VERSION ""

NS_ :

BS_:

BU_: EHR_Spare FEHR_3 PTO_SpeedSelector Dummy_Node_Ch2 FEHR_2 TrailerBrake OffBoardDiagnosticTool1_Ch2 PowerTakeOff_Ch2 Transmission1_Ch2 FEHR_1 REHR_5 REHR_4 REHR_3 REHR_2 REHR_1 InstrumentCluster_Ch2 ManagementComputer_Ch2 GWAY_OnBoardDiagnosticUnit_Ch2 GWAY_OffBoardDiagTool1_VB1_Ch2 GWAY_Engine1_Ch2 GWAY_CabDisplay1_Ch2 AuxiliaryValveControl_Ch2

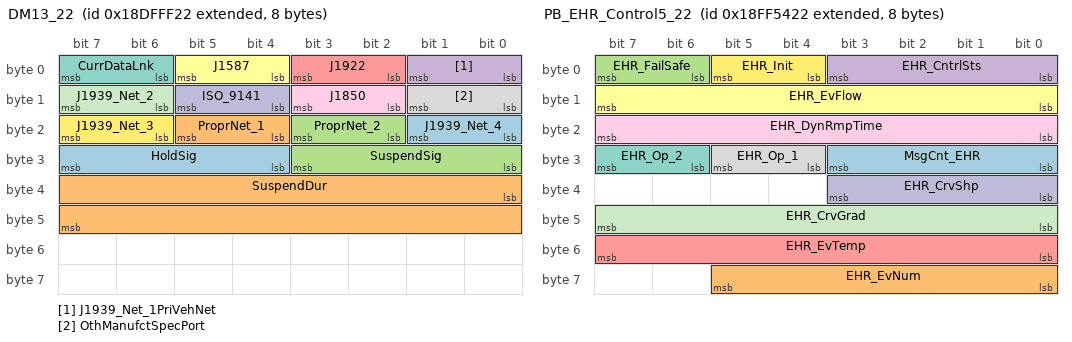
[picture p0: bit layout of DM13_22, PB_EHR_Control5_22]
BO_ 2564816674 DM13_22: 8 AuxiliaryValveControl_Ch2
 SG_ J1939_Net_4 : 16|2@1+ (1,0) [0|3] ""  FEHR_3,FEHR_2,FEHR_1,REHR_5,REHR_4,REHR_3,REHR_2,REHR_1
 SG_ SuspendDur : 32|16@1+ (1,0) [0|64255] "s"  FEHR_3,FEHR_2,FEHR_1,REHR_5,REHR_4,REHR_3,REHR_2,REHR_1
 SG_ SuspendSig : 24|4@1+ (1,0) [0|15] ""  FEHR_3,FEHR_2,FEHR_1,REHR_5,REHR_4,REHR_3,REHR_2,REHR_1
 SG_ J1939_Net_1PriVehNet : 0|2@1+ (1,0) [0|3] ""  FEHR_3,FEHR_2,FEHR_1,REHR_5,REHR_4,REHR_3,REHR_2,REHR_1
 SG_ J1922 : 2|2@1+ (1,0) [0|3] ""  FEHR_3,FEHR_2,FEHR_1,REHR_5,REHR_4,REHR_3,REHR_2,REHR_1
 SG_ J1587 : 4|2@1+ (1,0) [0|3] ""  FEHR_3,FEHR_2,FEHR_1,REHR_5,REHR_4,REHR_3,REHR_2,REHR_1
 SG_ CurrDataLnk : 6|2@1+ (1,0) [0|3] ""  FEHR_3,FEHR_2,FEHR_1,REHR_5,REHR_4,REHR_3,REHR_2,REHR_1
 SG_ OthManufctSpecPort : 8|2@1+ (1,0) [0|3] ""  FEHR_3,FEHR_2,FEHR_1,REHR_5,REHR_4,REHR_3,REHR_2,REHR_1
 SG_ J1850 : 10|2@1+ (1,0) [0|3] ""  FEHR_3,FEHR_2,FEHR_1,REHR_5,REHR_4,REHR_3,REHR_2,REHR_1
 SG_ ISO_9141 : 12|2@1+ (1,0) [0|3] ""  FEHR_3,FEHR_2,FEHR_1,REHR_5,REHR_4,REHR_3,REHR_2,REHR_1
 SG_ J1939_Net_2 : 14|2@1+ (1,0) [0|3] ""  FEHR_3,FEHR_2,FEHR_1,REHR_5,REHR_4,REHR_3,REHR_2,REHR_1
 SG_ J1939_Net_3 : 22|2@1+ (1,0) [0|3] ""  FEHR_3,FEHR_2,FEHR_1,REHR_5,REHR_4,REHR_3,REHR_2,REHR_1
 SG_ HoldSig : 28|4@1+ (1,0) [0|15] ""  FEHR_3,FEHR_2,FEHR_1,REHR_5,REHR_4,REHR_3,REHR_2,REHR_1
 SG_ ProprNet_1 : 20|2@1+ (1,0) [0|3] ""  FEHR_3,FEHR_2,FEHR_1,REHR_5,REHR_4,REHR_3,REHR_2,REHR_1
 SG_ ProprNet_2 : 18|2@1+ (1,0) [0|3] ""  FEHR_3,FEHR_2,FEHR_1,REHR_5,REHR_4,REHR_3,REHR_2,REHR_1

BO_ 2566865698 PB_EHR_ParameterControl_22: 8 AuxiliaryValveControl_Ch2
 SG_ EHR_Err_21_22 m19 : 21|1@1+ (1,0) [0|1] ""  FEHR_2,FEHR_1,REHR_5,REHR_4,REHR_3,REHR_2,REHR_1,FEHR_3
 SG_ EHR_Err_23 m19 : 22|1@1+ (1,0) [0|1] ""  FEHR_2,FEHR_1,REHR_5,REHR_4,REHR_3,REHR_2,REHR_1,FEHR_3
 SG_ EHR_EvNumNew m21 : 24|8@1+ (1,0) [0|255] ""  FEHR_2,FEHR_1,REHR_5,REHR_4,REHR_3,REHR_2,REHR_1,FEHR_3
 SG_ EHR_EvNumParamMux_12 m18 : 16|8@1+ (1,0) [0|255] ""  FEHR_2,FEHR_1,REHR_5,REHR_4,REHR_3,REHR_2,REHR_1,FEHR_3
 SG_ EHR_EvNumParamMux_15 m21 : 16|8@1+ (1,0) [0|255] ""  FEHR_2,FEHR_1,REHR_5,REHR_4,REHR_3,REHR_2,REHR_1,FEHR_3
 SG_ EHR_EvNumParamMux_31 m49 : 16|8@1+ (1,0) [0|255] ""  FEHR_2,FEHR_1,REHR_5,REHR_4,REHR_3,REHR_2,REHR_1,FEHR_3
 SG_ EHR_EvNumParamMux_32 m50 : 16|8@1+ (1,0) [0|255] ""  FEHR_2,FEHR_1,REHR_5,REHR_4,REHR_3,REHR_2,REHR_1,FEHR_3
 SG_ EHR_EvNumParamMux_50 m80 : 16|8@1+ (1,0) [0|255] ""  FEHR_2,FEHR_1,REHR_5,REHR_4,REHR_3,REHR_2,REHR_1,FEHR_3
 SG_ EHR_EvNumParamMux_67 m103 : 16|8@1+ (1,0) [0|255] ""  FEHR_2,FEHR_1,REHR_5,REHR_4,REHR_3,REHR_2,REHR_1,FEHR_3
 SG_ EHR_Op m19 : 24|1@1+ (1,0) [0|1] ""  FEHR_2,FEHR_1,REHR_5,REHR_4,REHR_3,REHR_2,REHR_1,FEHR_3
 SG_ EHR_PotentmtrRng_10V m19 : 27|1@1+ (1,0) [0|1] ""  FEHR_2,FEHR_1,REHR_5,REHR_4,REHR_3,REHR_2,REHR_1,FEHR_3
 SG_ EHR_PotentOp m19 : 25|1@1+ (1,0) [0|1] ""  FEHR_2,FEHR_1,REHR_5,REHR_4,REHR_3,REHR_2,REHR_1,FEHR_3
 SG_ EHR_PWM_Op m19 : 26|1@1+ (1,0) [0|1] ""  FEHR_2,FEHR_1,REHR_5,REHR_4,REHR_3,REHR_2,REHR_1,FEHR_3
 SG_ EHR_RmpRndng m103 : 24|8@1+ (1,0) [0|255] ""  FEHR_2,FEHR_1,REHR_5,REHR_4,REHR_3,REHR_2,REHR_1,FEHR_3
 SG_ EHR_ParamByte_1 : 0|8@1+ (1,0) [0|255] ""  FEHR_3,FEHR_2,FEHR_1,REHR_5,REHR_4,REHR_3,REHR_2,REHR_1
 SG_ EHR_ParamByte_2 M : 8|8@1+ (1,0) [0|255] ""  FEHR_3,FEHR_2,FEHR_1,REHR_5,REHR_4,REHR_3,REHR_2,REHR_1

BO_ 2566870050 PB_EHR_Control5_22: 8 AuxiliaryValveControl_Ch2
 SG_ MsgCnt_EHR : 24|4@1+ (1,0) [0|12] "count"  REHR_5
 SG_ EHR_EvNum : 56|6@1+ (1,0) [0|63] "" Vector__XXX
 SG_ EHR_FailSafe : 6|2@1+ (1,0) [0|3] ""  REHR_5
 SG_ EHR_CntrlSts : 0|4@1+ (1,0) [0|15] ""  REHR_5
 SG_ EHR_EvTemp : 48|8@1+ (1,-80) [-40|120] "Deg C"  REHR_5
 SG_ EHR_EvFlow : 8|8@1+ (0.3937,0) [0|100] "%"  REHR_5
 SG_ EHR_Op_2 : 30|2@1+ (1,0) [0|3] ""  REHR_5
 SG_ EHR_Op_1 : 28|2@1+ (1,0) [0|3] ""  REHR_5
 SG_ EHR_DynRmpTime : 16|8@1+ (32,0) [0|8128] "ms"  REHR_5
 SG_ EHR_CrvShp : 32|4@1+ (1,0) [0|15] ""  REHR_5
 SG_ EHR_CrvGrad : 40|8@1+ (0.3922,0) [0|100] "%"  REHR_5
 SG_ EHR_Init : 4|2@1+ (1,0) [0|3] ""  REHR_5

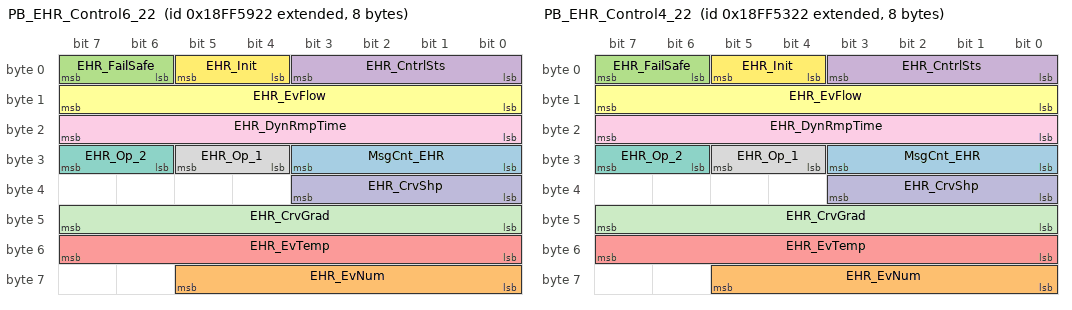
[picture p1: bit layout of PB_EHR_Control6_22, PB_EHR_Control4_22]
BO_ 2566871330 PB_EHR_Control6_22: 8 AuxiliaryValveControl_Ch2
 SG_ MsgCnt_EHR : 24|4@1+ (1,0) [0|12] "count"  FEHR_1
 SG_ EHR_EvNum : 56|6@1+ (1,0) [0|63] "" Vector__XXX
 SG_ EHR_FailSafe : 6|2@1+ (1,0) [0|3] ""  FEHR_1
 SG_ EHR_CntrlSts : 0|4@1+ (1,0) [0|15] ""  FEHR_1
 SG_ EHR_EvTemp : 48|8@1+ (1,-80) [-40|120] "Deg C"  FEHR_1
 SG_ EHR_EvFlow : 8|8@1+ (0.3937,0) [0|100] "%"  FEHR_1
 SG_ EHR_Op_2 : 30|2@1+ (1,0) [0|3] ""  FEHR_1
 SG_ EHR_Op_1 : 28|2@1+ (1,0) [0|3] ""  FEHR_1
 SG_ EHR_DynRmpTime : 16|8@1+ (32,0) [0|8128] "ms"  FEHR_1
 SG_ EHR_CrvShp : 32|4@1+ (1,0) [0|15] ""  FEHR_1
 SG_ EHR_CrvGrad : 40|8@1+ (0.3922,0) [0|100] "%"  FEHR_1
 SG_ EHR_Init : 4|2@1+ (1,0) [0|3] ""  FEHR_1

BO_ 2566869794 PB_EHR_Control4_22: 8 AuxiliaryValveControl_Ch2
 SG_ MsgCnt_EHR : 24|4@1+ (1,0) [0|12] "count"  REHR_4
 SG_ EHR_EvNum : 56|6@1+ (1,0) [0|63] "" Vector__XXX
 SG_ EHR_FailSafe : 6|2@1+ (1,0) [0|3] ""  REHR_4
 SG_ EHR_CntrlSts : 0|4@1+ (1,0) [0|15] ""  REHR_4
 SG_ EHR_EvTemp : 48|8@1+ (1,-80) [-40|120] "Deg C"  REHR_4
 SG_ EHR_EvFlow : 8|8@1+ (0.3937,0) [0|100] "%"  REHR_4
 SG_ EHR_Op_2 : 30|2@1+ (1,0) [0|3] ""  REHR_4
 SG_ EHR_Op_1 : 28|2@1+ (1,0) [0|3] ""  REHR_4
 SG_ EHR_DynRmpTime : 16|8@1+ (32,0) [0|8128] "ms"  REHR_4
 SG_ EHR_CrvShp : 32|4@1+ (1,0) [0|15] ""  REHR_4
 SG_ EHR_CrvGrad : 40|8@1+ (0.3922,0) [0|100] "%"  REHR_4
 SG_ EHR_Init : 4|2@1+ (1,0) [0|3] ""  REHR_4

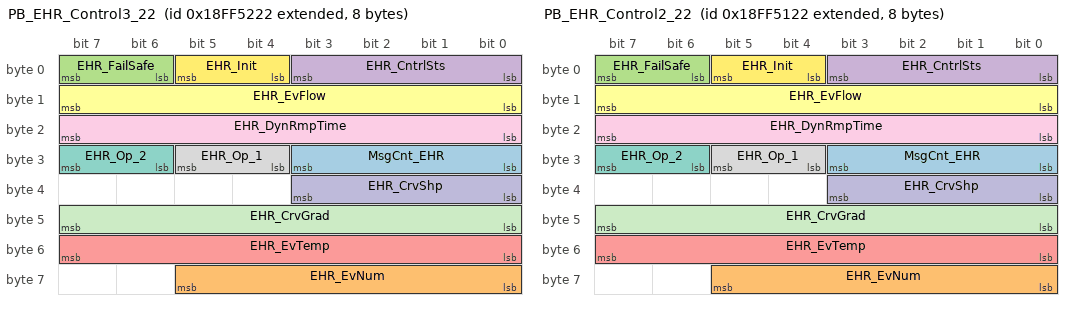
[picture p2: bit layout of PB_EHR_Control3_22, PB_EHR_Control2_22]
BO_ 2566869538 PB_EHR_Control3_22: 8 AuxiliaryValveControl_Ch2
 SG_ MsgCnt_EHR : 24|4@1+ (1,0) [0|12] "count"  REHR_3
 SG_ EHR_EvNum : 56|6@1+ (1,0) [0|63] "" Vector__XXX
 SG_ EHR_FailSafe : 6|2@1+ (1,0) [0|3] ""  REHR_3
 SG_ EHR_CntrlSts : 0|4@1+ (1,0) [0|15] ""  REHR_3
 SG_ EHR_EvTemp : 48|8@1+ (1,-80) [-40|120] "Deg C"  REHR_3
 SG_ EHR_EvFlow : 8|8@1+ (0.3937,0) [0|100] "%"  REHR_3
 SG_ EHR_Op_2 : 30|2@1+ (1,0) [0|3] ""  REHR_3
 SG_ EHR_Op_1 : 28|2@1+ (1,0) [0|3] ""  REHR_3
 SG_ EHR_DynRmpTime : 16|8@1+ (32,0) [0|8128] "ms"  REHR_3
 SG_ EHR_CrvShp : 32|4@1+ (1,0) [0|15] ""  REHR_3
 SG_ EHR_CrvGrad : 40|8@1+ (0.3922,0) [0|100] "%"  REHR_3
 SG_ EHR_Init : 4|2@1+ (1,0) [0|3] ""  REHR_3

BO_ 2566869282 PB_EHR_Control2_22: 8 AuxiliaryValveControl_Ch2
 SG_ MsgCnt_EHR : 24|4@1+ (1,0) [0|12] "count"  REHR_2
 SG_ EHR_EvNum : 56|6@1+ (1,0) [0|63] "" Vector__XXX
 SG_ EHR_FailSafe : 6|2@1+ (1,0) [0|3] ""  REHR_2
 SG_ EHR_CntrlSts : 0|4@1+ (1,0) [0|15] ""  REHR_2
 SG_ EHR_EvTemp : 48|8@1+ (1,-80) [-40|120] "Deg C"  REHR_2
 SG_ EHR_EvFlow : 8|8@1+ (0.3937,0) [0|100] "%"  REHR_2
 SG_ EHR_Op_2 : 30|2@1+ (1,0) [0|3] ""  REHR_2
 SG_ EHR_Op_1 : 28|2@1+ (1,0) [0|3] ""  REHR_2
 SG_ EHR_DynRmpTime : 16|8@1+ (32,0) [0|8128] "ms"  REHR_2
 SG_ EHR_CrvShp : 32|4@1+ (1,0) [0|15] ""  REHR_2
 SG_ EHR_CrvGrad : 40|8@1+ (0.3922,0) [0|100] "%"  REHR_2
 SG_ EHR_Init : 4|2@1+ (1,0) [0|3] ""  REHR_2

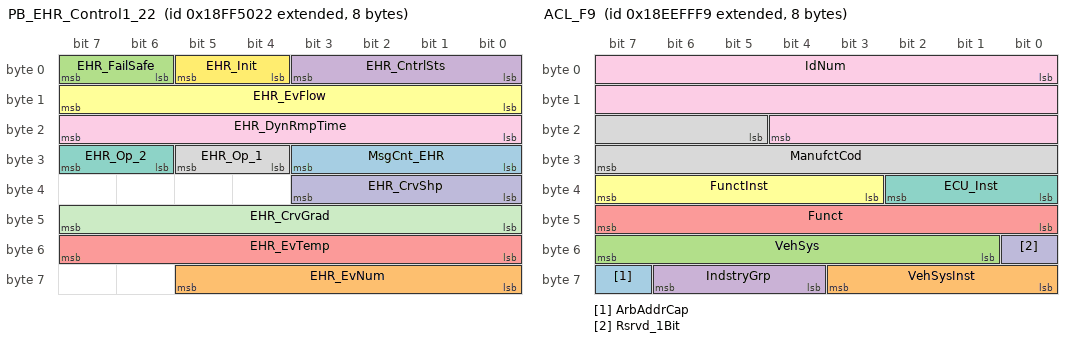
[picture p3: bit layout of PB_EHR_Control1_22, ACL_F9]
BO_ 2566869026 PB_EHR_Control1_22: 8 AuxiliaryValveControl_Ch2
 SG_ MsgCnt_EHR : 24|4@1+ (1,0) [0|12] "count"  REHR_1
 SG_ EHR_EvNum : 56|6@1+ (1,0) [0|63] "" Vector__XXX
 SG_ EHR_FailSafe : 6|2@1+ (1,0) [0|3] ""  REHR_1
 SG_ EHR_CntrlSts : 0|4@1+ (1,0) [0|15] ""  REHR_1
 SG_ EHR_EvTemp : 48|8@1+ (1,-80) [-40|120] "Deg C"  REHR_1
 SG_ EHR_EvFlow : 8|8@1+ (0.3937,0) [0|100] "%"  REHR_1
 SG_ EHR_Op_2 : 30|2@1+ (1,0) [0|3] ""  REHR_1
 SG_ EHR_Op_1 : 28|2@1+ (1,0) [0|3] ""  REHR_1
 SG_ EHR_DynRmpTime : 16|8@1+ (32,0) [0|8128] "ms"  REHR_1
 SG_ EHR_CrvShp : 32|4@1+ (1,0) [0|15] ""  REHR_1
 SG_ EHR_CrvGrad : 40|8@1+ (0.3922,0) [0|100] "%"  REHR_1
 SG_ EHR_Init : 4|2@1+ (1,0) [0|3] ""  REHR_1

BO_ 2565537570 RQST_22: 3 AuxiliaryValveControl_Ch2
 SG_ PGN_RQST_22 : 0|24@1+ (1,0) [0|16777200] ""  FEHR_3,FEHR_2,FEHR_1,REHR_5,REHR_4,REHR_3,REHR_2,REHR_1

BO_ 2566841634 HOURS_22: 8 AuxiliaryValveControl_Ch2
 SG_ EngTotHourOp : 0|32@1+ (0.05,0) [0|210554000] "h"  FEHR_3,FEHR_2,FEHR_1,REHR_5,REHR_4,REHR_3,REHR_2,REHR_1
 SG_ EngTotRevol : 32|32@1+ (1000,0) [0|4.21108E+22] "r"  FEHR_3,FEHR_2,FEHR_1,REHR_5,REHR_4,REHR_3,REHR_2,REHR_1

BO_ 2564432633 ISO15765_Phys_F9_22: 8 OffBoardDiagnosticTool1_Ch2
 SG_ BlkSize m3 : 8|8@1+ (1,0) [0|255] "" Vector__XXX
 SG_ FlowSts m3 : 0|4@1+ (1,0) [0|3] ""  AuxiliaryValveControl_Ch2
 SG_ N1FrameDataLen m1 : 3|12@0+ (1,0) [0|4095] "Byte"  AuxiliaryValveControl_Ch2
 SG_ ProtocCntrlInfo M : 4|4@1+ (1,0) [0|3] ""  AuxiliaryValveControl_Ch2
 SG_ SepTime m3 : 16|8@1+ (1,0) [0|255] "ms"  AuxiliaryValveControl_Ch2
 SG_ SingFrameDataLen m0 : 0|4@1+ (1,0) [0|7] "Byte"  AuxiliaryValveControl_Ch2
 SG_ SN m2 : 0|4@1+ (1,0) [0|15] ""  AuxiliaryValveControl_Ch2

BO_ 2564487458 ISO15765_Phys_22_F9: 8 AuxiliaryValveControl_Ch2
 SG_ ProtocCntrlInfo M : 4|4@1+ (1,0) [0|3] ""  OffBoardDiagnosticTool1_Ch2
 SG_ SingFrameDataLen m0 : 0|4@1+ (1,0) [0|7] "Byte"  OffBoardDiagnosticTool1_Ch2
 SG_ N1FrameDataLen m1 : 3|12@0+ (1,0) [0|4095] "Byte"  OffBoardDiagnosticTool1_Ch2
 SG_ FlowSts m3 : 0|4@1+ (1,0) [0|3] ""  OffBoardDiagnosticTool1_Ch2
 SG_ BlkSize m3 : 8|8@1+ (1,0) [0|255] ""  OffBoardDiagnosticTool1_Ch2
 SG_ SepTime m3 : 16|8@1+ (1,0) [0|255] "ms"  OffBoardDiagnosticTool1_Ch2
 SG_ SN m2 : 0|4@1+ (1,0) [0|15] ""  OffBoardDiagnosticTool1_Ch2

BO_ 2565799929 ACL_F9: 8 GWAY_OffBoardDiagTool1_VB1_Ch2
 SG_ ArbAddrCap : 63|1@1+ (1,0) [0|1] ""  Dummy_Node_Ch2
 SG_ VehSysInst : 56|4@1+ (1,0) [0|15] ""  Dummy_Node_Ch2
 SG_ VehSys : 49|7@1+ (1,0) [0|127] ""  Dummy_Node_Ch2
 SG_ IndstryGrp : 60|3@1+ (1,0) [0|7] ""  Dummy_Node_Ch2
 SG_ Funct : 40|8@1+ (1,0) [0|255] ""  Dummy_Node_Ch2
 SG_ FunctInst : 35|5@1+ (1,0) [0|31] ""  Dummy_Node_Ch2
 SG_ ECU_Inst : 32|3@1+ (1,0) [0|7] ""  Dummy_Node_Ch2
 SG_ ManufctCod : 21|11@1+ (1,0) [0|2047] ""  Dummy_Node_Ch2
 SG_ IdNum : 0|21@1+ (1,0) [0|2097151] ""  Dummy_Node_Ch2
 SG_ Rsrvd_1Bit : 48|1@1+ (1,0) [0|1] ""  Dummy_Node_Ch2

BO_ 2565537785 RQST_F9: 3 GWAY_OffBoardDiagTool1_VB1_Ch2
 SG_ PGN_RQST_F9 : 0|24@1+ (1,0) [0|16777200] ""  FEHR_3,Dummy_Node_Ch2,FEHR_2,FEHR_1,REHR_5,REHR_4,REHR_3,REHR_2,REHR_1

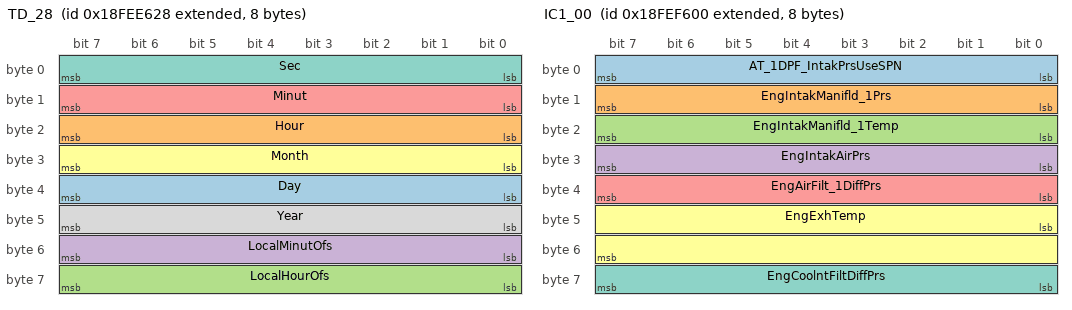
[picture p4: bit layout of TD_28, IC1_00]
BO_ 2566841896 TD_28: 8 GWAY_CabDisplay1_Ch2
 SG_ Day : 32|8@1+ (0.25,0) [0|62.5] "days"  TrailerBrake
 SG_ Hour : 16|8@1+ (1,0) [0|250] "h"  TrailerBrake
 SG_ LocalHourOfs : 56|8@1+ (1,-125) [-125|125] "h"  TrailerBrake
 SG_ LocalMinutOfs : 48|8@1+ (1,-125) [-125|125] "min"  TrailerBrake
 SG_ Minut : 8|8@1+ (1,0) [0|250] "min"  TrailerBrake
 SG_ Month : 24|8@1+ (1,0) [0|250] "months"  TrailerBrake
 SG_ Sec : 0|8@1+ (0.25,0) [0|62.5] "s"  TrailerBrake
 SG_ Year : 40|8@1+ (1,1985) [1985|2235] "years"  TrailerBrake

BO_ 2564459001 ISO15765_Phys_F9_89: 8 OffBoardDiagnosticTool1_Ch2
 SG_ BlkSize m3 : 8|8@1+ (1,0) [0|255] ""  FEHR_1
 SG_ FlowSts m3 : 0|4@1+ (1,0) [0|3] ""  FEHR_1
 SG_ N1FrameDataLen m1 : 3|12@0+ (1,0) [0|4095] "Byte"  FEHR_1
 SG_ ProtocCntrlInfo M : 4|4@1+ (1,0) [0|3] ""  FEHR_1
 SG_ SepTime m3 : 16|8@1+ (1,0) [0|255] "ms"  FEHR_1
 SG_ SingFrameDataLen m0 : 0|4@1+ (1,0) [0|7] "Byte"  FEHR_1
 SG_ SN m2 : 0|4@1+ (1,0) [0|15] ""  FEHR_1

BO_ 2566843273 CI_89: 38 FEHR_1
 SG_ UnitNumPwrUnit : 208|8@1+ (1,0) [0|255] "ASCII"  Dummy_Node_Ch2
 SG_ SN_2_Byte_15 : 200|8@1+ (1,0) [0|255] "per byte"  Dummy_Node_Ch2
 SG_ SN_2_Byte_14 : 192|8@1+ (1,0) [0|255] "per byte"  Dummy_Node_Ch2
 SG_ SN_2_Byte_13 : 184|8@1+ (1,0) [0|255] "per byte"  Dummy_Node_Ch2
 SG_ SN_2_Byte_12 : 176|8@1+ (1,0) [0|255] "per byte"  Dummy_Node_Ch2
 SG_ SN_2_Byte_11 : 168|8@1+ (1,0) [0|255] "per byte"  Dummy_Node_Ch2
 SG_ SN_2_Byte_10 : 160|8@1+ (1,0) [0|255] "per byte"  Dummy_Node_Ch2
 SG_ SN_2_Byte_09 : 152|8@1+ (1,0) [0|255] "per byte"  Dummy_Node_Ch2
 SG_ SN_2_Byte_08 : 144|8@1+ (1,0) [0|255] "per byte"  Dummy_Node_Ch2
 SG_ SN_2_Byte_07 : 136|8@1+ (1,0) [0|255] "per byte"  Dummy_Node_Ch2
 SG_ SN_2_Byte_06 : 128|8@1+ (1,0) [0|255] "per byte"  Dummy_Node_Ch2
 SG_ SN_2_Byte_05 : 120|8@1+ (1,0) [0|255] "per byte"  Dummy_Node_Ch2
 SG_ SN_2_Byte_04 : 112|8@1+ (1,0) [0|255] "per byte"  Dummy_Node_Ch2
 SG_ SN_2_Byte_03 : 104|8@1+ (1,0) [0|255] "per byte"  Dummy_Node_Ch2
 SG_ SN_2_Byte_02 : 96|8@1+ (1,0) [0|255] "per byte"  Dummy_Node_Ch2
 SG_ SN_2_Byte_01 : 88|8@1+ (1,0) [0|255] "per byte"  Dummy_Node_Ch2
 SG_ SN_2 : 80|8@1+ (1,0) [0|255] "ASCII"  Dummy_Node_Ch2
 SG_ Mdl_Byte_08 : 72|8@1+ (1,0) [0|255] "ASCII"  Dummy_Node_Ch2
 SG_ Mdl_Byte_07 : 64|8@1+ (1,0) [0|255] "ASCII"  Dummy_Node_Ch2
 SG_ Mdl_Byte_06 : 56|8@1+ (1,0) [0|255] "ASCII"  Dummy_Node_Ch2
 SG_ Mdl_Byte_05 : 48|8@1+ (1,0) [0|255] "ASCII"  Dummy_Node_Ch2
 SG_ Mdl_Byte_04 : 40|8@1+ (1,0) [0|255] "ASCII"  Dummy_Node_Ch2
 SG_ Mdl_Byte_03 : 32|8@1+ (1,0) [0|255] "ASCII"  Dummy_Node_Ch2
 SG_ Mdl_Byte_02 : 24|8@1+ (1,0) [0|255] "ASCII"  Dummy_Node_Ch2
 SG_ Mdl_Byte_01 : 16|8@1+ (1,0) [0|255] "ASCII"  Dummy_Node_Ch2
 SG_ Make : 0|8@1+ (1,0) [0|255] "ASCII"  Dummy_Node_Ch2
 SG_ Mdl : 8|8@1+ (1,0) [0|255] "ASCII"  Dummy_Node_Ch2

BO_ 2564487561 ISO15765_Phys_89_F9: 8 FEHR_1
 SG_ SepTime m3 : 16|8@1+ (1,0) [0|255] "ms"  OffBoardDiagnosticTool1_Ch2
 SG_ SingFrameDataLen m0 : 0|4@1+ (1,0) [0|7] "Byte"  OffBoardDiagnosticTool1_Ch2
 SG_ N1FrameDataLen m1 : 3|12@0+ (1,0) [0|4095] "Byte"  OffBoardDiagnosticTool1_Ch2
 SG_ BlkSize m3 : 8|8@1+ (1,0) [0|255] ""  OffBoardDiagnosticTool1_Ch2
 SG_ FlowSts m3 : 0|4@1+ (1,0) [0|3] ""  OffBoardDiagnosticTool1_Ch2
 SG_ SN m2 : 0|4@1+ (1,0) [0|15] ""  OffBoardDiagnosticTool1_Ch2
 SG_ ProtocCntrlInfo M : 4|4@1+ (1,0) [0|3] ""  OffBoardDiagnosticTool1_Ch2

BO_ 2564457721 ISO15765_Phys_F9_84: 8 OffBoardDiagnosticTool1_Ch2
 SG_ BlkSize m3 : 8|8@1+ (1,0) [0|255] ""  REHR_5
 SG_ FlowSts m3 : 0|4@1+ (1,0) [0|3] ""  REHR_5
 SG_ N1FrameDataLen m1 : 3|12@0+ (1,0) [0|4095] "Byte"  REHR_5
 SG_ ProtocCntrlInfo M : 4|4@1+ (1,0) [0|3] ""  REHR_5
 SG_ SepTime m3 : 16|8@1+ (1,0) [0|255] "ms"  REHR_5
 SG_ SingFrameDataLen m0 : 0|4@1+ (1,0) [0|7] "Byte"  REHR_5
 SG_ SN m2 : 0|4@1+ (1,0) [0|15] ""  REHR_5

BO_ 2566843268 CI_84: 38 REHR_5
 SG_ UnitNumPwrUnit : 208|8@1+ (1,0) [0|255] "ASCII"  Dummy_Node_Ch2
 SG_ SN_2_Byte_15 : 200|8@1+ (1,0) [0|255] "per byte"  Dummy_Node_Ch2
 SG_ SN_2_Byte_14 : 192|8@1+ (1,0) [0|255] "per byte"  Dummy_Node_Ch2
 SG_ SN_2_Byte_13 : 184|8@1+ (1,0) [0|255] "per byte"  Dummy_Node_Ch2
 SG_ SN_2_Byte_12 : 176|8@1+ (1,0) [0|255] "per byte"  Dummy_Node_Ch2
 SG_ SN_2_Byte_11 : 168|8@1+ (1,0) [0|255] "per byte"  Dummy_Node_Ch2
 SG_ SN_2_Byte_10 : 160|8@1+ (1,0) [0|255] "per byte"  Dummy_Node_Ch2
 SG_ SN_2_Byte_09 : 152|8@1+ (1,0) [0|255] "per byte"  Dummy_Node_Ch2
 SG_ SN_2_Byte_08 : 144|8@1+ (1,0) [0|255] "per byte"  Dummy_Node_Ch2
 SG_ SN_2_Byte_07 : 136|8@1+ (1,0) [0|255] "per byte"  Dummy_Node_Ch2
 SG_ SN_2_Byte_06 : 128|8@1+ (1,0) [0|255] "per byte"  Dummy_Node_Ch2
 SG_ SN_2_Byte_05 : 120|8@1+ (1,0) [0|255] "per byte"  Dummy_Node_Ch2
 SG_ SN_2_Byte_04 : 112|8@1+ (1,0) [0|255] "per byte"  Dummy_Node_Ch2
 SG_ SN_2_Byte_03 : 104|8@1+ (1,0) [0|255] "per byte"  Dummy_Node_Ch2
 SG_ SN_2_Byte_02 : 96|8@1+ (1,0) [0|255] "per byte"  Dummy_Node_Ch2
 SG_ SN_2_Byte_01 : 88|8@1+ (1,0) [0|255] "per byte"  Dummy_Node_Ch2
 SG_ SN_2 : 80|8@1+ (1,0) [0|255] "ASCII"  Dummy_Node_Ch2
 SG_ Mdl_Byte_08 : 72|8@1+ (1,0) [0|255] "ASCII"  Dummy_Node_Ch2
 SG_ Mdl_Byte_07 : 64|8@1+ (1,0) [0|255] "ASCII"  Dummy_Node_Ch2
 SG_ Mdl_Byte_06 : 56|8@1+ (1,0) [0|255] "ASCII"  Dummy_Node_Ch2
 SG_ Mdl_Byte_05 : 48|8@1+ (1,0) [0|255] "ASCII"  Dummy_Node_Ch2
 SG_ Mdl_Byte_04 : 40|8@1+ (1,0) [0|255] "ASCII"  Dummy_Node_Ch2
 SG_ Mdl_Byte_03 : 32|8@1+ (1,0) [0|255] "ASCII"  Dummy_Node_Ch2
 SG_ Mdl_Byte_02 : 24|8@1+ (1,0) [0|255] "ASCII"  Dummy_Node_Ch2
 SG_ Mdl_Byte_01 : 16|8@1+ (1,0) [0|255] "ASCII"  Dummy_Node_Ch2
 SG_ Make : 0|8@1+ (1,0) [0|255] "ASCII"  Dummy_Node_Ch2
 SG_ Mdl : 8|8@1+ (1,0) [0|255] "ASCII"  Dummy_Node_Ch2

BO_ 2564487556 ISO15765_Phys_84_F9: 8 REHR_5
 SG_ SepTime m3 : 16|8@1+ (1,0) [0|255] "ms"  OffBoardDiagnosticTool1_Ch2
 SG_ SingFrameDataLen m0 : 0|4@1+ (1,0) [0|7] "Byte"  OffBoardDiagnosticTool1_Ch2
 SG_ N1FrameDataLen m1 : 3|12@0+ (1,0) [0|4095] "Byte"  OffBoardDiagnosticTool1_Ch2
 SG_ BlkSize m3 : 8|8@1+ (1,0) [0|255] ""  OffBoardDiagnosticTool1_Ch2
 SG_ FlowSts m3 : 0|4@1+ (1,0) [0|3] ""  OffBoardDiagnosticTool1_Ch2
 SG_ SN m2 : 0|4@1+ (1,0) [0|15] ""  OffBoardDiagnosticTool1_Ch2
 SG_ ProtocCntrlInfo M : 4|4@1+ (1,0) [0|3] ""  OffBoardDiagnosticTool1_Ch2

BO_ 2564457465 ISO15765_Phys_F9_83: 8 OffBoardDiagnosticTool1_Ch2
 SG_ BlkSize m3 : 8|8@1+ (1,0) [0|255] ""  REHR_4
 SG_ FlowSts m3 : 0|4@1+ (1,0) [0|3] ""  REHR_4
 SG_ N1FrameDataLen m1 : 3|12@0+ (1,0) [0|4095] "Byte"  REHR_4
 SG_ ProtocCntrlInfo M : 4|4@1+ (1,0) [0|3] ""  REHR_4
 SG_ SepTime m3 : 16|8@1+ (1,0) [0|255] "ms"  REHR_4
 SG_ SingFrameDataLen m0 : 0|4@1+ (1,0) [0|7] "Byte"  REHR_4
 SG_ SN m2 : 0|4@1+ (1,0) [0|15] ""  REHR_4

BO_ 2566843267 CI_83: 38 REHR_4
 SG_ UnitNumPwrUnit : 208|8@1+ (1,0) [0|255] "ASCII"  Dummy_Node_Ch2
 SG_ SN_2_Byte_15 : 200|8@1+ (1,0) [0|255] "per byte"  Dummy_Node_Ch2
 SG_ SN_2_Byte_14 : 192|8@1+ (1,0) [0|255] "per byte"  Dummy_Node_Ch2
 SG_ SN_2_Byte_13 : 184|8@1+ (1,0) [0|255] "per byte"  Dummy_Node_Ch2
 SG_ SN_2_Byte_12 : 176|8@1+ (1,0) [0|255] "per byte"  Dummy_Node_Ch2
 SG_ SN_2_Byte_11 : 168|8@1+ (1,0) [0|255] "per byte"  Dummy_Node_Ch2
 SG_ SN_2_Byte_10 : 160|8@1+ (1,0) [0|255] "per byte"  Dummy_Node_Ch2
 SG_ SN_2_Byte_09 : 152|8@1+ (1,0) [0|255] "per byte"  Dummy_Node_Ch2
 SG_ SN_2_Byte_08 : 144|8@1+ (1,0) [0|255] "per byte"  Dummy_Node_Ch2
 SG_ SN_2_Byte_07 : 136|8@1+ (1,0) [0|255] "per byte"  Dummy_Node_Ch2
 SG_ SN_2_Byte_06 : 128|8@1+ (1,0) [0|255] "per byte"  Dummy_Node_Ch2
 SG_ SN_2_Byte_05 : 120|8@1+ (1,0) [0|255] "per byte"  Dummy_Node_Ch2
 SG_ SN_2_Byte_04 : 112|8@1+ (1,0) [0|255] "per byte"  Dummy_Node_Ch2
 SG_ SN_2_Byte_03 : 104|8@1+ (1,0) [0|255] "per byte"  Dummy_Node_Ch2
 SG_ SN_2_Byte_02 : 96|8@1+ (1,0) [0|255] "per byte"  Dummy_Node_Ch2
 SG_ SN_2_Byte_01 : 88|8@1+ (1,0) [0|255] "per byte"  Dummy_Node_Ch2
 SG_ SN_2 : 80|8@1+ (1,0) [0|255] "ASCII"  Dummy_Node_Ch2
 SG_ Mdl_Byte_08 : 72|8@1+ (1,0) [0|255] "ASCII"  Dummy_Node_Ch2
 SG_ Mdl_Byte_07 : 64|8@1+ (1,0) [0|255] "ASCII"  Dummy_Node_Ch2
 SG_ Mdl_Byte_06 : 56|8@1+ (1,0) [0|255] "ASCII"  Dummy_Node_Ch2
 SG_ Mdl_Byte_05 : 48|8@1+ (1,0) [0|255] "ASCII"  Dummy_Node_Ch2
 SG_ Mdl_Byte_04 : 40|8@1+ (1,0) [0|255] "ASCII"  Dummy_Node_Ch2
 SG_ Mdl_Byte_03 : 32|8@1+ (1,0) [0|255] "ASCII"  Dummy_Node_Ch2
 SG_ Mdl_Byte_02 : 24|8@1+ (1,0) [0|255] "ASCII"  Dummy_Node_Ch2
 SG_ Mdl_Byte_01 : 16|8@1+ (1,0) [0|255] "ASCII"  Dummy_Node_Ch2
 SG_ Make : 0|8@1+ (1,0) [0|255] "ASCII"  Dummy_Node_Ch2
 SG_ Mdl : 8|8@1+ (1,0) [0|255] "ASCII"  Dummy_Node_Ch2

BO_ 2564487555 ISO15765_Phys_83_F9: 8 REHR_4
 SG_ SepTime m3 : 16|8@1+ (1,0) [0|255] "ms"  OffBoardDiagnosticTool1_Ch2
 SG_ SingFrameDataLen m0 : 0|4@1+ (1,0) [0|7] "Byte"  OffBoardDiagnosticTool1_Ch2
 SG_ N1FrameDataLen m1 : 3|12@0+ (1,0) [0|4095] "Byte"  OffBoardDiagnosticTool1_Ch2
 SG_ BlkSize m3 : 8|8@1+ (1,0) [0|255] ""  OffBoardDiagnosticTool1_Ch2
 SG_ FlowSts m3 : 0|4@1+ (1,0) [0|3] ""  OffBoardDiagnosticTool1_Ch2
 SG_ SN m2 : 0|4@1+ (1,0) [0|15] ""  OffBoardDiagnosticTool1_Ch2
 SG_ ProtocCntrlInfo M : 4|4@1+ (1,0) [0|3] ""  OffBoardDiagnosticTool1_Ch2

BO_ 2564457209 ISO15765_Phys_F9_82: 8 OffBoardDiagnosticTool1_Ch2
 SG_ BlkSize m3 : 8|8@1+ (1,0) [0|255] ""  REHR_3
 SG_ FlowSts m3 : 0|4@1+ (1,0) [0|3] ""  REHR_3
 SG_ N1FrameDataLen m1 : 3|12@0+ (1,0) [0|4095] "Byte"  REHR_3
 SG_ ProtocCntrlInfo M : 4|4@1+ (1,0) [0|3] ""  REHR_3
 SG_ SepTime m3 : 16|8@1+ (1,0) [0|255] "ms"  REHR_3
 SG_ SingFrameDataLen m0 : 0|4@1+ (1,0) [0|7] "Byte"  REHR_3
 SG_ SN m2 : 0|4@1+ (1,0) [0|15] ""  REHR_3

BO_ 2566843266 CI_82: 38 REHR_3
 SG_ UnitNumPwrUnit : 208|8@1+ (1,0) [0|255] "ASCII"  Dummy_Node_Ch2
 SG_ SN_2_Byte_15 : 200|8@1+ (1,0) [0|255] "per byte"  Dummy_Node_Ch2
 SG_ SN_2_Byte_14 : 192|8@1+ (1,0) [0|255] "per byte"  Dummy_Node_Ch2
 SG_ SN_2_Byte_13 : 184|8@1+ (1,0) [0|255] "per byte"  Dummy_Node_Ch2
 SG_ SN_2_Byte_12 : 176|8@1+ (1,0) [0|255] "per byte"  Dummy_Node_Ch2
 SG_ SN_2_Byte_11 : 168|8@1+ (1,0) [0|255] "per byte"  Dummy_Node_Ch2
 SG_ SN_2_Byte_10 : 160|8@1+ (1,0) [0|255] "per byte"  Dummy_Node_Ch2
 SG_ SN_2_Byte_09 : 152|8@1+ (1,0) [0|255] "per byte"  Dummy_Node_Ch2
 SG_ SN_2_Byte_08 : 144|8@1+ (1,0) [0|255] "per byte"  Dummy_Node_Ch2
 SG_ SN_2_Byte_07 : 136|8@1+ (1,0) [0|255] "per byte"  Dummy_Node_Ch2
 SG_ SN_2_Byte_06 : 128|8@1+ (1,0) [0|255] "per byte"  Dummy_Node_Ch2
 SG_ SN_2_Byte_05 : 120|8@1+ (1,0) [0|255] "per byte"  Dummy_Node_Ch2
 SG_ SN_2_Byte_04 : 112|8@1+ (1,0) [0|255] "per byte"  Dummy_Node_Ch2
 SG_ SN_2_Byte_03 : 104|8@1+ (1,0) [0|255] "per byte"  Dummy_Node_Ch2
 SG_ SN_2_Byte_02 : 96|8@1+ (1,0) [0|255] "per byte"  Dummy_Node_Ch2
 SG_ SN_2_Byte_01 : 88|8@1+ (1,0) [0|255] "per byte"  Dummy_Node_Ch2
 SG_ SN_2 : 80|8@1+ (1,0) [0|255] "ASCII"  Dummy_Node_Ch2
 SG_ Mdl_Byte_08 : 72|8@1+ (1,0) [0|255] "ASCII"  Dummy_Node_Ch2
 SG_ Mdl_Byte_07 : 64|8@1+ (1,0) [0|255] "ASCII"  Dummy_Node_Ch2
 SG_ Mdl_Byte_06 : 56|8@1+ (1,0) [0|255] "ASCII"  Dummy_Node_Ch2
 SG_ Mdl_Byte_05 : 48|8@1+ (1,0) [0|255] "ASCII"  Dummy_Node_Ch2
 SG_ Mdl_Byte_04 : 40|8@1+ (1,0) [0|255] "ASCII"  Dummy_Node_Ch2
 SG_ Mdl_Byte_03 : 32|8@1+ (1,0) [0|255] "ASCII"  Dummy_Node_Ch2
 SG_ Mdl_Byte_02 : 24|8@1+ (1,0) [0|255] "ASCII"  Dummy_Node_Ch2
 SG_ Mdl_Byte_01 : 16|8@1+ (1,0) [0|255] "ASCII"  Dummy_Node_Ch2
 SG_ Make : 0|8@1+ (1,0) [0|255] "ASCII"  Dummy_Node_Ch2
 SG_ Mdl : 8|8@1+ (1,0) [0|255] "ASCII"  Dummy_Node_Ch2

BO_ 2564487554 ISO15765_Phys_82_F9: 8 REHR_3
 SG_ SepTime m3 : 16|8@1+ (1,0) [0|255] "ms"  OffBoardDiagnosticTool1_Ch2
 SG_ SingFrameDataLen m0 : 0|4@1+ (1,0) [0|7] "Byte"  OffBoardDiagnosticTool1_Ch2
 SG_ N1FrameDataLen m1 : 3|12@0+ (1,0) [0|4095] "Byte"  OffBoardDiagnosticTool1_Ch2
 SG_ BlkSize m3 : 8|8@1+ (1,0) [0|255] ""  OffBoardDiagnosticTool1_Ch2
 SG_ FlowSts m3 : 0|4@1+ (1,0) [0|3] ""  OffBoardDiagnosticTool1_Ch2
 SG_ SN m2 : 0|4@1+ (1,0) [0|15] ""  OffBoardDiagnosticTool1_Ch2
 SG_ ProtocCntrlInfo M : 4|4@1+ (1,0) [0|3] ""  OffBoardDiagnosticTool1_Ch2

BO_ 2564456953 ISO15765_Phys_F9_81: 8 OffBoardDiagnosticTool1_Ch2
 SG_ BlkSize m3 : 8|8@1+ (1,0) [0|255] ""  REHR_2
 SG_ FlowSts m3 : 0|4@1+ (1,0) [0|3] ""  REHR_2
 SG_ N1FrameDataLen m1 : 3|12@0+ (1,0) [0|4095] "Byte"  REHR_2
 SG_ ProtocCntrlInfo M : 4|4@1+ (1,0) [0|3] ""  REHR_2
 SG_ SepTime m3 : 16|8@1+ (1,0) [0|255] "ms"  REHR_2
 SG_ SingFrameDataLen m0 : 0|4@1+ (1,0) [0|7] "Byte"  REHR_2
 SG_ SN m2 : 0|4@1+ (1,0) [0|15] ""  REHR_2

BO_ 2566845952 IC1_00: 8 GWAY_Engine1_Ch2
 SG_ AT_1DPF_IntakPrsUseSPN : 0|8@1+ (0.5,0) [0|125] "kPa" Vector__XXX
 SG_ EngIntakManifld_1Prs : 8|8@1+ (2,0) [0|500] "kPa"  TrailerBrake
 SG_ EngIntakManifld_1Temp : 16|8@1+ (1,-40) [-40|210] "°C" Vector__XXX
 SG_ EngIntakAirPrs : 24|8@1+ (2,0) [0|500] "kPa" Vector__XXX
 SG_ EngAirFilt_1DiffPrs : 32|8@1+ (0.05,0) [0|12.5] "kPa" Vector__XXX
 SG_ EngExhTemp : 40|16@1+ (0.03125,-273) [-273|1734.96875] "°C" Vector__XXX
 SG_ EngCoolntFiltDiffPrs : 56|8@1+ (0.5,0) [0|125] "kPa" Vector__XXX

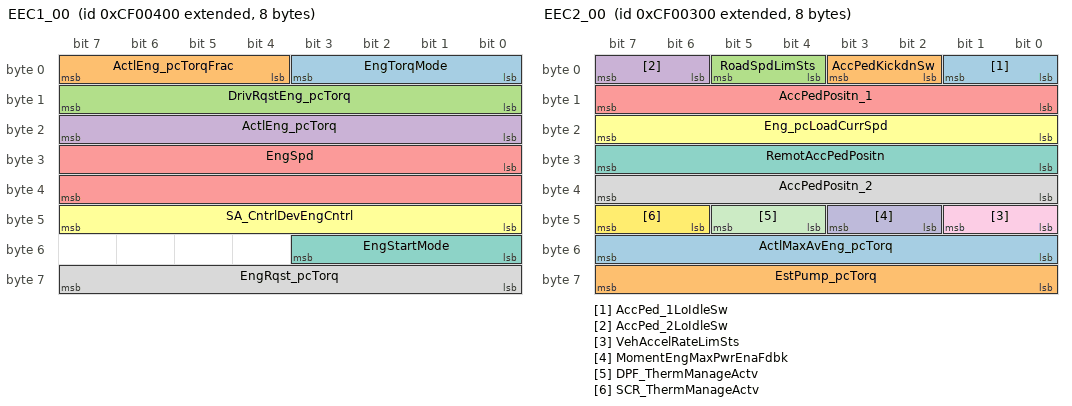
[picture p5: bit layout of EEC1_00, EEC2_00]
BO_ 2364539904 EEC1_00: 8 GWAY_Engine1_Ch2
 SG_ EngTorqMode : 0|4@1+ (1,0) [0|15] "" Vector__XXX
 SG_ ActlEng_pcTorqFrac : 4|4@1+ (0.125,0) [0|0.875] "%" Vector__XXX
 SG_ DrivRqstEng_pcTorq : 8|8@1+ (1,-125) [-125|125] "%" Vector__XXX
 SG_ ActlEng_pcTorq : 16|8@1+ (1,-125) [-125|125] "%" Vector__XXX
 SG_ EngSpd : 24|16@1+ (0.125,0) [0|8031.88] "rpm"  TrailerBrake
 SG_ SA_CntrlDevEngCntrl : 40|8@1+ (1,0) [0|255] "source address" Vector__XXX
 SG_ EngStartMode : 48|4@1+ (1,0) [0|15] "" Vector__XXX
 SG_ EngRqst_pcTorq : 56|8@1+ (1,-125) [-125|125] "%" Vector__XXX

BO_ 2364539648 EEC2_00: 8 GWAY_Engine1_Ch2
 SG_ AccPed_1LoIdleSw : 0|2@1+ (1,0) [0|3] "" Vector__XXX
 SG_ AccPedKickdnSw : 2|2@1+ (1,0) [0|3] "" Vector__XXX
 SG_ RoadSpdLimSts : 4|2@1+ (1,0) [0|3] "" Vector__XXX
 SG_ AccPed_2LoIdleSw : 6|2@1+ (1,0) [0|3] "" Vector__XXX
 SG_ AccPedPositn_1 : 8|8@1+ (0.4,0) [0|100] "%" Vector__XXX
 SG_ Eng_pcLoadCurrSpd : 16|8@1+ (1,0) [0|250] "%"  TrailerBrake
 SG_ RemotAccPedPositn : 24|8@1+ (0.4,0) [0|100] "%" Vector__XXX
 SG_ AccPedPositn_2 : 32|8@1+ (0.4,0) [0|100] "%" Vector__XXX
 SG_ VehAccelRateLimSts : 40|2@1+ (1,0) [0|3] "" Vector__XXX
 SG_ MomentEngMaxPwrEnaFdbk : 42|2@1+ (1,0) [0|3] "" Vector__XXX
 SG_ DPF_ThermManageActv : 44|2@1+ (1,0) [0|3] "" Vector__XXX
 SG_ SCR_ThermManageActv : 46|2@1+ (1,0) [0|3] "" Vector__XXX
 SG_ ActlMaxAvEng_pcTorq : 48|8@1+ (0.4,0) [0|100] "%" Vector__XXX
 SG_ EstPump_pcTorq : 56|8@1+ (1,-125) [-125|125] "%" Vector__XXX

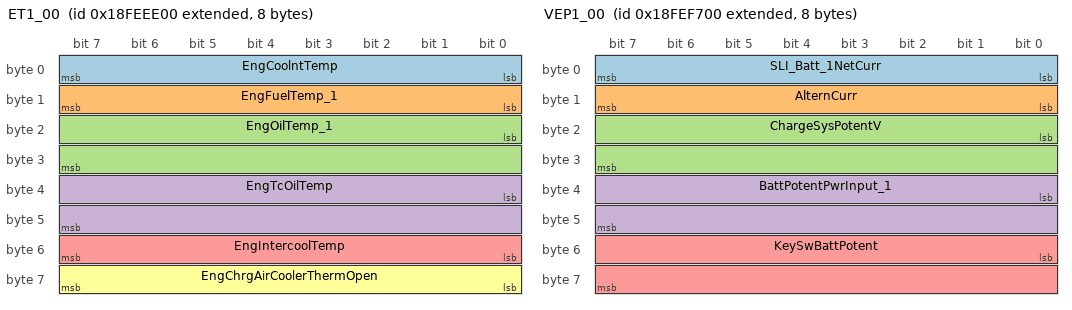
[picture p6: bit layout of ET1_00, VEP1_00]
BO_ 2566843904 ET1_00: 8 GWAY_Engine1_Ch2
 SG_ EngCoolntTemp : 0|8@1+ (1,-40) [-40|210] "°C"  TrailerBrake
 SG_ EngFuelTemp_1 : 8|8@1+ (1,-40) [-40|210] "°C" Vector__XXX
 SG_ EngOilTemp_1 : 16|16@1+ (0.03125,-273) [-273|1734.96875] "°C" Vector__XXX
 SG_ EngTcOilTemp : 32|16@1+ (0.03125,-273) [-273|1734.96875] "°C" Vector__XXX
 SG_ EngIntercoolTemp : 48|8@1+ (1,-40) [-40|210] "°C" Vector__XXX
 SG_ EngChrgAirCoolerThermOpen : 56|8@1+ (0.4,0) [0|100] "%" Vector__XXX

BO_ 2566841600 HOURS_00: 8 GWAY_Engine1_Ch2
 SG_ EngTotHourOp : 0|32@1+ (0.05,0) [0|210554000] "h"  TrailerBrake
 SG_ EngTotRevol : 32|32@1+ (1000,0) [0|4.21108E+22] "r"  TrailerBrake

BO_ 2566846208 VEP1_00: 8 GWAY_Engine1_Ch2
 SG_ SLI_Batt_1NetCurr : 0|8@1+ (1,-125) [-125|125] "A" Vector__XXX
 SG_ AlternCurr : 8|8@1+ (1,0) [0|250] "A" Vector__XXX
 SG_ ChargeSysPotentV : 16|16@1+ (0.05,0) [0|3212.75] "V" Vector__XXX
 SG_ BattPotentPwrInput_1 : 32|16@1+ (0.05,0) [0|3212.75] "V"  TrailerBrake
 SG_ KeySwBattPotent : 48|16@1+ (0.05,0) [0|3212.75] "V" Vector__XXX

BO_TX_BU_ 2565799929 : OffBoardDiagnosticTool1_Ch2,GWAY_OffBoardDiagTool1_VB1_Ch2;
BO_TX_BU_ 2565537785 : OffBoardDiagnosticTool1_Ch2,GWAY_OffBoardDiagTool1_VB1_Ch2;
CM_ BO_ 2564816674 "Stop start broadcast";
CM_ SG_ 2564816674 J1939_Net_4 "Identifies the action to be performed on the J1939 Network #4 communications port.00 Stop Broadcast01 Start Broadcast10 Reserved11 Don’t Care/take no action (leave as is)";
CM_ SG_ 2564816674 SuspendSig "Indicator to all nodes that the current communication port broadcast messages are being suspended due to commands other than J1939 DM13.";
CM_ SG_ 2564816674 J1939_Net_1PriVehNet "Identifies the action to be performed on the SAE J1939 Network #1, Primary vehicle communications port.";
CM_ SG_ 2564816674 J1922 "Identifies the action to be performed on the SAE J1922 communications port.";
CM_ SG_ 2564816674 J1587 "Identifies the action to be performed on the SAE J1587 communications port.";
CM_ SG_ 2564816674 CurrDataLnk "Identifies the action to be performed on the communications port that this parameter was received.";
CM_ SG_ 2564816674 OthManufctSpecPort "Identifies the action to be performed on Other, manufacturer specific port communications port.";
CM_ SG_ 2564816674 J1850 "Identifies the action to be performed on the SAE J1850 communications port.";
CM_ SG_ 2564816674 ISO_9141 "Identifies the action to be performed on the ISO9141 communications port.";
CM_ SG_ 2564816674 J1939_Net_2 "Identifies the action to be performed on the SAE J1939 Network #2.";
CM_ SG_ 2564816674 J1939_Net_3 "Identifies the action to be performed on the SAE J1939 Network #3.";
CM_ SG_ 2564816674 HoldSig "Indicator to all nodes that the communication ports that have been acted upon by the Stop start broadcast...";
CM_ SG_ 2564816674 ProprNet_1 "Identifies the action to be performed on the Proprietary Network #1 communications port.";
CM_ SG_ 2564816674 ProprNet_2 "Identifies the action to be performed on the Proprietary Network #2 communications port.";
CM_ BO_ 2566865698 "The message is used 'On event' to configure the valves. Every byte not used, to be set 0xFF.";
CM_ SG_ 2566865698 EHR_Err_21_22 "Command used to select the desired behavior if the pilot head i.e. how the pilot head should react when errors 21, 22 and 23 are detected and to change the operating mode of the pilot head (CAN, Analogue).";
CM_ SG_ 2566865698 EHR_Err_23 "Command used to select the desired behavior if the pilot head i.e. how the pilot head should react when errors 21, 22 and 23 are detected and to change the operating mode of the pilot head (CAN, Analogue).";
CM_ SG_ 2566865698 EHR_EvNumNew "A status signal indicating the EHR valve number. Used for front & rear EHR's.";
CM_ SG_ 2566865698 EHR_EvNumParamMux_12 "A status signal indicating the EHR valve number. Used for front & rear EHR's.";
CM_ SG_ 2566865698 EHR_EvNumParamMux_15 "A status signal indicating the EHR valve number. Used for front & rear EHR's.";
CM_ SG_ 2566865698 EHR_EvNumParamMux_31 "A status signal indicating the EHR valve number. Used for front & rear EHR's.";
CM_ SG_ 2566865698 EHR_EvNumParamMux_32 "A status signal indicating the EHR valve number. Used for front & rear EHR's.";
CM_ SG_ 2566865698 EHR_EvNumParamMux_50 "A status signal indicating the EHR valve number. Used for front & rear EHR's.";
CM_ SG_ 2566865698 EHR_EvNumParamMux_67 "A status signal indicating the EHR valve number. Used for front & rear EHR's.";
CM_ SG_ 2566865698 EHR_Op "Command used to select the desired behavior if the pilot head i.e. how the pilot head should react when errors 21, 22 and 23 are detected and to change the operating mode of the pilot head (CAN, Analogue).";
CM_ SG_ 2566865698 EHR_PotentmtrRng_10V "Command used to select the desired behavior if the pilot head i.e. how the pilot head should react when errors 21, 22 and 23 are detected and to change the operating mode of the pilot head (CAN, Analogue).";
CM_ SG_ 2566865698 EHR_PotentOp "Command used to select the desired behavior if the pilot head i.e. how the pilot head should react when errors 21, 22 and 23 are detected and to change the operating mode of the pilot head (CAN, Analogue).";
CM_ SG_ 2566865698 EHR_PWM_Op "Command used to select the desired behavior if the pilot head i.e. how the pilot head should react when errors 21, 22 and 23 are detected and to change the operating mode of the pilot head (CAN, Analogue).";
CM_ SG_ 2566865698 EHR_RmpRndng "A status signal indicating the EHR valve number. Used for front & rear EHR's.";
CM_ SG_ 2566870050 MsgCnt_EHR "Initial Value 12. Counts from 0 to 11 and then back to 0. 12, 13 are reserved, 14 error, 15 NA. Tecnord EHR Only";
CM_ SG_ 2566870050 EHR_FailSafe "The aim of this function is if an internal fault is detected by the valve, then the valve will default to either neutral or float depending on failsave mode set in the Ehr control message.";
CM_ SG_ 2566870050 EHR_EvTemp "A measured value to indicate the EHR valve temperature. Used for front & rear EHR's.";
CM_ SG_ 2566870050 EHR_DynRmpTime "By using time ramps, the dynamics of the valve can be reduced in a well-targeted manner. The time ramp is the time required until the full stroke has been completed (from 0 to 100 % or from 100 to 0 % raising or lowering).";
CM_ SG_ 2566870050 EHR_CrvShp "The characteristic-curve shape allows changes from linear to highly progressive. The fine metering properties of the valve can also be altered in this way, if necessary.";
CM_ SG_ 2566870050 EHR_CrvGrad "The characteristic-curve shape allows changes from linear to highly progressive. The fine metering properties of the valve can also be altered in this way, if necessary.";
CM_ SG_ 2566871330 MsgCnt_EHR "Initial Value 12. Counts from 0 to 11 and then back to 0. 12, 13 are reserved, 14 error, 15 NA. Tecnord EHR Only";
CM_ SG_ 2566871330 EHR_FailSafe "The aim of this function is if an internal fault is detected by the valve, then the valve will default to either neutral or float depending on failsave mode set in the Ehr control message.";
CM_ SG_ 2566871330 EHR_EvTemp "A measured value to indicate the EHR valve temperature. Used for front & rear EHR's.";
CM_ SG_ 2566871330 EHR_DynRmpTime "By using time ramps, the dynamics of the valve can be reduced in a well-targeted manner. The time ramp is the time required until the full stroke has been completed (from 0 to 100 % or from 100 to 0 % raising or lowering).";
CM_ SG_ 2566871330 EHR_CrvShp "The characteristic-curve shape allows changes from linear to highly progressive. The fine metering properties of the valve can also be altered in this way, if necessary.";
CM_ SG_ 2566871330 EHR_CrvGrad "The characteristic-curve shape allows changes from linear to highly progressive. The fine metering properties of the valve can also be altered in this way, if necessary.";
CM_ SG_ 2566869794 MsgCnt_EHR "Initial Value 12. Counts from 0 to 11 and then back to 0. 12, 13 are reserved, 14 error, 15 NA. Tecnord EHR Only";
CM_ SG_ 2566869794 EHR_FailSafe "The aim of this function is if an internal fault is detected by the valve, then the valve will default to either neutral or float depending on failsave mode set in the Ehr control message.";
CM_ SG_ 2566869794 EHR_EvTemp "A measured value to indicate the EHR valve temperature. Used for front & rear EHR's.";
CM_ SG_ 2566869794 EHR_DynRmpTime "By using time ramps, the dynamics of the valve can be reduced in a well-targeted manner. The time ramp is the time required until the full stroke has been completed (from 0 to 100 % or from 100 to 0 % raising or lowering).";
CM_ SG_ 2566869794 EHR_CrvShp "The characteristic-curve shape allows changes from linear to highly progressive. The fine metering properties of the valve can also be altered in this way, if necessary.";
CM_ SG_ 2566869794 EHR_CrvGrad "The characteristic-curve shape allows changes from linear to highly progressive. The fine metering properties of the valve can also be altered in this way, if necessary.";
CM_ SG_ 2566869538 MsgCnt_EHR "Initial Value 12. Counts from 0 to 11 and then back to 0. 12, 13 are reserved, 14 error, 15 NA. Tecnord EHR Only";
CM_ SG_ 2566869538 EHR_FailSafe "The aim of this function is if an internal fault is detected by the valve, then the valve will default to either neutral or float depending on failsave mode set in the Ehr control message.";
CM_ SG_ 2566869538 EHR_EvTemp "A measured value to indicate the EHR valve temperature. Used for front & rear EHR's.";
CM_ SG_ 2566869538 EHR_DynRmpTime "By using time ramps, the dynamics of the valve can be reduced in a well-targeted manner. The time ramp is the time required until the full stroke has been completed (from 0 to 100 % or from 100 to 0 % raising or lowering).";
CM_ SG_ 2566869538 EHR_CrvShp "The characteristic-curve shape allows changes from linear to highly progressive. The fine metering properties of the valve can also be altered in this way, if necessary.";
CM_ SG_ 2566869538 EHR_CrvGrad "The characteristic-curve shape allows changes from linear to highly progressive. The fine metering properties of the valve can also be altered in this way, if necessary.";
CM_ SG_ 2566869282 MsgCnt_EHR "Initial Value 12. Counts from 0 to 11 and then back to 0. 12, 13 are reserved, 14 error, 15 NA. Tecnord EHR Only";
CM_ SG_ 2566869282 EHR_FailSafe "The aim of this function is if an internal fault is detected by the valve, then the valve will default to either neutral or float depending on failsave mode set in the Ehr control message.";
CM_ SG_ 2566869282 EHR_EvTemp "A measured value to indicate the EHR valve temperature. Used for front & rear EHR's.";
CM_ SG_ 2566869282 EHR_DynRmpTime "By using time ramps, the dynamics of the valve can be reduced in a well-targeted manner. The time ramp is the time required until the full stroke has been completed (from 0 to 100 % or from 100 to 0 % raising or lowering).";
CM_ SG_ 2566869282 EHR_CrvShp "The characteristic-curve shape allows changes from linear to highly progressive. The fine metering properties of the valve can also be altered in this way, if necessary.";
CM_ SG_ 2566869282 EHR_CrvGrad "The characteristic-curve shape allows changes from linear to highly progressive. The fine metering properties of the valve can also be altered in this way, if necessary.";
CM_ SG_ 2566869026 MsgCnt_EHR "Initial Value 12. Counts from 0 to 11 and then back to 0. 12, 13 are reserved, 14 error, 15 NA. Tecnord EHR Only";
CM_ SG_ 2566869026 EHR_FailSafe "The aim of this function is if an internal fault is detected by the valve, then the valve will default to either neutral or float depending on failsave mode set in the Ehr control message.";
CM_ SG_ 2566869026 EHR_EvTemp "A measured value to indicate the EHR valve temperature. Used for front & rear EHR's.";
CM_ SG_ 2566869026 EHR_DynRmpTime "By using time ramps, the dynamics of the valve can be reduced in a well-targeted manner. The time ramp is the time required until the full stroke has been completed (from 0 to 100 % or from 100 to 0 % raising or lowering).";
CM_ SG_ 2566869026 EHR_CrvShp "The characteristic-curve shape allows changes from linear to highly progressive. The fine metering properties of the valve can also be altered in this way, if necessary.";
CM_ SG_ 2566869026 EHR_CrvGrad "The characteristic-curve shape allows changes from linear to highly progressive. The fine metering properties of the valve can also be altered in this way, if necessary.";
CM_ BO_ 2565537570 "Request";
CM_ SG_ 2565537570 PGN_RQST_22 "ACKN on PGN which is requested by Request message";
CM_ SG_ 2566841634 EngTotHourOp "Accumulated time of operation of engine.";
CM_ SG_ 2566841634 EngTotRevol "Accumulated number of revolutions of engine crankshaft during its operation.";
CM_ BO_ 2564432633 "Reserved for ISO 15765";
CM_ SG_ 2564432633 ProtocCntrlInfo "Part of Network Protocol Control Information (N_PCI) of a ISO 15765 message.";
CM_ BO_ 2564487458 "Reserved for ISO 15765";
CM_ SG_ 2564487458 ProtocCntrlInfo "Part of Network Protocol Control Information (N_PCI) of a ISO 15765 message.";
CM_ BO_ 2565799929 "Address Claimed";
CM_ SG_ 2565799929 Rsrvd_1Bit "Set to 0 for J1939-81";
CM_ BO_ 2565537785 "Request";
CM_ SG_ 2565537785 PGN_RQST_F9 "ACKN on PGN which is requested by Request message";
CM_ BO_ 2566841896 "TimeDate. If node 0x28 not Present the message must be sent by node 0x27. Time information sent in SPNs 959-964 is UTC time (GMT-0) and SPNs 1601 & 1602 are current local offset. Display will apply offsets for fault timestamps received in DM4 messages.";
CM_ SG_ 2566841896 Day "Description_Ref:_A005";
CM_ SG_ 2566841896 Hour "Description_Ref:_A003";
CM_ SG_ 2566841896 LocalHourOfs "Description_Ref:_A008";
CM_ SG_ 2566841896 LocalMinutOfs "Description_Ref:_A007";
CM_ SG_ 2566841896 Minut "Description_Ref:_A002";
CM_ SG_ 2566841896 Month "Description_Ref:_A004";
CM_ SG_ 2566841896 Sec "Description_Ref:_A001";
CM_ SG_ 2566841896 Year "Description_Ref:_A006";
CM_ BO_ 2564459001 "Reserved for ISO 15765";
CM_ SG_ 2564459001 ProtocCntrlInfo "Part of Network Protocol Control Information (N_PCI) of a ISO 15765 message.";
CM_ BO_ 2566843273 "NOTE - The make, model, serial number and unit number fields in this message are optional and separated by an ASCII 
“*”.  It is not necessary to include all fields; however, the delimiter (“*”) is always required.";
CM_ SG_ 2566843273 UnitNumPwrUnit "Owner assigned unit number for the power unit of the vehicle.";
CM_ SG_ 2566843273 SN_2_Byte_15 "Serial number of the component.";
CM_ SG_ 2566843273 SN_2_Byte_14 "Serial number of the component.";
CM_ SG_ 2566843273 SN_2_Byte_13 "Serial number of the component.";
CM_ SG_ 2566843273 SN_2_Byte_12 "Serial number of the component.";
CM_ SG_ 2566843273 SN_2_Byte_11 "Serial number of the component.";
CM_ SG_ 2566843273 SN_2_Byte_10 "Serial number of the component.";
CM_ SG_ 2566843273 SN_2_Byte_09 "Serial number of the component.";
CM_ SG_ 2566843273 SN_2_Byte_08 "Serial number of the component.";
CM_ SG_ 2566843273 SN_2_Byte_07 "Serial number of the component.";
CM_ SG_ 2566843273 SN_2_Byte_06 "Serial number of the component.";
CM_ SG_ 2566843273 SN_2_Byte_05 "Serial number of the component.";
CM_ SG_ 2566843273 SN_2_Byte_04 "Serial number of the component.";
CM_ SG_ 2566843273 SN_2_Byte_03 "Serial number of the component.";
CM_ SG_ 2566843273 SN_2_Byte_02 "Serial number of the component.";
CM_ SG_ 2566843273 SN_2_Byte_01 "Serial number of the component.";
CM_ SG_ 2566843273 SN_2 "Serial number of the component.";
CM_ SG_ 2566843273 Mdl_Byte_08 "Model of the component.";
CM_ SG_ 2566843273 Mdl_Byte_07 "Model of the component.";
CM_ SG_ 2566843273 Mdl_Byte_06 "Model of the component.";
CM_ SG_ 2566843273 Mdl_Byte_05 "Model of the component.";
CM_ SG_ 2566843273 Mdl_Byte_04 "Model of the component.";
CM_ SG_ 2566843273 Mdl_Byte_03 "Model of the component.";
CM_ SG_ 2566843273 Mdl_Byte_02 "Model of the component.";
CM_ SG_ 2566843273 Mdl_Byte_01 "Model of the component.";
CM_ SG_ 2566843273 Make "Owner assigned unit number for the power unit of the vehicle.";
CM_ SG_ 2566843273 Mdl "Model of the component.";
CM_ BO_ 2564487561 "Reserved for ISO 15765";
CM_ SG_ 2564487561 ProtocCntrlInfo "Part of Network Protocol Control Information (N_PCI) of a ISO 15765 message.";
CM_ BO_ 2564457721 "Reserved for ISO 15765";
CM_ SG_ 2564457721 ProtocCntrlInfo "Part of Network Protocol Control Information (N_PCI) of a ISO 15765 message.";
CM_ BO_ 2566843268 "NOTE - The make, model, serial number and unit number fields in this message are optional and separated by an ASCII 
“*”.  It is not necessary to include all fields; however, the delimiter (“*”) is always required.";
CM_ SG_ 2566843268 UnitNumPwrUnit "Owner assigned unit number for the power unit of the vehicle.";
CM_ SG_ 2566843268 SN_2_Byte_15 "Serial number of the component.";
CM_ SG_ 2566843268 SN_2_Byte_14 "Serial number of the component.";
CM_ SG_ 2566843268 SN_2_Byte_13 "Serial number of the component.";
CM_ SG_ 2566843268 SN_2_Byte_12 "Serial number of the component.";
CM_ SG_ 2566843268 SN_2_Byte_11 "Serial number of the component.";
CM_ SG_ 2566843268 SN_2_Byte_10 "Serial number of the component.";
CM_ SG_ 2566843268 SN_2_Byte_09 "Serial number of the component.";
CM_ SG_ 2566843268 SN_2_Byte_08 "Serial number of the component.";
CM_ SG_ 2566843268 SN_2_Byte_07 "Serial number of the component.";
CM_ SG_ 2566843268 SN_2_Byte_06 "Serial number of the component.";
CM_ SG_ 2566843268 SN_2_Byte_05 "Serial number of the component.";
CM_ SG_ 2566843268 SN_2_Byte_04 "Serial number of the component.";
CM_ SG_ 2566843268 SN_2_Byte_03 "Serial number of the component.";
CM_ SG_ 2566843268 SN_2_Byte_02 "Serial number of the component.";
CM_ SG_ 2566843268 SN_2_Byte_01 "Serial number of the component.";
CM_ SG_ 2566843268 SN_2 "Serial number of the component.";
CM_ SG_ 2566843268 Mdl_Byte_08 "Model of the component.";
CM_ SG_ 2566843268 Mdl_Byte_07 "Model of the component.";
CM_ SG_ 2566843268 Mdl_Byte_06 "Model of the component.";
CM_ SG_ 2566843268 Mdl_Byte_05 "Model of the component.";
CM_ SG_ 2566843268 Mdl_Byte_04 "Model of the component.";
CM_ SG_ 2566843268 Mdl_Byte_03 "Model of the component.";
CM_ SG_ 2566843268 Mdl_Byte_02 "Model of the component.";
CM_ SG_ 2566843268 Mdl_Byte_01 "Model of the component.";
CM_ SG_ 2566843268 Make "Owner assigned unit number for the power unit of the vehicle.";
CM_ SG_ 2566843268 Mdl "Model of the component.";
CM_ BO_ 2564487556 "Reserved for ISO 15765";
CM_ SG_ 2564487556 ProtocCntrlInfo "Part of Network Protocol Control Information (N_PCI) of a ISO 15765 message.";
CM_ BO_ 2564457465 "Reserved for ISO 15765";
CM_ SG_ 2564457465 ProtocCntrlInfo "Part of Network Protocol Control Information (N_PCI) of a ISO 15765 message.";
CM_ BO_ 2566843267 "NOTE - The make, model, serial number and unit number fields in this message are optional and separated by an ASCII 
“*”.  It is not necessary to include all fields; however, the delimiter (“*”) is always required.";
CM_ SG_ 2566843267 UnitNumPwrUnit "Owner assigned unit number for the power unit of the vehicle.";
CM_ SG_ 2566843267 SN_2_Byte_15 "Serial number of the component.";
CM_ SG_ 2566843267 SN_2_Byte_14 "Serial number of the component.";
CM_ SG_ 2566843267 SN_2_Byte_13 "Serial number of the component.";
CM_ SG_ 2566843267 SN_2_Byte_12 "Serial number of the component.";
CM_ SG_ 2566843267 SN_2_Byte_11 "Serial number of the component.";
CM_ SG_ 2566843267 SN_2_Byte_10 "Serial number of the component.";
CM_ SG_ 2566843267 SN_2_Byte_09 "Serial number of the component.";
CM_ SG_ 2566843267 SN_2_Byte_08 "Serial number of the component.";
CM_ SG_ 2566843267 SN_2_Byte_07 "Serial number of the component.";
CM_ SG_ 2566843267 SN_2_Byte_06 "Serial number of the component.";
CM_ SG_ 2566843267 SN_2_Byte_05 "Serial number of the component.";
CM_ SG_ 2566843267 SN_2_Byte_04 "Serial number of the component.";
CM_ SG_ 2566843267 SN_2_Byte_03 "Serial number of the component.";
CM_ SG_ 2566843267 SN_2_Byte_02 "Serial number of the component.";
CM_ SG_ 2566843267 SN_2_Byte_01 "Serial number of the component.";
CM_ SG_ 2566843267 SN_2 "Serial number of the component.";
CM_ SG_ 2566843267 Mdl_Byte_08 "Model of the component.";
CM_ SG_ 2566843267 Mdl_Byte_07 "Model of the component.";
CM_ SG_ 2566843267 Mdl_Byte_06 "Model of the component.";
CM_ SG_ 2566843267 Mdl_Byte_05 "Model of the component.";
CM_ SG_ 2566843267 Mdl_Byte_04 "Model of the component.";
CM_ SG_ 2566843267 Mdl_Byte_03 "Model of the component.";
CM_ SG_ 2566843267 Mdl_Byte_02 "Model of the component.";
CM_ SG_ 2566843267 Mdl_Byte_01 "Model of the component.";
CM_ SG_ 2566843267 Make "Owner assigned unit number for the power unit of the vehicle.";
CM_ SG_ 2566843267 Mdl "Model of the component.";
CM_ BO_ 2564487555 "Reserved for ISO 15765";
CM_ SG_ 2564487555 ProtocCntrlInfo "Part of Network Protocol Control Information (N_PCI) of a ISO 15765 message.";
CM_ BO_ 2564457209 "Reserved for ISO 15765";
CM_ SG_ 2564457209 ProtocCntrlInfo "Part of Network Protocol Control Information (N_PCI) of a ISO 15765 message.";
CM_ BO_ 2566843266 "NOTE - The make, model, serial number and unit number fields in this message are optional and separated by an ASCII 
“*”.  It is not necessary to include all fields; however, the delimiter (“*”) is always required.";
CM_ SG_ 2566843266 UnitNumPwrUnit "Owner assigned unit number for the power unit of the vehicle.";
CM_ SG_ 2566843266 SN_2_Byte_15 "Serial number of the component.";
CM_ SG_ 2566843266 SN_2_Byte_14 "Serial number of the component.";
CM_ SG_ 2566843266 SN_2_Byte_13 "Serial number of the component.";
CM_ SG_ 2566843266 SN_2_Byte_12 "Serial number of the component.";
CM_ SG_ 2566843266 SN_2_Byte_11 "Serial number of the component.";
CM_ SG_ 2566843266 SN_2_Byte_10 "Serial number of the component.";
CM_ SG_ 2566843266 SN_2_Byte_09 "Serial number of the component.";
CM_ SG_ 2566843266 SN_2_Byte_08 "Serial number of the component.";
CM_ SG_ 2566843266 SN_2_Byte_07 "Serial number of the component.";
CM_ SG_ 2566843266 SN_2_Byte_06 "Serial number of the component.";
CM_ SG_ 2566843266 SN_2_Byte_05 "Serial number of the component.";
CM_ SG_ 2566843266 SN_2_Byte_04 "Serial number of the component.";
CM_ SG_ 2566843266 SN_2_Byte_03 "Serial number of the component.";
CM_ SG_ 2566843266 SN_2_Byte_02 "Serial number of the component.";
CM_ SG_ 2566843266 SN_2_Byte_01 "Serial number of the component.";
CM_ SG_ 2566843266 SN_2 "Serial number of the component.";
CM_ SG_ 2566843266 Mdl_Byte_08 "Model of the component.";
CM_ SG_ 2566843266 Mdl_Byte_07 "Model of the component.";
CM_ SG_ 2566843266 Mdl_Byte_06 "Model of the component.";
CM_ SG_ 2566843266 Mdl_Byte_05 "Model of the component.";
CM_ SG_ 2566843266 Mdl_Byte_04 "Model of the component.";
CM_ SG_ 2566843266 Mdl_Byte_03 "Model of the component.";
CM_ SG_ 2566843266 Mdl_Byte_02 "Model of the component.";
CM_ SG_ 2566843266 Mdl_Byte_01 "Model of the component.";
CM_ SG_ 2566843266 Make "Owner assigned unit number for the power unit of the vehicle.";
CM_ SG_ 2566843266 Mdl "Model of the component.";
CM_ BO_ 2564487554 "Reserved for ISO 15765";
CM_ SG_ 2564487554 ProtocCntrlInfo "Part of Network Protocol Control Information (N_PCI) of a ISO 15765 message.";
CM_ BO_ 2564456953 "Reserved for ISO 15765";
CM_ SG_ 2564456953 ProtocCntrlInfo "Part of Network Protocol Control Information (N_PCI) of a ISO 15765 message.";
CM_ BO_ 2566845952 "Intake/Exhaust Conditions 1";
CM_ SG_ 2566845952 AT_1DPF_IntakPrsUseSPN "Exhaust back pressure as a result of particle accumulation on filter media placed in the exhaust stream.  See SPN 3609 ...";
CM_ SG_ 2566845952 EngIntakManifld_1Prs "The gage pressure measurement of the air intake manifold. Boost pressure. This value is absolute pressure, not relative.";
CM_ SG_ 2566845952 EngIntakManifld_1Temp "Temperature of pre-combustion air found in intake manifold of engine air supply system.";
CM_ SG_ 2566845952 EngIntakAirPrs "Absolute air pressure at input port to intake manifold or air box.";
CM_ SG_ 2566845952 EngAirFilt_1DiffPrs "Change in engine air system pressure, measured across the filter, due to the filter and any accumulation of solid foreign ...";
CM_ SG_ 2566845952 EngExhTemp "Temperature of combustion byproducts leaving the engine.  See SPNs 2433 and 2434 for engines with more than one ...";
CM_ SG_ 2566845952 EngCoolntFiltDiffPrs "Change in coolant pressure, measured across the filter, due to the filter and any accumulation of solid or semisolid matter ...";
CM_ BO_ 2364539904 "Ag: 20 ms time synchronous; CE: 10 ms time synchronous";
CM_ SG_ 2364539904 EngTorqMode "State signal which indicates which engine or retarder torque mode is currently generating, limiting, or controlling the torque. Other modes are under control of VCM";
CM_ SG_ 2364539904 ActlEng_pcTorqFrac "Additional part of the calculated output torque of the engine, as a percent of the reference engine torque (SPN 544)";
CM_ SG_ 2364539904 DrivRqstEng_pcTorq "The requested torque output of the engine by the driver (accelerator pedal), transmitted as inner torque, as a percent of the reference engine torque (SPN 544) Not evaluated by ECM in two box application.";
CM_ SG_ 2364539904 ActlEng_pcTorq "Actual engine – percent torque (related to the maximum positive torque). The calculated output torque of the engine. The data is transmitted as inner torque, as a percent of reference engine torque (SPN 544) 0xFE in case of error";
CM_ SG_ 2364539904 EngSpd "Actual engine speed which is calculated over a minimum crankshaft angle of 720 degrees divided by the number of cylinders. Current engine speed as sensed at crankshaft 0xFE00 in case of error";
CM_ SG_ 2364539904 SA_CntrlDevEngCntrl "The source address of the SAE J1939 device currently controlling the engine. For 2box application: will be only VCM, if it is requesting a positive torque";
CM_ SG_ 2364539904 EngRqst_pcTorq "The requested torque output of the engine (without considering TSC1 requests). The data is transmitted as inner torque, as a percent of reference engine torque (SPN 544)";
CM_ BO_ 2364539648 "Electronic Engine Controller 2";
CM_ SG_ 2364539648 AccPed_1LoIdleSw "Switch signal which indicates the state of the accelerator pedal 1 low idle switch.  The low idle switch is defined in SAE ...";
CM_ SG_ 2364539648 AccPedKickdnSw "Switch signal which indicates whether the accelerator pedal kickdown switch is opened or closed.  The kickdown switch is ...";
CM_ SG_ 2364539648 RoadSpdLimSts "Status (active or not active) of the system used to limit maximum vehicle velocity.";
CM_ SG_ 2364539648 AccPed_2LoIdleSw "Switch signal which indicates the state of the accelerator pedal 2 low idle switch.  The low idle switch is defined in SAE ...";
CM_ SG_ 2364539648 AccPedPositn_1 "The ratio of current position of the accelerator pedal to its maximum position. Evaluated by ECM only for onebox applications: FEh in case of failure at accelerator pedalNot evaluated by ECM for two-box applications: FFh";
CM_ SG_ 2364539648 Eng_pcLoadCurrSpd "The ratio of current engine inner torque to the maximum inner torque available at the current engine speed, clipped to zero torque during engine braking";
CM_ SG_ 2364539648 RemotAccPedPositn "The ratio of actual position of the remote analog engine speed/torque request input device (such as an accelerator pedal ...";
CM_ SG_ 2364539648 AccPedPositn_2 "The ratio of actual position of the second analog engine speed/torque request input device (such as an accelerator pedal ...";
CM_ SG_ 2364539648 VehAccelRateLimSts "Status (active or not active) of the system used to limit maximum forward  vehicle acceleration.";
CM_ SG_ 2364539648 MomentEngMaxPwrEnaFdbk "Momentarily requesting Engine Maximum Power Enable - feature support feedback ...";
CM_ SG_ 2364539648 DPF_ThermManageActv "Indicates that the exhaust temperatures have been elevated for regeneration of the diesel particulate filter aftertreatment ...";
CM_ SG_ 2364539648 SCR_ThermManageActv "Indicates that the exhaust temperatures have been elevated for regeneration of the SCR aftertreatment system or in ...";
CM_ SG_ 2364539648 ActlMaxAvEng_pcTorq "This is the maximum amount of torque that the engine can immediately deliver as a percentage of the reference engine torque (SPN 544). It take into consideration all engine torque derates and all dynamic limitations (e.g. smoke limitation)";
CM_ SG_ 2364539648 EstPump_pcTorq "The calculated torque that indicates the estimated amount of torque loss due to the engine air handling system. The value ...";
CM_ BO_ 2566843904 "Engine Temperature";
CM_ SG_ 2566843904 EngCoolntTemp "Temperature of liquid found in engine cooling system. FEh in case of defective sensor.";
CM_ SG_ 2566843904 EngFuelTemp_1 "Temperature of fuel (or gas) of the first fuel type. See SPN 3468 for a second temperature measurement of the first fuel type";
CM_ SG_ 2566843904 EngOilTemp_1 "Temperature of the engine lubricant.";
CM_ SG_ 2566843904 EngTcOilTemp "Temperature of the turbocharger lubricant.";
CM_ SG_ 2566843904 EngIntercoolTemp "Temperature of liquid found in the intercooler located after the turbocharger.";
CM_ SG_ 2566843904 EngChrgAirCoolerThermOpen "The current position of the thermostat used to regulate the temperature of the engine intercooler.  A value of 0% ...";
CM_ BO_ 2566841600 "This message is derived from J1939 std message HOURS but is NOT the same: Driveline_hours signal is different from J1939 std. Sent 'On request'.";
CM_ SG_ 2566841600 EngTotHourOp "Accumulated time of operation of engine.";
CM_ SG_ 2566841600 EngTotRevol "Accumulated number of revolutions of engine crankshaft during its operation.";
CM_ BO_ 2566846208 "Vehicle Electrical Power 1";
CM_ SG_ 2566846208 SLI_Batt_1NetCurr "Net flow of electrical current into/out of the first battery or first set of batteries used for starting the engine, for lighting, and for ignition (SLI). See SPN 2579 for alternate range and resolution. See DA 10 2015 for more details";
CM_ SG_ 2566846208 AlternCurr "Measure of electrical current flow from the alternator.  Alternator Current (High Range/Resolution) parameter SPN 1795 ...";
CM_ SG_ 2566846208 ChargeSysPotentV "Electrical potential measured at the charging system output. Not evaluated by ECM (FFh)";
CM_ SG_ 2566846208 BattPotentPwrInput_1 "For SFB: Battery potential measured at the input of the electronic control unit supplied direct from battery. For Engine: This parameter measures the first source of battery potential as measured at the input of the ECM/actuator etc.";
CM_ SG_ 2566846208 KeySwBattPotent "Battery potential measured at the input of the electronic control unit supplied through a keyswitch or similar switching ...";
BA_DEF_ SG_  "GenSigReceiveSetting" STRING ;
BA_DEF_ SG_  "GenSigPreSetting" STRING ;
BA_DEF_ SG_  "GenSigPreIfSetting" STRING ;
BA_DEF_ SG_  "GenSigPostSetting" STRING ;
BA_DEF_ SG_  "GenSigPostIfSetting" STRING ;
BA_DEF_ SG_  "GenSigEnvVarType" ENUM  "int","float","undef";
BA_DEF_ SG_  "GenSigConditionalSend" STRING ;
BA_DEF_ SG_  "GenSigAutoGenSnd" ENUM  "No","Yes";
BA_DEF_ SG_  "GenSigAutoGenDsp" ENUM  "No","Yes";
BA_DEF_ SG_  "GenSigAssignSetting" STRING ;
BA_DEF_ SG_  "GenSigAltSetting" STRING ;
BA_DEF_ SG_  "SPN_Definition" STRING ;
BA_DEF_ SG_  "External_Reference_decod" STRING ;
BA_DEF_ SG_  "UtilizationOnNetwork" ENUM  "Used","NOT USED";
BA_DEF_ SG_  "CI_RepetitionNum" ENUM  "1","2";
BA_DEF_ SG_  "CI_RepetitionType" ENUM  "NA","1","2","3","4";
BA_DEF_ SG_  "CI_RepetitionComplemented" ENUM  "0","1","vector_leerstring";
BA_DEF_ SG_  "DDI" INT 0 65535;
BA_DEF_ SG_  "CI_FullName" STRING ;
BA_DEF_ SG_  "GenSigTimeoutTime" INT 0 3600000;
BA_DEF_ SG_  "CI_ParId" STRING ;
BA_DEF_ SG_  "CI_SLOT_Name" STRING ;
BA_DEF_ SG_  "CI_ParVersion" STRING ;
BA_DEF_ SG_  "GenSigSendType" ENUM  "Cyclic","OnWrite","OnWriteWithRepetition","OnChange","OnChangeWithRepetition","IfActive","IfActiveWithRepetition","NoSigSendType";
BA_DEF_ SG_  "GenSigInactiveValue" INT 0 2147483647;
BA_DEF_ SG_  "GenSigStartValue" INT 0 2147483647;
BA_DEF_ SG_  "GenSigEVName" STRING ;
BA_DEF_ SG_  "SPN" INT 0 524287;
BA_DEF_ SG_  "SigType" ENUM  "Default","Range","RangeSigned","ASCII","Discrete","Control","ReferencePGN","DTC","StringDelimiter","StringLength","StringLengthControl";
BA_DEF_ SG_  "GenSigILSupport" ENUM  "Yes","No";
BA_DEF_ BO_  "ShowSignals" INT -1 0;
BA_DEF_ BO_  "GroupSignals" INT 1 100;
BA_DEF_ BO_  "PGN_Definition" STRING ;
BA_DEF_ BO_  "External_Reference" STRING ;
BA_DEF_ BO_  "SingleFrame" INT 0 1;
BA_DEF_ BO_  "CI_AllowedLostMessages" ENUM  "NA","0","1","2","3","4";
BA_DEF_ BO_  "CI_AliveTimeout" INT 0 3600000;
BA_DEF_ BO_  "TpJ1939VarDlc" ENUM  "No","Yes";
BA_DEF_ BO_  "CI_ShowSignals" INT -1 0;
BA_DEF_ BO_  "CI_PgVersion" STRING ;
BA_DEF_ BO_  "CI_GroupSignals" INT 1 100;
BA_DEF_ BO_  "DiagUUDTResponse" ENUM  "No","Yes";
BA_DEF_ BO_  "DiagState" ENUM  "No","Yes";
BA_DEF_ BO_  "DiagResponse" ENUM  "No","Yes";
BA_DEF_ BO_  "DiagRequest" ENUM  "No","Yes";
BA_DEF_ BO_  "DiagConnection" INT 0 65535;
BA_DEF_ BO_  "GenMsgNrOfRepetition" INT 0 1000000;
BA_DEF_ BO_  "GenMsgILSupport" ENUM  "No","Yes";
BA_DEF_ BO_  "GenMsgFastOnStart" INT 0 100000;
BA_DEF_ BO_  "GenMsgCycleTimeFast" INT 0 3600000;
BA_DEF_ BO_  "GenMsgStartDelayTime" INT 0 100000;
BA_DEF_ BO_  "GenMsgDelayTime" INT 0 3600000;
BA_DEF_ BO_  "VFrameFormat" ENUM  "StandardCAN","ExtendedCAN","reserved","J1939PG";
BA_DEF_ BO_  "GenMsgCycleTime" INT 0 3600000;
BA_DEF_ BO_  "GenMsgRequestable" INT 0 1;
BA_DEF_ BO_  "GenMsgSendType" ENUM  "cyclic","reserved","cyclicIfActive","reserved","reserved","reserved","reserved","reserved","noMsgSendType";
BA_DEF_DEF_  "GenSigReceiveSetting" "";
BA_DEF_DEF_  "GenSigPreSetting" "";
BA_DEF_DEF_  "GenSigPreIfSetting" "";
BA_DEF_DEF_  "GenSigPostSetting" "";
BA_DEF_DEF_  "GenSigPostIfSetting" "";
BA_DEF_DEF_  "GenSigEnvVarType" "undef";
BA_DEF_DEF_  "GenSigConditionalSend" "";
BA_DEF_DEF_  "GenSigAutoGenSnd" "";
BA_DEF_DEF_  "GenSigAutoGenDsp" "";
BA_DEF_DEF_  "GenSigAssignSetting" "";
BA_DEF_DEF_  "GenSigAltSetting" "";
BA_DEF_DEF_  "SPN_Definition" "";
BA_DEF_DEF_  "External_Reference_decod" "";
BA_DEF_DEF_  "UtilizationOnNetwork" "Used";
BA_DEF_DEF_  "CI_RepetitionNum" "1";
BA_DEF_DEF_  "CI_RepetitionType" "NA";
BA_DEF_DEF_  "CI_RepetitionComplemented" "0";
BA_DEF_DEF_  "DDI" 0;
BA_DEF_DEF_  "CI_FullName" "";
BA_DEF_DEF_  "GenSigTimeoutTime" 0;
BA_DEF_DEF_  "CI_ParId" "";
BA_DEF_DEF_  "CI_SLOT_Name" "0";
BA_DEF_DEF_  "CI_ParVersion" "0";
BA_DEF_DEF_  "GenSigSendType" "NoSigSendType";
BA_DEF_DEF_  "GenSigInactiveValue" 0;
BA_DEF_DEF_  "GenSigStartValue" 0;
BA_DEF_DEF_  "GenSigEVName" "Env@Nodename_@Signame";
BA_DEF_DEF_  "SPN" 0;
BA_DEF_DEF_  "SigType" "Default";
BA_DEF_DEF_  "GenSigILSupport" "Yes";
BA_DEF_DEF_  "ShowSignals" -1;
BA_DEF_DEF_  "GroupSignals" 1;
BA_DEF_DEF_  "PGN_Definition" "N/A";
BA_DEF_DEF_  "External_Reference" "";
BA_DEF_DEF_  "SingleFrame" 1;
BA_DEF_DEF_  "CI_AllowedLostMessages" "NA";
BA_DEF_DEF_  "CI_AliveTimeout" 0;
BA_DEF_DEF_  "TpJ1939VarDlc" "No";
BA_DEF_DEF_  "CI_ShowSignals" -1;
BA_DEF_DEF_  "CI_PgVersion" "0";
BA_DEF_DEF_  "CI_GroupSignals" 1;
BA_DEF_DEF_  "DiagUUDTResponse" "No";
BA_DEF_DEF_  "DiagState" "No";
BA_DEF_DEF_  "DiagResponse" "No";
BA_DEF_DEF_  "DiagRequest" "No";
BA_DEF_DEF_  "DiagConnection" 0;
BA_DEF_DEF_  "GenMsgNrOfRepetition" 0;
BA_DEF_DEF_  "GenMsgILSupport" "Yes";
BA_DEF_DEF_  "GenMsgFastOnStart" 0;
BA_DEF_DEF_  "GenMsgCycleTimeFast" 0;
BA_DEF_DEF_  "GenMsgStartDelayTime" 0;
BA_DEF_DEF_  "GenMsgDelayTime" 1;
BA_DEF_DEF_  "VFrameFormat" "J1939PG";
BA_DEF_DEF_  "GenMsgCycleTime" 0;
BA_DEF_DEF_  "GenMsgRequestable" 0;
BA_DEF_DEF_  "GenMsgSendType" "noMsgSendType";
BA_ "TpJ1939VarDlc" BO_ 2564816674 1;
BA_ "GenMsgRequestable" BO_ 2564816674 1;
BA_ "CI_AliveTimeout" BO_ 2566870050 300;
BA_ "GenMsgCycleTime" BO_ 2566870050 100;
BA_ "GenMsgSendType" BO_ 2566870050 0;
BA_ "CI_AliveTimeout" BO_ 2566871330 300;
BA_ "GenMsgCycleTime" BO_ 2566871330 100;
BA_ "GenMsgSendType" BO_ 2566871330 0;
BA_ "CI_AliveTimeout" BO_ 2566869794 300;
BA_ "GenMsgCycleTime" BO_ 2566869794 100;
BA_ "GenMsgSendType" BO_ 2566869794 0;
BA_ "CI_AliveTimeout" BO_ 2566869538 300;
BA_ "GenMsgCycleTime" BO_ 2566869538 100;
BA_ "GenMsgSendType" BO_ 2566869538 0;
BA_ "CI_AliveTimeout" BO_ 2566869282 300;
BA_ "GenMsgCycleTime" BO_ 2566869282 100;
BA_ "GenMsgSendType" BO_ 2566869282 0;
BA_ "CI_AliveTimeout" BO_ 2566869026 300;
BA_ "GenMsgCycleTime" BO_ 2566869026 100;
BA_ "GenMsgSendType" BO_ 2566869026 0;
BA_ "TpJ1939VarDlc" BO_ 2565537570 1;
BA_ "CI_GroupSignals" BO_ 2565537570 2;
BA_ "GenMsgDelayTime" BO_ 2565537570 0;
BA_ "TpJ1939VarDlc" BO_ 2566841634 1;
BA_ "CI_GroupSignals" BO_ 2566841634 2;
BA_ "GenMsgDelayTime" BO_ 2566841634 0;
BA_ "TpJ1939VarDlc" BO_ 2564432633 1;
BA_ "CI_ShowSignals" BO_ 2564432633 0;
BA_ "TpJ1939VarDlc" BO_ 2564487458 1;
BA_ "CI_ShowSignals" BO_ 2564487458 0;
BA_ "TpJ1939VarDlc" BO_ 2565799929 1;
BA_ "CI_GroupSignals" BO_ 2565799929 3;
BA_ "GenMsgRequestable" BO_ 2565799929 1;
BA_ "TpJ1939VarDlc" BO_ 2565537785 1;
BA_ "CI_GroupSignals" BO_ 2565537785 3;
BA_ "GenMsgDelayTime" BO_ 2565537785 0;
BA_ "External_Reference" BO_ 2566841896 "*";
BA_ "CI_AllowedLostMessages" BO_ 2566841896 2;
BA_ "CI_AliveTimeout" BO_ 2566841896 2000;
BA_ "TpJ1939VarDlc" BO_ 2566841896 1;
BA_ "CI_GroupSignals" BO_ 2566841896 2;
BA_ "GenMsgCycleTime" BO_ 2566841896 1000;
BA_ "GenMsgRequestable" BO_ 2566841896 1;
BA_ "GenMsgSendType" BO_ 2566841896 0;
BA_ "TpJ1939VarDlc" BO_ 2564459001 1;
BA_ "CI_ShowSignals" BO_ 2564459001 0;
BA_ "GenMsgDelayTime" BO_ 2564459001 0;
BA_ "TpJ1939VarDlc" BO_ 2566843273 1;
BA_ "CI_ShowSignals" BO_ 2566843273 0;
BA_ "TpJ1939VarDlc" BO_ 2564487561 1;
BA_ "CI_ShowSignals" BO_ 2564487561 0;
BA_ "GenMsgDelayTime" BO_ 2564487561 0;
BA_ "TpJ1939VarDlc" BO_ 2564457721 1;
BA_ "CI_ShowSignals" BO_ 2564457721 0;
BA_ "GenMsgDelayTime" BO_ 2564457721 0;
BA_ "TpJ1939VarDlc" BO_ 2566843268 1;
BA_ "CI_ShowSignals" BO_ 2566843268 0;
BA_ "TpJ1939VarDlc" BO_ 2564487556 1;
BA_ "CI_ShowSignals" BO_ 2564487556 0;
BA_ "GenMsgDelayTime" BO_ 2564487556 0;
BA_ "TpJ1939VarDlc" BO_ 2564457465 1;
BA_ "CI_ShowSignals" BO_ 2564457465 0;
BA_ "GenMsgDelayTime" BO_ 2564457465 0;
BA_ "TpJ1939VarDlc" BO_ 2566843267 1;
BA_ "CI_ShowSignals" BO_ 2566843267 0;
BA_ "TpJ1939VarDlc" BO_ 2564487555 1;
BA_ "CI_ShowSignals" BO_ 2564487555 0;
BA_ "GenMsgDelayTime" BO_ 2564487555 0;
BA_ "TpJ1939VarDlc" BO_ 2564457209 1;
BA_ "CI_ShowSignals" BO_ 2564457209 0;
BA_ "GenMsgDelayTime" BO_ 2564457209 0;
BA_ "TpJ1939VarDlc" BO_ 2566843266 1;
BA_ "CI_ShowSignals" BO_ 2566843266 0;
BA_ "TpJ1939VarDlc" BO_ 2564487554 1;
BA_ "CI_ShowSignals" BO_ 2564487554 0;
BA_ "GenMsgDelayTime" BO_ 2564487554 0;
BA_ "TpJ1939VarDlc" BO_ 2564456953 1;
BA_ "CI_ShowSignals" BO_ 2564456953 0;
BA_ "GenMsgDelayTime" BO_ 2564456953 0;
BA_ "CI_AliveTimeout" BO_ 2566845952 1000;
BA_ "TpJ1939VarDlc" BO_ 2566845952 1;
BA_ "CI_PgVersion" BO_ 2566845952 "-1";
BA_ "GenMsgCycleTime" BO_ 2566845952 500;
BA_ "GenMsgSendType" BO_ 2566845952 0;
BA_ "PGN_Definition" BO_ 2364539904 "J1939 Standard";
BA_ "CI_AliveTimeout" BO_ 2364539904 320;
BA_ "TpJ1939VarDlc" BO_ 2364539904 1;
BA_ "CI_PgVersion" BO_ 2364539904 "-1";
BA_ "GenMsgStartDelayTime" BO_ 2364539904 2;
BA_ "GenMsgCycleTime" BO_ 2364539904 10;
BA_ "GenMsgSendType" BO_ 2364539904 0;
BA_ "CI_AliveTimeout" BO_ 2364539648 100;
BA_ "TpJ1939VarDlc" BO_ 2364539648 1;
BA_ "CI_PgVersion" BO_ 2364539648 "-1";
BA_ "GenMsgCycleTime" BO_ 2364539648 50;
BA_ "GenMsgSendType" BO_ 2364539648 0;
BA_ "PGN_Definition" BO_ 2566843904 "J1939 Standard";
BA_ "CI_AliveTimeout" BO_ 2566843904 3000;
BA_ "TpJ1939VarDlc" BO_ 2566843904 1;
BA_ "CI_PgVersion" BO_ 2566843904 "-1";
BA_ "GenMsgCycleTime" BO_ 2566843904 1000;
BA_ "GenMsgSendType" BO_ 2566843904 0;
BA_ "TpJ1939VarDlc" BO_ 2566841600 1;
BA_ "CI_PgVersion" BO_ 2566841600 "-1";
BA_ "GenMsgRequestable" BO_ 2566841600 1;
BA_ "PGN_Definition" BO_ 2566846208 "J1939 Standard";
BA_ "External_Reference" BO_ 2566846208 "2000";
BA_ "CI_AliveTimeout" BO_ 2566846208 2000;
BA_ "TpJ1939VarDlc" BO_ 2566846208 1;
BA_ "CI_PgVersion" BO_ 2566846208 "-1";
BA_ "GenMsgCycleTime" BO_ 2566846208 1000;
BA_ "GenMsgSendType" BO_ 2566846208 0;
BA_ "CI_FullName" SG_ 2564816674 J1939_Net_4 "J1939 Network #4";
BA_ "CI_ParId" SG_ 2564816674 J1939_Net_4 "ESMD_15175";
BA_ "CI_SLOT_Name" SG_ 2564816674 J1939_Net_4 "SAEbs02";
BA_ "SPN" SG_ 2564816674 J1939_Net_4 1668;
BA_ "CI_FullName" SG_ 2564816674 SuspendDur "Suspend Duration";
BA_ "CI_ParId" SG_ 2564816674 SuspendDur "ESMD_03320";
BA_ "CI_SLOT_Name" SG_ 2564816674 SuspendDur "SAEtm05";
BA_ "SPN" SG_ 2564816674 SuspendDur 2619;
BA_ "CI_FullName" SG_ 2564816674 SuspendSig "Suspend Signal";
BA_ "CI_ParId" SG_ 2564816674 SuspendSig "ESMD_03321";
BA_ "CI_SLOT_Name" SG_ 2564816674 SuspendSig "SAEbs04";
BA_ "SPN" SG_ 2564816674 SuspendSig 2618;
BA_ "CI_FullName" SG_ 2564816674 J1939_Net_1PriVehNet "J1939 Network #1, Primary Vehicle Network";
BA_ "CI_ParId" SG_ 2564816674 J1939_Net_1PriVehNet "ESMD_02145";
BA_ "CI_SLOT_Name" SG_ 2564816674 J1939_Net_1PriVehNet "SAEbs02";
BA_ "SPN" SG_ 2564816674 J1939_Net_1PriVehNet 639;
BA_ "CI_FullName" SG_ 2564816674 J1922 "J1922";
BA_ "CI_ParId" SG_ 2564816674 J1922 "ESMD_03074";
BA_ "CI_SLOT_Name" SG_ 2564816674 J1922 "SAEbs02";
BA_ "SPN" SG_ 2564816674 J1922 622;
BA_ "CI_FullName" SG_ 2564816674 J1587 "J1587";
BA_ "CI_ParId" SG_ 2564816674 J1587 "ESMD_03072";
BA_ "CI_SLOT_Name" SG_ 2564816674 J1587 "SAEbs02";
BA_ "SPN" SG_ 2564816674 J1587 608;
BA_ "CI_FullName" SG_ 2564816674 CurrDataLnk "Current Data Link";
BA_ "CI_ParId" SG_ 2564816674 CurrDataLnk "ESMD_01010";
BA_ "CI_SLOT_Name" SG_ 2564816674 CurrDataLnk "SAEbs02";
BA_ "SPN" SG_ 2564816674 CurrDataLnk 1230;
BA_ "CI_FullName" SG_ 2564816674 OthManufctSpecPort "Other, Manufacturer Specified Port";
BA_ "CI_ParId" SG_ 2564816674 OthManufctSpecPort "ESMD_02675";
BA_ "CI_SLOT_Name" SG_ 2564816674 OthManufctSpecPort "SAEbs02";
BA_ "SPN" SG_ 2564816674 OthManufctSpecPort 1234;
BA_ "CI_FullName" SG_ 2564816674 J1850 "J1850";
BA_ "CI_ParId" SG_ 2564816674 J1850 "ESMD_03073";
BA_ "CI_SLOT_Name" SG_ 2564816674 J1850 "SAEbs02";
BA_ "SPN" SG_ 2564816674 J1850 1233;
BA_ "CI_FullName" SG_ 2564816674 ISO_9141 "ISO 9141";
BA_ "CI_ParId" SG_ 2564816674 ISO_9141 "ESMD_02144";
BA_ "CI_SLOT_Name" SG_ 2564816674 ISO_9141 "SAEbs02";
BA_ "SPN" SG_ 2564816674 ISO_9141 1232;
BA_ "CI_FullName" SG_ 2564816674 J1939_Net_2 "J1939 Network #2";
BA_ "CI_ParId" SG_ 2564816674 J1939_Net_2 "ESMD_02146";
BA_ "CI_SLOT_Name" SG_ 2564816674 J1939_Net_2 "SAEbs02";
BA_ "SPN" SG_ 2564816674 J1939_Net_2 1231;
BA_ "CI_FullName" SG_ 2564816674 J1939_Net_3 "J1939 Network #3";
BA_ "CI_ParId" SG_ 2564816674 J1939_Net_3 "ESMD_02147";
BA_ "CI_SLOT_Name" SG_ 2564816674 J1939_Net_3 "SAEbs02";
BA_ "SPN" SG_ 2564816674 J1939_Net_3 1235;
BA_ "CI_FullName" SG_ 2564816674 HoldSig "Hold Signal";
BA_ "CI_ParId" SG_ 2564816674 HoldSig "ESMD_02086";
BA_ "CI_SLOT_Name" SG_ 2564816674 HoldSig "SAEbs04";
BA_ "SPN" SG_ 2564816674 HoldSig 1236;
BA_ "CI_FullName" SG_ 2564816674 ProprNet_1 "Proprietary Network #1";
BA_ "CI_ParId" SG_ 2564816674 ProprNet_1 "ESMD_02902";
BA_ "CI_SLOT_Name" SG_ 2564816674 ProprNet_1 "SAEbs02";
BA_ "SPN" SG_ 2564816674 ProprNet_1 625;
BA_ "CI_FullName" SG_ 2564816674 ProprNet_2 "Proprietary Network #2";
BA_ "CI_ParId" SG_ 2564816674 ProprNet_2 "ESMD_02903";
BA_ "CI_SLOT_Name" SG_ 2564816674 ProprNet_2 "SAEbs02";
BA_ "SPN" SG_ 2564816674 ProprNet_2 5588;
BA_ "CI_FullName" SG_ 2566865698 EHR_Err_21_22 "EHR Fault 21 and 22";
BA_ "CI_ParId" SG_ 2566865698 EHR_Err_21_22 "ESMD_20894";
BA_ "CI_FullName" SG_ 2566865698 EHR_Err_23 "EHR Fault 23";
BA_ "CI_ParId" SG_ 2566865698 EHR_Err_23 "ESMD_20895";
BA_ "CI_FullName" SG_ 2566865698 EHR_EvNumNew "EHR Valve Number New";
BA_ "CI_ParId" SG_ 2566865698 EHR_EvNumNew "ESMD_20934";
BA_ "SigType" SG_ 2566865698 EHR_EvNumNew 1.7E-308;
BA_ "CI_FullName" SG_ 2566865698 EHR_EvNumParamMux_12 "EHR Valve Number Parameter Multiplex 12";
BA_ "CI_ParId" SG_ 2566865698 EHR_EvNumParamMux_12 "ESMD_20916";
BA_ "CI_FullName" SG_ 2566865698 EHR_EvNumParamMux_15 "EHR Valve Number Parameter Multiplex 15";
BA_ "CI_ParId" SG_ 2566865698 EHR_EvNumParamMux_15 "ESMD_20917";
BA_ "CI_FullName" SG_ 2566865698 EHR_EvNumParamMux_31 "EHR Valve Number Parameter Multiplex 31";
BA_ "CI_ParId" SG_ 2566865698 EHR_EvNumParamMux_31 "ESMD_20918";
BA_ "CI_FullName" SG_ 2566865698 EHR_EvNumParamMux_32 "EHR Valve Number Parameter Multiplex 32";
BA_ "CI_ParId" SG_ 2566865698 EHR_EvNumParamMux_32 "ESMD_20919";
BA_ "CI_FullName" SG_ 2566865698 EHR_EvNumParamMux_50 "EHR Valve Number Parameter Multiplex 50";
BA_ "CI_ParId" SG_ 2566865698 EHR_EvNumParamMux_50 "ESMD_20920";
BA_ "CI_FullName" SG_ 2566865698 EHR_EvNumParamMux_67 "EHR Valve Number Parameter Multiplex 67";
BA_ "CI_ParId" SG_ 2566865698 EHR_EvNumParamMux_67 "ESMD_20921";
BA_ "CI_FullName" SG_ 2566865698 EHR_Op "EHR CAN Operation";
BA_ "CI_ParId" SG_ 2566865698 EHR_Op "ESMD_20885";
BA_ "CI_FullName" SG_ 2566865698 EHR_PotentmtrRng_10V "EHR Potentiometer Range 10 Volts";
BA_ "CI_ParId" SG_ 2566865698 EHR_PotentmtrRng_10V "ESMD_20906";
BA_ "CI_FullName" SG_ 2566865698 EHR_PotentOp "EHR Potential Operation";
BA_ "CI_ParId" SG_ 2566865698 EHR_PotentOp "ESMD_20905";
BA_ "CI_FullName" SG_ 2566865698 EHR_PWM_Op "EHR PWM Operation";
BA_ "CI_ParId" SG_ 2566865698 EHR_PWM_Op "ESMD_20907";
BA_ "CI_FullName" SG_ 2566865698 EHR_RmpRndng "EHR Ramp Rounding";
BA_ "CI_ParId" SG_ 2566865698 EHR_RmpRndng "ESMD_20908";
BA_ "CI_FullName" SG_ 2566865698 EHR_ParamByte_1 "EHR Parameter Byte 1";
BA_ "CI_ParId" SG_ 2566865698 EHR_ParamByte_1 "ESMD_20901";
BA_ "CI_FullName" SG_ 2566865698 EHR_ParamByte_2 "EHR Parameter Byte 2";
BA_ "CI_ParId" SG_ 2566865698 EHR_ParamByte_2 "ESMD_20902";
BA_ "CI_RepetitionNum" SG_ 2566870050 MsgCnt_EHR 1;
BA_ "CI_RepetitionType" SG_ 2566870050 MsgCnt_EHR 3;
BA_ "CI_FullName" SG_ 2566870050 MsgCnt_EHR "Message Counter 2";
BA_ "CI_ParId" SG_ 2566870050 MsgCnt_EHR "ESMD_27907";
BA_ "CI_SLOT_Name" SG_ 2566870050 MsgCnt_EHR "SAEct08";
BA_ "GenSigStartValue" SG_ 2566870050 MsgCnt_EHR 12;
BA_ "SPN" SG_ 2566870050 MsgCnt_EHR 7041;
BA_ "CI_FullName" SG_ 2566870050 EHR_EvNum "EHR Valve Number";
BA_ "CI_ParId" SG_ 2566870050 EHR_EvNum "ESMD_20914";
BA_ "CI_FullName" SG_ 2566870050 EHR_FailSafe "EHR Fail safe";
BA_ "CI_ParId" SG_ 2566870050 EHR_FailSafe "ESMD_20892";
BA_ "CI_FullName" SG_ 2566870050 EHR_CntrlSts "EHR Control State";
BA_ "CI_ParId" SG_ 2566870050 EHR_CntrlSts "ESMD_20888";
BA_ "CI_FullName" SG_ 2566870050 EHR_EvTemp "EHR Valve Temperature";
BA_ "CI_ParId" SG_ 2566870050 EHR_EvTemp "ESMD_20923";
BA_ "GenSigStartValue" SG_ 2566870050 EHR_EvTemp 40;
BA_ "CI_FullName" SG_ 2566870050 EHR_EvFlow "EHR Valve Flow";
BA_ "CI_ParId" SG_ 2566870050 EHR_EvFlow "ESMD_20911";
BA_ "CI_FullName" SG_ 2566870050 EHR_Op_2 "EHR Operation 2";
BA_ "CI_ParId" SG_ 2566870050 EHR_Op_2 "ESMD_20900";
BA_ "CI_FullName" SG_ 2566870050 EHR_Op_1 "EHR Operation 1";
BA_ "CI_ParId" SG_ 2566870050 EHR_Op_1 "ESMD_20899";
BA_ "CI_FullName" SG_ 2566870050 EHR_DynRmpTime "EHR Dynamic Ramp Time";
BA_ "CI_ParId" SG_ 2566870050 EHR_DynRmpTime "ESMD_20891";
BA_ "CI_FullName" SG_ 2566870050 EHR_CrvShp "EHR Curve Shape";
BA_ "CI_ParId" SG_ 2566870050 EHR_CrvShp "ESMD_20890";
BA_ "CI_FullName" SG_ 2566870050 EHR_CrvGrad "EHR Curve Gradient";
BA_ "CI_ParId" SG_ 2566870050 EHR_CrvGrad "ESMD_20889";
BA_ "CI_FullName" SG_ 2566870050 EHR_Init "EHR Initial";
BA_ "CI_ParId" SG_ 2566870050 EHR_Init "ESMD_20897";
BA_ "CI_RepetitionNum" SG_ 2566871330 MsgCnt_EHR 1;
BA_ "CI_RepetitionType" SG_ 2566871330 MsgCnt_EHR 3;
BA_ "CI_FullName" SG_ 2566871330 MsgCnt_EHR "Message Counter 2";
BA_ "CI_ParId" SG_ 2566871330 MsgCnt_EHR "ESMD_27907";
BA_ "CI_SLOT_Name" SG_ 2566871330 MsgCnt_EHR "SAEct08";
BA_ "GenSigStartValue" SG_ 2566871330 MsgCnt_EHR 12;
BA_ "SPN" SG_ 2566871330 MsgCnt_EHR 7041;
BA_ "CI_FullName" SG_ 2566871330 EHR_EvNum "EHR Valve Number";
BA_ "CI_ParId" SG_ 2566871330 EHR_EvNum "ESMD_20914";
BA_ "CI_FullName" SG_ 2566871330 EHR_FailSafe "EHR Fail safe";
BA_ "CI_ParId" SG_ 2566871330 EHR_FailSafe "ESMD_20892";
BA_ "CI_FullName" SG_ 2566871330 EHR_CntrlSts "EHR Control State";
BA_ "CI_ParId" SG_ 2566871330 EHR_CntrlSts "ESMD_20888";
BA_ "CI_FullName" SG_ 2566871330 EHR_EvTemp "EHR Valve Temperature";
BA_ "CI_ParId" SG_ 2566871330 EHR_EvTemp "ESMD_20923";
BA_ "GenSigStartValue" SG_ 2566871330 EHR_EvTemp 40;
BA_ "CI_FullName" SG_ 2566871330 EHR_EvFlow "EHR Valve Flow";
BA_ "CI_ParId" SG_ 2566871330 EHR_EvFlow "ESMD_20911";
BA_ "CI_FullName" SG_ 2566871330 EHR_Op_2 "EHR Operation 2";
BA_ "CI_ParId" SG_ 2566871330 EHR_Op_2 "ESMD_20900";
BA_ "CI_FullName" SG_ 2566871330 EHR_Op_1 "EHR Operation 1";
BA_ "CI_ParId" SG_ 2566871330 EHR_Op_1 "ESMD_20899";
BA_ "CI_FullName" SG_ 2566871330 EHR_DynRmpTime "EHR Dynamic Ramp Time";
BA_ "CI_ParId" SG_ 2566871330 EHR_DynRmpTime "ESMD_20891";
BA_ "CI_FullName" SG_ 2566871330 EHR_CrvShp "EHR Curve Shape";
BA_ "CI_ParId" SG_ 2566871330 EHR_CrvShp "ESMD_20890";
BA_ "CI_FullName" SG_ 2566871330 EHR_CrvGrad "EHR Curve Gradient";
BA_ "CI_ParId" SG_ 2566871330 EHR_CrvGrad "ESMD_20889";
BA_ "CI_FullName" SG_ 2566871330 EHR_Init "EHR Initial";
BA_ "CI_ParId" SG_ 2566871330 EHR_Init "ESMD_20897";
BA_ "CI_RepetitionNum" SG_ 2566869794 MsgCnt_EHR 1;
BA_ "CI_RepetitionType" SG_ 2566869794 MsgCnt_EHR 3;
BA_ "CI_FullName" SG_ 2566869794 MsgCnt_EHR "Message Counter 2";
BA_ "CI_ParId" SG_ 2566869794 MsgCnt_EHR "ESMD_27907";
BA_ "CI_SLOT_Name" SG_ 2566869794 MsgCnt_EHR "SAEct08";
BA_ "GenSigStartValue" SG_ 2566869794 MsgCnt_EHR 12;
BA_ "SPN" SG_ 2566869794 MsgCnt_EHR 7041;
BA_ "CI_FullName" SG_ 2566869794 EHR_EvNum "EHR Valve Number";
BA_ "CI_ParId" SG_ 2566869794 EHR_EvNum "ESMD_20914";
BA_ "CI_FullName" SG_ 2566869794 EHR_FailSafe "EHR Fail safe";
BA_ "CI_ParId" SG_ 2566869794 EHR_FailSafe "ESMD_20892";
BA_ "CI_FullName" SG_ 2566869794 EHR_CntrlSts "EHR Control State";
BA_ "CI_ParId" SG_ 2566869794 EHR_CntrlSts "ESMD_20888";
BA_ "CI_FullName" SG_ 2566869794 EHR_EvTemp "EHR Valve Temperature";
BA_ "CI_ParId" SG_ 2566869794 EHR_EvTemp "ESMD_20923";
BA_ "GenSigStartValue" SG_ 2566869794 EHR_EvTemp 40;
BA_ "CI_FullName" SG_ 2566869794 EHR_EvFlow "EHR Valve Flow";
BA_ "CI_ParId" SG_ 2566869794 EHR_EvFlow "ESMD_20911";
BA_ "CI_FullName" SG_ 2566869794 EHR_Op_2 "EHR Operation 2";
BA_ "CI_ParId" SG_ 2566869794 EHR_Op_2 "ESMD_20900";
BA_ "CI_FullName" SG_ 2566869794 EHR_Op_1 "EHR Operation 1";
BA_ "CI_ParId" SG_ 2566869794 EHR_Op_1 "ESMD_20899";
BA_ "CI_FullName" SG_ 2566869794 EHR_DynRmpTime "EHR Dynamic Ramp Time";
BA_ "CI_ParId" SG_ 2566869794 EHR_DynRmpTime "ESMD_20891";
BA_ "CI_FullName" SG_ 2566869794 EHR_CrvShp "EHR Curve Shape";
BA_ "CI_ParId" SG_ 2566869794 EHR_CrvShp "ESMD_20890";
BA_ "CI_FullName" SG_ 2566869794 EHR_CrvGrad "EHR Curve Gradient";
BA_ "CI_ParId" SG_ 2566869794 EHR_CrvGrad "ESMD_20889";
BA_ "CI_FullName" SG_ 2566869794 EHR_Init "EHR Initial";
BA_ "CI_ParId" SG_ 2566869794 EHR_Init "ESMD_20897";
BA_ "CI_RepetitionNum" SG_ 2566869538 MsgCnt_EHR 1;
BA_ "CI_RepetitionType" SG_ 2566869538 MsgCnt_EHR 3;
BA_ "CI_FullName" SG_ 2566869538 MsgCnt_EHR "Message Counter 2";
BA_ "CI_ParId" SG_ 2566869538 MsgCnt_EHR "ESMD_27907";
BA_ "CI_SLOT_Name" SG_ 2566869538 MsgCnt_EHR "SAEct08";
BA_ "GenSigStartValue" SG_ 2566869538 MsgCnt_EHR 12;
BA_ "SPN" SG_ 2566869538 MsgCnt_EHR 7041;
BA_ "CI_FullName" SG_ 2566869538 EHR_EvNum "EHR Valve Number";
BA_ "CI_ParId" SG_ 2566869538 EHR_EvNum "ESMD_20914";
BA_ "CI_FullName" SG_ 2566869538 EHR_FailSafe "EHR Fail safe";
BA_ "CI_ParId" SG_ 2566869538 EHR_FailSafe "ESMD_20892";
BA_ "CI_FullName" SG_ 2566869538 EHR_CntrlSts "EHR Control State";
BA_ "CI_ParId" SG_ 2566869538 EHR_CntrlSts "ESMD_20888";
BA_ "CI_FullName" SG_ 2566869538 EHR_EvTemp "EHR Valve Temperature";
BA_ "CI_ParId" SG_ 2566869538 EHR_EvTemp "ESMD_20923";
BA_ "GenSigStartValue" SG_ 2566869538 EHR_EvTemp 40;
BA_ "CI_FullName" SG_ 2566869538 EHR_EvFlow "EHR Valve Flow";
BA_ "CI_ParId" SG_ 2566869538 EHR_EvFlow "ESMD_20911";
BA_ "CI_FullName" SG_ 2566869538 EHR_Op_2 "EHR Operation 2";
BA_ "CI_ParId" SG_ 2566869538 EHR_Op_2 "ESMD_20900";
BA_ "CI_FullName" SG_ 2566869538 EHR_Op_1 "EHR Operation 1";
BA_ "CI_ParId" SG_ 2566869538 EHR_Op_1 "ESMD_20899";
BA_ "CI_FullName" SG_ 2566869538 EHR_DynRmpTime "EHR Dynamic Ramp Time";
BA_ "CI_ParId" SG_ 2566869538 EHR_DynRmpTime "ESMD_20891";
BA_ "CI_FullName" SG_ 2566869538 EHR_CrvShp "EHR Curve Shape";
BA_ "CI_ParId" SG_ 2566869538 EHR_CrvShp "ESMD_20890";
BA_ "CI_FullName" SG_ 2566869538 EHR_CrvGrad "EHR Curve Gradient";
BA_ "CI_ParId" SG_ 2566869538 EHR_CrvGrad "ESMD_20889";
BA_ "CI_FullName" SG_ 2566869538 EHR_Init "EHR Initial";
BA_ "CI_ParId" SG_ 2566869538 EHR_Init "ESMD_20897";
BA_ "CI_RepetitionNum" SG_ 2566869282 MsgCnt_EHR 1;
BA_ "CI_RepetitionType" SG_ 2566869282 MsgCnt_EHR 3;
BA_ "CI_FullName" SG_ 2566869282 MsgCnt_EHR "Message Counter 2";
BA_ "CI_ParId" SG_ 2566869282 MsgCnt_EHR "ESMD_27907";
BA_ "CI_SLOT_Name" SG_ 2566869282 MsgCnt_EHR "SAEct08";
BA_ "GenSigStartValue" SG_ 2566869282 MsgCnt_EHR 12;
BA_ "SPN" SG_ 2566869282 MsgCnt_EHR 7041;
BA_ "CI_FullName" SG_ 2566869282 EHR_EvNum "EHR Valve Number";
BA_ "CI_ParId" SG_ 2566869282 EHR_EvNum "ESMD_20914";
BA_ "CI_FullName" SG_ 2566869282 EHR_FailSafe "EHR Fail safe";
BA_ "CI_ParId" SG_ 2566869282 EHR_FailSafe "ESMD_20892";
BA_ "CI_FullName" SG_ 2566869282 EHR_CntrlSts "EHR Control State";
BA_ "CI_ParId" SG_ 2566869282 EHR_CntrlSts "ESMD_20888";
BA_ "CI_FullName" SG_ 2566869282 EHR_EvTemp "EHR Valve Temperature";
BA_ "CI_ParId" SG_ 2566869282 EHR_EvTemp "ESMD_20923";
BA_ "GenSigStartValue" SG_ 2566869282 EHR_EvTemp 40;
BA_ "CI_FullName" SG_ 2566869282 EHR_EvFlow "EHR Valve Flow";
BA_ "CI_ParId" SG_ 2566869282 EHR_EvFlow "ESMD_20911";
BA_ "CI_FullName" SG_ 2566869282 EHR_Op_2 "EHR Operation 2";
BA_ "CI_ParId" SG_ 2566869282 EHR_Op_2 "ESMD_20900";
BA_ "CI_FullName" SG_ 2566869282 EHR_Op_1 "EHR Operation 1";
BA_ "CI_ParId" SG_ 2566869282 EHR_Op_1 "ESMD_20899";
BA_ "CI_FullName" SG_ 2566869282 EHR_DynRmpTime "EHR Dynamic Ramp Time";
BA_ "CI_ParId" SG_ 2566869282 EHR_DynRmpTime "ESMD_20891";
BA_ "CI_FullName" SG_ 2566869282 EHR_CrvShp "EHR Curve Shape";
BA_ "CI_ParId" SG_ 2566869282 EHR_CrvShp "ESMD_20890";
BA_ "CI_FullName" SG_ 2566869282 EHR_CrvGrad "EHR Curve Gradient";
BA_ "CI_ParId" SG_ 2566869282 EHR_CrvGrad "ESMD_20889";
BA_ "CI_FullName" SG_ 2566869282 EHR_Init "EHR Initial";
BA_ "CI_ParId" SG_ 2566869282 EHR_Init "ESMD_20897";
BA_ "CI_RepetitionNum" SG_ 2566869026 MsgCnt_EHR 1;
BA_ "CI_RepetitionType" SG_ 2566869026 MsgCnt_EHR 3;
BA_ "CI_FullName" SG_ 2566869026 MsgCnt_EHR "Message Counter 2";
BA_ "CI_ParId" SG_ 2566869026 MsgCnt_EHR "ESMD_27907";
BA_ "CI_SLOT_Name" SG_ 2566869026 MsgCnt_EHR "SAEct08";
BA_ "GenSigStartValue" SG_ 2566869026 MsgCnt_EHR 12;
BA_ "SPN" SG_ 2566869026 MsgCnt_EHR 7041;
BA_ "CI_FullName" SG_ 2566869026 EHR_EvNum "EHR Valve Number";
BA_ "CI_ParId" SG_ 2566869026 EHR_EvNum "ESMD_20914";
BA_ "CI_FullName" SG_ 2566869026 EHR_FailSafe "EHR Fail safe";
BA_ "CI_ParId" SG_ 2566869026 EHR_FailSafe "ESMD_20892";
BA_ "CI_FullName" SG_ 2566869026 EHR_CntrlSts "EHR Control State";
BA_ "CI_ParId" SG_ 2566869026 EHR_CntrlSts "ESMD_20888";
BA_ "CI_FullName" SG_ 2566869026 EHR_EvTemp "EHR Valve Temperature";
BA_ "CI_ParId" SG_ 2566869026 EHR_EvTemp "ESMD_20923";
BA_ "GenSigStartValue" SG_ 2566869026 EHR_EvTemp 40;
BA_ "CI_FullName" SG_ 2566869026 EHR_EvFlow "EHR Valve Flow";
BA_ "CI_ParId" SG_ 2566869026 EHR_EvFlow "ESMD_20911";
BA_ "CI_FullName" SG_ 2566869026 EHR_Op_2 "EHR Operation 2";
BA_ "CI_ParId" SG_ 2566869026 EHR_Op_2 "ESMD_20900";
BA_ "CI_FullName" SG_ 2566869026 EHR_Op_1 "EHR Operation 1";
BA_ "CI_ParId" SG_ 2566869026 EHR_Op_1 "ESMD_20899";
BA_ "CI_FullName" SG_ 2566869026 EHR_DynRmpTime "EHR Dynamic Ramp Time";
BA_ "CI_ParId" SG_ 2566869026 EHR_DynRmpTime "ESMD_20891";
BA_ "CI_FullName" SG_ 2566869026 EHR_CrvShp "EHR Curve Shape";
BA_ "CI_ParId" SG_ 2566869026 EHR_CrvShp "ESMD_20890";
BA_ "CI_FullName" SG_ 2566869026 EHR_CrvGrad "EHR Curve Gradient";
BA_ "CI_ParId" SG_ 2566869026 EHR_CrvGrad "ESMD_20889";
BA_ "CI_FullName" SG_ 2566869026 EHR_Init "EHR Initial";
BA_ "CI_ParId" SG_ 2566869026 EHR_Init "ESMD_20897";
BA_ "CI_ParId" SG_ 2565537570 PGN_RQST_22 "ESMD_20258";
BA_ "SPN" SG_ 2565537570 PGN_RQST_22 2540;
BA_ "SigType" SG_ 2565537570 PGN_RQST_22 6;
BA_ "GenSigAutoGenSnd" SG_ 2566841634 EngTotHourOp 0;
BA_ "GenSigAutoGenDsp" SG_ 2566841634 EngTotHourOp 0;
BA_ "CI_RepetitionComplemented" SG_ 2566841634 EngTotHourOp 2;
BA_ "CI_FullName" SG_ 2566841634 EngTotHourOp "Engine Total Hours of Operation";
BA_ "CI_ParId" SG_ 2566841634 EngTotHourOp "ESMD_01840";
BA_ "CI_SLOT_Name" SG_ 2566841634 EngTotHourOp "SAEtm09";
BA_ "SPN" SG_ 2566841634 EngTotHourOp 247;
BA_ "GenSigAutoGenSnd" SG_ 2566841634 EngTotRevol 0;
BA_ "GenSigAutoGenDsp" SG_ 2566841634 EngTotRevol 0;
BA_ "CI_RepetitionComplemented" SG_ 2566841634 EngTotRevol 2;
BA_ "CI_FullName" SG_ 2566841634 EngTotRevol "Engine Total Revolutions";
BA_ "CI_ParId" SG_ 2566841634 EngTotRevol "ESMD_01843";
BA_ "CI_SLOT_Name" SG_ 2566841634 EngTotRevol "SAErv01";
BA_ "SPN" SG_ 2566841634 EngTotRevol 249;
BA_ "SigType" SG_ 2566841634 EngTotRevol 1;
BA_ "GenSigAutoGenSnd" SG_ 2564432633 BlkSize 0;
BA_ "GenSigAutoGenDsp" SG_ 2564432633 BlkSize 0;
BA_ "CI_RepetitionComplemented" SG_ 2564432633 BlkSize 2;
BA_ "CI_FullName" SG_ 2564432633 BlkSize "Block Size";
BA_ "CI_ParId" SG_ 2564432633 BlkSize "ESMD_00809";
BA_ "GenSigAutoGenSnd" SG_ 2564432633 FlowSts 0;
BA_ "GenSigAutoGenDsp" SG_ 2564432633 FlowSts 0;
BA_ "CI_RepetitionComplemented" SG_ 2564432633 FlowSts 2;
BA_ "CI_FullName" SG_ 2564432633 FlowSts "Flow Status";
BA_ "CI_ParId" SG_ 2564432633 FlowSts "ESMD_01968";
BA_ "GenSigAutoGenSnd" SG_ 2564432633 N1FrameDataLen 0;
BA_ "GenSigAutoGenDsp" SG_ 2564432633 N1FrameDataLen 0;
BA_ "CI_RepetitionComplemented" SG_ 2564432633 N1FrameDataLen 2;
BA_ "CI_FullName" SG_ 2564432633 N1FrameDataLen "First Frame Data Length";
BA_ "CI_ParId" SG_ 2564432633 N1FrameDataLen "ESMD_01962";
BA_ "GenSigAutoGenSnd" SG_ 2564432633 ProtocCntrlInfo 0;
BA_ "GenSigAutoGenDsp" SG_ 2564432633 ProtocCntrlInfo 0;
BA_ "CI_RepetitionComplemented" SG_ 2564432633 ProtocCntrlInfo 2;
BA_ "CI_FullName" SG_ 2564432633 ProtocCntrlInfo "Protocol Control Information";
BA_ "CI_ParId" SG_ 2564432633 ProtocCntrlInfo "ESMD_02905";
BA_ "GenSigAutoGenSnd" SG_ 2564432633 SepTime 0;
BA_ "GenSigAutoGenDsp" SG_ 2564432633 SepTime 0;
BA_ "CI_RepetitionComplemented" SG_ 2564432633 SepTime 2;
BA_ "CI_FullName" SG_ 2564432633 SepTime "Separation Time";
BA_ "CI_ParId" SG_ 2564432633 SepTime "ESMD_03113";
BA_ "GenSigAutoGenSnd" SG_ 2564432633 SingFrameDataLen 0;
BA_ "GenSigAutoGenDsp" SG_ 2564432633 SingFrameDataLen 0;
BA_ "CI_RepetitionComplemented" SG_ 2564432633 SingFrameDataLen 2;
BA_ "CI_FullName" SG_ 2564432633 SingFrameDataLen "Single Frame Data Length";
BA_ "CI_ParId" SG_ 2564432633 SingFrameDataLen "ESMD_03135";
BA_ "GenSigAutoGenSnd" SG_ 2564432633 SN 0;
BA_ "GenSigAutoGenDsp" SG_ 2564432633 SN 0;
BA_ "CI_RepetitionComplemented" SG_ 2564432633 SN 2;
BA_ "CI_FullName" SG_ 2564432633 SN "Serial Number";
BA_ "CI_ParId" SG_ 2564432633 SN "ESMD_03138";
BA_ "GenSigAutoGenSnd" SG_ 2564487458 ProtocCntrlInfo 0;
BA_ "GenSigAutoGenDsp" SG_ 2564487458 ProtocCntrlInfo 0;
BA_ "CI_RepetitionComplemented" SG_ 2564487458 ProtocCntrlInfo 2;
BA_ "CI_FullName" SG_ 2564487458 ProtocCntrlInfo "Protocol Control Information";
BA_ "CI_ParId" SG_ 2564487458 ProtocCntrlInfo "ESMD_02905";
BA_ "GenSigAutoGenSnd" SG_ 2564487458 SingFrameDataLen 0;
BA_ "GenSigAutoGenDsp" SG_ 2564487458 SingFrameDataLen 0;
BA_ "CI_RepetitionComplemented" SG_ 2564487458 SingFrameDataLen 2;
BA_ "CI_FullName" SG_ 2564487458 SingFrameDataLen "Single Frame Data Length";
BA_ "CI_ParId" SG_ 2564487458 SingFrameDataLen "ESMD_03135";
BA_ "GenSigAutoGenSnd" SG_ 2564487458 N1FrameDataLen 0;
BA_ "GenSigAutoGenDsp" SG_ 2564487458 N1FrameDataLen 0;
BA_ "CI_RepetitionComplemented" SG_ 2564487458 N1FrameDataLen 2;
BA_ "CI_FullName" SG_ 2564487458 N1FrameDataLen "First Frame Data Length";
BA_ "CI_ParId" SG_ 2564487458 N1FrameDataLen "ESMD_01962";
BA_ "GenSigAutoGenSnd" SG_ 2564487458 FlowSts 0;
BA_ "GenSigAutoGenDsp" SG_ 2564487458 FlowSts 0;
BA_ "CI_RepetitionComplemented" SG_ 2564487458 FlowSts 2;
BA_ "CI_FullName" SG_ 2564487458 FlowSts "Flow Status";
BA_ "CI_ParId" SG_ 2564487458 FlowSts "ESMD_01968";
BA_ "GenSigAutoGenSnd" SG_ 2564487458 BlkSize 0;
BA_ "GenSigAutoGenDsp" SG_ 2564487458 BlkSize 0;
BA_ "CI_RepetitionComplemented" SG_ 2564487458 BlkSize 2;
BA_ "CI_FullName" SG_ 2564487458 BlkSize "Block Size";
BA_ "CI_ParId" SG_ 2564487458 BlkSize "ESMD_00809";
BA_ "GenSigAutoGenSnd" SG_ 2564487458 SepTime 0;
BA_ "GenSigAutoGenDsp" SG_ 2564487458 SepTime 0;
BA_ "CI_RepetitionComplemented" SG_ 2564487458 SepTime 2;
BA_ "CI_FullName" SG_ 2564487458 SepTime "Separation Time";
BA_ "CI_ParId" SG_ 2564487458 SepTime "ESMD_03113";
BA_ "GenSigAutoGenSnd" SG_ 2564487458 SN 0;
BA_ "GenSigAutoGenDsp" SG_ 2564487458 SN 0;
BA_ "CI_RepetitionComplemented" SG_ 2564487458 SN 2;
BA_ "CI_FullName" SG_ 2564487458 SN "Serial Number";
BA_ "CI_ParId" SG_ 2564487458 SN "ESMD_03138";
BA_ "GenSigAutoGenSnd" SG_ 2565799929 ArbAddrCap 0;
BA_ "GenSigAutoGenDsp" SG_ 2565799929 ArbAddrCap 0;
BA_ "CI_RepetitionComplemented" SG_ 2565799929 ArbAddrCap 2;
BA_ "CI_FullName" SG_ 2565799929 ArbAddrCap "Arbitrary Address Capable";
BA_ "CI_ParId" SG_ 2565799929 ArbAddrCap "ESMD_08115";
BA_ "SPN" SG_ 2565799929 ArbAddrCap 2844;
BA_ "GenSigAutoGenSnd" SG_ 2565799929 VehSysInst 0;
BA_ "GenSigAutoGenDsp" SG_ 2565799929 VehSysInst 0;
BA_ "CI_RepetitionComplemented" SG_ 2565799929 VehSysInst 2;
BA_ "CI_FullName" SG_ 2565799929 VehSysInst "Vehicle System Instance";
BA_ "CI_ParId" SG_ 2565799929 VehSysInst "ESMD_09571";
BA_ "SPN" SG_ 2565799929 VehSysInst 2843;
BA_ "GenSigAutoGenSnd" SG_ 2565799929 VehSys 0;
BA_ "GenSigAutoGenDsp" SG_ 2565799929 VehSys 0;
BA_ "CI_RepetitionComplemented" SG_ 2565799929 VehSys 2;
BA_ "CI_FullName" SG_ 2565799929 VehSys "Vehicle system";
BA_ "CI_ParId" SG_ 2565799929 VehSys "ESMD_16375";
BA_ "SPN" SG_ 2565799929 VehSys 2842;
BA_ "GenSigAutoGenSnd" SG_ 2565799929 IndstryGrp 0;
BA_ "GenSigAutoGenDsp" SG_ 2565799929 IndstryGrp 0;
BA_ "CI_RepetitionComplemented" SG_ 2565799929 IndstryGrp 2;
BA_ "CI_FullName" SG_ 2565799929 IndstryGrp "Industry Group";
BA_ "CI_ParId" SG_ 2565799929 IndstryGrp "ESMD_02136";
BA_ "SPN" SG_ 2565799929 IndstryGrp 2846;
BA_ "GenSigAutoGenSnd" SG_ 2565799929 Funct 0;
BA_ "GenSigAutoGenDsp" SG_ 2565799929 Funct 0;
BA_ "CI_RepetitionComplemented" SG_ 2565799929 Funct 2;
BA_ "CI_FullName" SG_ 2565799929 Funct "Function";
BA_ "CI_ParId" SG_ 2565799929 Funct "ESMD_08663";
BA_ "SPN" SG_ 2565799929 Funct 2841;
BA_ "GenSigAutoGenSnd" SG_ 2565799929 FunctInst 0;
BA_ "GenSigAutoGenDsp" SG_ 2565799929 FunctInst 0;
BA_ "CI_RepetitionComplemented" SG_ 2565799929 FunctInst 2;
BA_ "CI_FullName" SG_ 2565799929 FunctInst "Function Instance";
BA_ "CI_ParId" SG_ 2565799929 FunctInst "ESMD_08670";
BA_ "SPN" SG_ 2565799929 FunctInst 2839;
BA_ "GenSigAutoGenSnd" SG_ 2565799929 ECU_Inst 0;
BA_ "GenSigAutoGenDsp" SG_ 2565799929 ECU_Inst 0;
BA_ "CI_RepetitionComplemented" SG_ 2565799929 ECU_Inst 2;
BA_ "CI_FullName" SG_ 2565799929 ECU_Inst "ECU Instance";
BA_ "CI_ParId" SG_ 2565799929 ECU_Inst "ESMD_08387";
BA_ "SPN" SG_ 2565799929 ECU_Inst 2840;
BA_ "GenSigAutoGenSnd" SG_ 2565799929 ManufctCod 0;
BA_ "GenSigAutoGenDsp" SG_ 2565799929 ManufctCod 0;
BA_ "CI_RepetitionComplemented" SG_ 2565799929 ManufctCod 2;
BA_ "CI_FullName" SG_ 2565799929 ManufctCod "Manufacturer Code";
BA_ "CI_ParId" SG_ 2565799929 ManufctCod "ESMD_08852";
BA_ "SPN" SG_ 2565799929 ManufctCod 2838;
BA_ "SigType" SG_ 2565799929 ManufctCod 1;
BA_ "GenSigAutoGenSnd" SG_ 2565799929 IdNum 0;
BA_ "GenSigAutoGenDsp" SG_ 2565799929 IdNum 0;
BA_ "CI_RepetitionComplemented" SG_ 2565799929 IdNum 2;
BA_ "CI_FullName" SG_ 2565799929 IdNum "Identity Number";
BA_ "CI_ParId" SG_ 2565799929 IdNum "ESMD_08726";
BA_ "SPN" SG_ 2565799929 IdNum 2837;
BA_ "CI_FullName" SG_ 2565799929 Rsrvd_1Bit "Reserved 1 Bit";
BA_ "CI_ParId" SG_ 2565799929 Rsrvd_1Bit "ESMD_23062";
BA_ "CI_ParId" SG_ 2565537785 PGN_RQST_F9 "ESMD_20258";
BA_ "SPN" SG_ 2565537785 PGN_RQST_F9 2540;
BA_ "SigType" SG_ 2565537785 PGN_RQST_F9 6;
BA_ "GenSigAutoGenSnd" SG_ 2566841896 Day 0;
BA_ "GenSigAutoGenDsp" SG_ 2566841896 Day 0;
BA_ "CI_RepetitionComplemented" SG_ 2566841896 Day 2;
BA_ "CI_FullName" SG_ 2566841896 Day "Day";
BA_ "CI_ParId" SG_ 2566841896 Day "ESMD_01022";
BA_ "CI_SLOT_Name" SG_ 2566841896 Day "SAEcd01";
BA_ "SPN" SG_ 2566841896 Day 962;
BA_ "GenSigAutoGenSnd" SG_ 2566841896 Hour 0;
BA_ "GenSigAutoGenDsp" SG_ 2566841896 Hour 0;
BA_ "CI_RepetitionComplemented" SG_ 2566841896 Hour 2;
BA_ "CI_FullName" SG_ 2566841896 Hour "Hours";
BA_ "CI_ParId" SG_ 2566841896 Hour "ESMD_02087";
BA_ "CI_SLOT_Name" SG_ 2566841896 Hour "SAEtm11";
BA_ "SPN" SG_ 2566841896 Hour 961;
BA_ "GenSigAutoGenSnd" SG_ 2566841896 LocalHourOfs 0;
BA_ "GenSigAutoGenDsp" SG_ 2566841896 LocalHourOfs 0;
BA_ "UtilizationOnNetwork" SG_ 2566841896 LocalHourOfs 1;
BA_ "CI_RepetitionComplemented" SG_ 2566841896 LocalHourOfs 2;
BA_ "CI_FullName" SG_ 2566841896 LocalHourOfs "Local hour offset";
BA_ "CI_ParId" SG_ 2566841896 LocalHourOfs "ESMD_02619";
BA_ "CI_SLOT_Name" SG_ 2566841896 LocalHourOfs "SAEtm10";
BA_ "SPN" SG_ 2566841896 LocalHourOfs 1602;
BA_ "GenSigAutoGenSnd" SG_ 2566841896 LocalMinutOfs 0;
BA_ "GenSigAutoGenDsp" SG_ 2566841896 LocalMinutOfs 0;
BA_ "UtilizationOnNetwork" SG_ 2566841896 LocalMinutOfs 1;
BA_ "CI_RepetitionComplemented" SG_ 2566841896 LocalMinutOfs 2;
BA_ "CI_FullName" SG_ 2566841896 LocalMinutOfs "Local minute offset";
BA_ "CI_ParId" SG_ 2566841896 LocalMinutOfs "ESMD_02620";
BA_ "CI_SLOT_Name" SG_ 2566841896 LocalMinutOfs "SAEtm07";
BA_ "SPN" SG_ 2566841896 LocalMinutOfs 1601;
BA_ "GenSigAutoGenSnd" SG_ 2566841896 Minut 0;
BA_ "GenSigAutoGenDsp" SG_ 2566841896 Minut 0;
BA_ "CI_RepetitionComplemented" SG_ 2566841896 Minut 2;
BA_ "CI_FullName" SG_ 2566841896 Minut "Minutes";
BA_ "CI_ParId" SG_ 2566841896 Minut "ESMD_02704";
BA_ "CI_SLOT_Name" SG_ 2566841896 Minut "SAEtm08";
BA_ "SPN" SG_ 2566841896 Minut 960;
BA_ "GenSigAutoGenSnd" SG_ 2566841896 Month 0;
BA_ "GenSigAutoGenDsp" SG_ 2566841896 Month 0;
BA_ "CI_RepetitionComplemented" SG_ 2566841896 Month 2;
BA_ "CI_FullName" SG_ 2566841896 Month "Month";
BA_ "CI_ParId" SG_ 2566841896 Month "ESMD_02719";
BA_ "CI_SLOT_Name" SG_ 2566841896 Month "SAEcm01";
BA_ "SPN" SG_ 2566841896 Month 963;
BA_ "GenSigAutoGenSnd" SG_ 2566841896 Sec 0;
BA_ "GenSigAutoGenDsp" SG_ 2566841896 Sec 0;
BA_ "CI_RepetitionComplemented" SG_ 2566841896 Sec 2;
BA_ "CI_FullName" SG_ 2566841896 Sec "Seconds";
BA_ "CI_ParId" SG_ 2566841896 Sec "ESMD_03098";
BA_ "CI_SLOT_Name" SG_ 2566841896 Sec "SAEtm04";
BA_ "SPN" SG_ 2566841896 Sec 959;
BA_ "GenSigAutoGenSnd" SG_ 2566841896 Year 0;
BA_ "GenSigAutoGenDsp" SG_ 2566841896 Year 0;
BA_ "CI_RepetitionComplemented" SG_ 2566841896 Year 2;
BA_ "CI_FullName" SG_ 2566841896 Year "Year";
BA_ "CI_ParId" SG_ 2566841896 Year "ESMD_03830";
BA_ "CI_SLOT_Name" SG_ 2566841896 Year "SAEcy01";
BA_ "SPN" SG_ 2566841896 Year 964;
BA_ "GenSigAutoGenSnd" SG_ 2564459001 BlkSize 0;
BA_ "GenSigAutoGenDsp" SG_ 2564459001 BlkSize 0;
BA_ "CI_RepetitionComplemented" SG_ 2564459001 BlkSize 2;
BA_ "CI_FullName" SG_ 2564459001 BlkSize "Block Size";
BA_ "CI_ParId" SG_ 2564459001 BlkSize "ESMD_00809";
BA_ "GenSigAutoGenSnd" SG_ 2564459001 FlowSts 0;
BA_ "GenSigAutoGenDsp" SG_ 2564459001 FlowSts 0;
BA_ "CI_RepetitionComplemented" SG_ 2564459001 FlowSts 2;
BA_ "CI_FullName" SG_ 2564459001 FlowSts "Flow Status";
BA_ "CI_ParId" SG_ 2564459001 FlowSts "ESMD_01968";
BA_ "GenSigAutoGenSnd" SG_ 2564459001 N1FrameDataLen 0;
BA_ "GenSigAutoGenDsp" SG_ 2564459001 N1FrameDataLen 0;
BA_ "CI_RepetitionComplemented" SG_ 2564459001 N1FrameDataLen 2;
BA_ "CI_FullName" SG_ 2564459001 N1FrameDataLen "First Frame Data Length";
BA_ "CI_ParId" SG_ 2564459001 N1FrameDataLen "ESMD_01962";
BA_ "GenSigAutoGenSnd" SG_ 2564459001 ProtocCntrlInfo 0;
BA_ "GenSigAutoGenDsp" SG_ 2564459001 ProtocCntrlInfo 0;
BA_ "CI_RepetitionComplemented" SG_ 2564459001 ProtocCntrlInfo 2;
BA_ "CI_FullName" SG_ 2564459001 ProtocCntrlInfo "Protocol Control Information";
BA_ "CI_ParId" SG_ 2564459001 ProtocCntrlInfo "ESMD_02905";
BA_ "GenSigAutoGenSnd" SG_ 2564459001 SepTime 0;
BA_ "GenSigAutoGenDsp" SG_ 2564459001 SepTime 0;
BA_ "CI_RepetitionComplemented" SG_ 2564459001 SepTime 2;
BA_ "CI_FullName" SG_ 2564459001 SepTime "Separation Time";
BA_ "CI_ParId" SG_ 2564459001 SepTime "ESMD_03113";
BA_ "GenSigAutoGenSnd" SG_ 2564459001 SingFrameDataLen 0;
BA_ "GenSigAutoGenDsp" SG_ 2564459001 SingFrameDataLen 0;
BA_ "CI_RepetitionComplemented" SG_ 2564459001 SingFrameDataLen 2;
BA_ "CI_FullName" SG_ 2564459001 SingFrameDataLen "Single Frame Data Length";
BA_ "CI_ParId" SG_ 2564459001 SingFrameDataLen "ESMD_03135";
BA_ "GenSigAutoGenSnd" SG_ 2564459001 SN 0;
BA_ "GenSigAutoGenDsp" SG_ 2564459001 SN 0;
BA_ "CI_RepetitionComplemented" SG_ 2564459001 SN 2;
BA_ "CI_FullName" SG_ 2564459001 SN "Serial Number";
BA_ "CI_ParId" SG_ 2564459001 SN "ESMD_03138";
BA_ "CI_FullName" SG_ 2566843273 UnitNumPwrUnit "Unit Number (Power Unit)";
BA_ "CI_ParId" SG_ 2566843273 UnitNumPwrUnit "ESMD_03702";
BA_ "CI_SLOT_Name" SG_ 2566843273 UnitNumPwrUnit "SAEatad0200";
BA_ "SPN" SG_ 2566843273 UnitNumPwrUnit 233;
BA_ "CI_FullName" SG_ 2566843273 SN_2_Byte_15 "Serial Number 2";
BA_ "CI_ParId" SG_ 2566843273 SN_2_Byte_15 "ESMD_03115";
BA_ "CI_SLOT_Name" SG_ 2566843273 SN_2_Byte_15 "SAEatad0200";
BA_ "SPN" SG_ 2566843273 SN_2_Byte_15 588;
BA_ "SigType" SG_ 2566843273 SN_2_Byte_15 8;
BA_ "CI_FullName" SG_ 2566843273 SN_2_Byte_14 "Serial Number 2";
BA_ "CI_ParId" SG_ 2566843273 SN_2_Byte_14 "ESMD_03115";
BA_ "CI_SLOT_Name" SG_ 2566843273 SN_2_Byte_14 "SAEatad0200";
BA_ "SPN" SG_ 2566843273 SN_2_Byte_14 588;
BA_ "SigType" SG_ 2566843273 SN_2_Byte_14 8;
BA_ "CI_FullName" SG_ 2566843273 SN_2_Byte_13 "Serial Number 2";
BA_ "CI_ParId" SG_ 2566843273 SN_2_Byte_13 "ESMD_03115";
BA_ "CI_SLOT_Name" SG_ 2566843273 SN_2_Byte_13 "SAEatad0200";
BA_ "SPN" SG_ 2566843273 SN_2_Byte_13 588;
BA_ "SigType" SG_ 2566843273 SN_2_Byte_13 8;
BA_ "CI_FullName" SG_ 2566843273 SN_2_Byte_12 "Serial Number 2";
BA_ "CI_ParId" SG_ 2566843273 SN_2_Byte_12 "ESMD_03115";
BA_ "CI_SLOT_Name" SG_ 2566843273 SN_2_Byte_12 "SAEatad0200";
BA_ "SPN" SG_ 2566843273 SN_2_Byte_12 588;
BA_ "SigType" SG_ 2566843273 SN_2_Byte_12 8;
BA_ "CI_FullName" SG_ 2566843273 SN_2_Byte_11 "Serial Number 2";
BA_ "CI_ParId" SG_ 2566843273 SN_2_Byte_11 "ESMD_03115";
BA_ "CI_SLOT_Name" SG_ 2566843273 SN_2_Byte_11 "SAEatad0200";
BA_ "SPN" SG_ 2566843273 SN_2_Byte_11 588;
BA_ "SigType" SG_ 2566843273 SN_2_Byte_11 8;
BA_ "CI_FullName" SG_ 2566843273 SN_2_Byte_10 "Serial Number 2";
BA_ "CI_ParId" SG_ 2566843273 SN_2_Byte_10 "ESMD_03115";
BA_ "CI_SLOT_Name" SG_ 2566843273 SN_2_Byte_10 "SAEatad0200";
BA_ "SPN" SG_ 2566843273 SN_2_Byte_10 588;
BA_ "SigType" SG_ 2566843273 SN_2_Byte_10 8;
BA_ "CI_FullName" SG_ 2566843273 SN_2_Byte_09 "Serial Number 2";
BA_ "CI_ParId" SG_ 2566843273 SN_2_Byte_09 "ESMD_03115";
BA_ "CI_SLOT_Name" SG_ 2566843273 SN_2_Byte_09 "SAEatad0200";
BA_ "SPN" SG_ 2566843273 SN_2_Byte_09 588;
BA_ "SigType" SG_ 2566843273 SN_2_Byte_09 8;
BA_ "CI_FullName" SG_ 2566843273 SN_2_Byte_08 "Serial Number 2";
BA_ "CI_ParId" SG_ 2566843273 SN_2_Byte_08 "ESMD_03115";
BA_ "CI_SLOT_Name" SG_ 2566843273 SN_2_Byte_08 "SAEatad0200";
BA_ "SPN" SG_ 2566843273 SN_2_Byte_08 588;
BA_ "SigType" SG_ 2566843273 SN_2_Byte_08 8;
BA_ "CI_FullName" SG_ 2566843273 SN_2_Byte_07 "Serial Number 2";
BA_ "CI_ParId" SG_ 2566843273 SN_2_Byte_07 "ESMD_03115";
BA_ "CI_SLOT_Name" SG_ 2566843273 SN_2_Byte_07 "SAEatad0200";
BA_ "SPN" SG_ 2566843273 SN_2_Byte_07 588;
BA_ "SigType" SG_ 2566843273 SN_2_Byte_07 8;
BA_ "CI_FullName" SG_ 2566843273 SN_2_Byte_06 "Serial Number 2";
BA_ "CI_ParId" SG_ 2566843273 SN_2_Byte_06 "ESMD_03115";
BA_ "CI_SLOT_Name" SG_ 2566843273 SN_2_Byte_06 "SAEatad0200";
BA_ "SPN" SG_ 2566843273 SN_2_Byte_06 588;
BA_ "SigType" SG_ 2566843273 SN_2_Byte_06 8;
BA_ "CI_FullName" SG_ 2566843273 SN_2_Byte_05 "Serial Number 2";
BA_ "CI_ParId" SG_ 2566843273 SN_2_Byte_05 "ESMD_03115";
BA_ "CI_SLOT_Name" SG_ 2566843273 SN_2_Byte_05 "SAEatad0200";
BA_ "SPN" SG_ 2566843273 SN_2_Byte_05 588;
BA_ "SigType" SG_ 2566843273 SN_2_Byte_05 8;
BA_ "CI_FullName" SG_ 2566843273 SN_2_Byte_04 "Serial Number 2";
BA_ "CI_ParId" SG_ 2566843273 SN_2_Byte_04 "ESMD_03115";
BA_ "CI_SLOT_Name" SG_ 2566843273 SN_2_Byte_04 "SAEatad0200";
BA_ "SPN" SG_ 2566843273 SN_2_Byte_04 588;
BA_ "SigType" SG_ 2566843273 SN_2_Byte_04 8;
BA_ "CI_FullName" SG_ 2566843273 SN_2_Byte_03 "Serial Number 2";
BA_ "CI_ParId" SG_ 2566843273 SN_2_Byte_03 "ESMD_03115";
BA_ "CI_SLOT_Name" SG_ 2566843273 SN_2_Byte_03 "SAEatad0200";
BA_ "SPN" SG_ 2566843273 SN_2_Byte_03 588;
BA_ "SigType" SG_ 2566843273 SN_2_Byte_03 8;
BA_ "CI_FullName" SG_ 2566843273 SN_2_Byte_02 "Serial Number 2";
BA_ "CI_ParId" SG_ 2566843273 SN_2_Byte_02 "ESMD_03115";
BA_ "CI_SLOT_Name" SG_ 2566843273 SN_2_Byte_02 "SAEatad0200";
BA_ "SPN" SG_ 2566843273 SN_2_Byte_02 588;
BA_ "SigType" SG_ 2566843273 SN_2_Byte_02 8;
BA_ "CI_FullName" SG_ 2566843273 SN_2_Byte_01 "Serial Number 2";
BA_ "CI_ParId" SG_ 2566843273 SN_2_Byte_01 "ESMD_03115";
BA_ "CI_SLOT_Name" SG_ 2566843273 SN_2_Byte_01 "SAEatad0200";
BA_ "SPN" SG_ 2566843273 SN_2_Byte_01 588;
BA_ "SigType" SG_ 2566843273 SN_2_Byte_01 8;
BA_ "CI_FullName" SG_ 2566843273 SN_2 "Serial Number 2";
BA_ "CI_ParId" SG_ 2566843273 SN_2 "ESMD_03115";
BA_ "CI_SLOT_Name" SG_ 2566843273 SN_2 "SAEatad0200";
BA_ "SPN" SG_ 2566843273 SN_2 588;
BA_ "CI_FullName" SG_ 2566843273 Mdl_Byte_08 "Model";
BA_ "CI_ParId" SG_ 2566843273 Mdl_Byte_08 "ESMD_02715";
BA_ "CI_SLOT_Name" SG_ 2566843273 Mdl_Byte_08 "SAEatad0200";
BA_ "SPN" SG_ 2566843273 Mdl_Byte_08 587;
BA_ "SigType" SG_ 2566843273 Mdl_Byte_08 8;
BA_ "CI_FullName" SG_ 2566843273 Mdl_Byte_07 "Model";
BA_ "CI_ParId" SG_ 2566843273 Mdl_Byte_07 "ESMD_02715";
BA_ "CI_SLOT_Name" SG_ 2566843273 Mdl_Byte_07 "SAEatad0200";
BA_ "SPN" SG_ 2566843273 Mdl_Byte_07 587;
BA_ "SigType" SG_ 2566843273 Mdl_Byte_07 8;
BA_ "CI_FullName" SG_ 2566843273 Mdl_Byte_06 "Model";
BA_ "CI_ParId" SG_ 2566843273 Mdl_Byte_06 "ESMD_02715";
BA_ "CI_SLOT_Name" SG_ 2566843273 Mdl_Byte_06 "SAEatad0200";
BA_ "SPN" SG_ 2566843273 Mdl_Byte_06 587;
BA_ "SigType" SG_ 2566843273 Mdl_Byte_06 8;
BA_ "CI_FullName" SG_ 2566843273 Mdl_Byte_05 "Model";
BA_ "CI_ParId" SG_ 2566843273 Mdl_Byte_05 "ESMD_02715";
BA_ "CI_SLOT_Name" SG_ 2566843273 Mdl_Byte_05 "SAEatad0200";
BA_ "SPN" SG_ 2566843273 Mdl_Byte_05 587;
BA_ "SigType" SG_ 2566843273 Mdl_Byte_05 8;
BA_ "CI_FullName" SG_ 2566843273 Mdl_Byte_04 "Model";
BA_ "CI_ParId" SG_ 2566843273 Mdl_Byte_04 "ESMD_02715";
BA_ "CI_SLOT_Name" SG_ 2566843273 Mdl_Byte_04 "SAEatad0200";
BA_ "SPN" SG_ 2566843273 Mdl_Byte_04 587;
BA_ "SigType" SG_ 2566843273 Mdl_Byte_04 8;
BA_ "CI_FullName" SG_ 2566843273 Mdl_Byte_03 "Model";
BA_ "CI_ParId" SG_ 2566843273 Mdl_Byte_03 "ESMD_02715";
BA_ "CI_SLOT_Name" SG_ 2566843273 Mdl_Byte_03 "SAEatad0200";
BA_ "SPN" SG_ 2566843273 Mdl_Byte_03 587;
BA_ "SigType" SG_ 2566843273 Mdl_Byte_03 8;
BA_ "CI_FullName" SG_ 2566843273 Mdl_Byte_02 "Model";
BA_ "CI_ParId" SG_ 2566843273 Mdl_Byte_02 "ESMD_02715";
BA_ "CI_SLOT_Name" SG_ 2566843273 Mdl_Byte_02 "SAEatad0200";
BA_ "SPN" SG_ 2566843273 Mdl_Byte_02 587;
BA_ "SigType" SG_ 2566843273 Mdl_Byte_02 8;
BA_ "CI_FullName" SG_ 2566843273 Mdl_Byte_01 "Model";
BA_ "CI_ParId" SG_ 2566843273 Mdl_Byte_01 "ESMD_02715";
BA_ "CI_SLOT_Name" SG_ 2566843273 Mdl_Byte_01 "SAEatad0200";
BA_ "SPN" SG_ 2566843273 Mdl_Byte_01 587;
BA_ "SigType" SG_ 2566843273 Mdl_Byte_01 8;
BA_ "CI_FullName" SG_ 2566843273 Make "Make";
BA_ "CI_ParId" SG_ 2566843273 Make "ESMD_02671";
BA_ "CI_SLOT_Name" SG_ 2566843273 Make "SAEatad0005";
BA_ "SPN" SG_ 2566843273 Make 586;
BA_ "CI_FullName" SG_ 2566843273 Mdl "Model";
BA_ "CI_ParId" SG_ 2566843273 Mdl "ESMD_02715";
BA_ "CI_SLOT_Name" SG_ 2566843273 Mdl "SAEatad0200";
BA_ "SPN" SG_ 2566843273 Mdl 587;
BA_ "GenSigAutoGenSnd" SG_ 2564487561 SepTime 0;
BA_ "GenSigAutoGenDsp" SG_ 2564487561 SepTime 0;
BA_ "CI_RepetitionComplemented" SG_ 2564487561 SepTime 2;
BA_ "CI_FullName" SG_ 2564487561 SepTime "Separation Time";
BA_ "CI_ParId" SG_ 2564487561 SepTime "ESMD_03113";
BA_ "GenSigAutoGenSnd" SG_ 2564487561 SingFrameDataLen 0;
BA_ "GenSigAutoGenDsp" SG_ 2564487561 SingFrameDataLen 0;
BA_ "CI_RepetitionComplemented" SG_ 2564487561 SingFrameDataLen 2;
BA_ "CI_FullName" SG_ 2564487561 SingFrameDataLen "Single Frame Data Length";
BA_ "CI_ParId" SG_ 2564487561 SingFrameDataLen "ESMD_03135";
BA_ "GenSigAutoGenSnd" SG_ 2564487561 N1FrameDataLen 0;
BA_ "GenSigAutoGenDsp" SG_ 2564487561 N1FrameDataLen 0;
BA_ "CI_RepetitionComplemented" SG_ 2564487561 N1FrameDataLen 2;
BA_ "CI_FullName" SG_ 2564487561 N1FrameDataLen "First Frame Data Length";
BA_ "CI_ParId" SG_ 2564487561 N1FrameDataLen "ESMD_01962";
BA_ "GenSigAutoGenSnd" SG_ 2564487561 BlkSize 0;
BA_ "GenSigAutoGenDsp" SG_ 2564487561 BlkSize 0;
BA_ "CI_RepetitionComplemented" SG_ 2564487561 BlkSize 2;
BA_ "CI_FullName" SG_ 2564487561 BlkSize "Block Size";
BA_ "CI_ParId" SG_ 2564487561 BlkSize "ESMD_00809";
BA_ "GenSigAutoGenSnd" SG_ 2564487561 FlowSts 0;
BA_ "GenSigAutoGenDsp" SG_ 2564487561 FlowSts 0;
BA_ "CI_RepetitionComplemented" SG_ 2564487561 FlowSts 2;
BA_ "CI_FullName" SG_ 2564487561 FlowSts "Flow Status";
BA_ "CI_ParId" SG_ 2564487561 FlowSts "ESMD_01968";
BA_ "GenSigAutoGenSnd" SG_ 2564487561 SN 0;
BA_ "GenSigAutoGenDsp" SG_ 2564487561 SN 0;
BA_ "CI_RepetitionComplemented" SG_ 2564487561 SN 2;
BA_ "CI_FullName" SG_ 2564487561 SN "Serial Number";
BA_ "CI_ParId" SG_ 2564487561 SN "ESMD_03138";
BA_ "GenSigAutoGenSnd" SG_ 2564487561 ProtocCntrlInfo 0;
BA_ "GenSigAutoGenDsp" SG_ 2564487561 ProtocCntrlInfo 0;
BA_ "CI_RepetitionComplemented" SG_ 2564487561 ProtocCntrlInfo 2;
BA_ "CI_FullName" SG_ 2564487561 ProtocCntrlInfo "Protocol Control Information";
BA_ "CI_ParId" SG_ 2564487561 ProtocCntrlInfo "ESMD_02905";
BA_ "GenSigAutoGenSnd" SG_ 2564457721 BlkSize 0;
BA_ "GenSigAutoGenDsp" SG_ 2564457721 BlkSize 0;
BA_ "CI_RepetitionComplemented" SG_ 2564457721 BlkSize 2;
BA_ "CI_FullName" SG_ 2564457721 BlkSize "Block Size";
BA_ "CI_ParId" SG_ 2564457721 BlkSize "ESMD_00809";
BA_ "GenSigAutoGenSnd" SG_ 2564457721 FlowSts 0;
BA_ "GenSigAutoGenDsp" SG_ 2564457721 FlowSts 0;
BA_ "CI_RepetitionComplemented" SG_ 2564457721 FlowSts 2;
BA_ "CI_FullName" SG_ 2564457721 FlowSts "Flow Status";
BA_ "CI_ParId" SG_ 2564457721 FlowSts "ESMD_01968";
BA_ "GenSigAutoGenSnd" SG_ 2564457721 N1FrameDataLen 0;
BA_ "GenSigAutoGenDsp" SG_ 2564457721 N1FrameDataLen 0;
BA_ "CI_RepetitionComplemented" SG_ 2564457721 N1FrameDataLen 2;
BA_ "CI_FullName" SG_ 2564457721 N1FrameDataLen "First Frame Data Length";
BA_ "CI_ParId" SG_ 2564457721 N1FrameDataLen "ESMD_01962";
BA_ "GenSigAutoGenSnd" SG_ 2564457721 ProtocCntrlInfo 0;
BA_ "GenSigAutoGenDsp" SG_ 2564457721 ProtocCntrlInfo 0;
BA_ "CI_RepetitionComplemented" SG_ 2564457721 ProtocCntrlInfo 2;
BA_ "CI_FullName" SG_ 2564457721 ProtocCntrlInfo "Protocol Control Information";
BA_ "CI_ParId" SG_ 2564457721 ProtocCntrlInfo "ESMD_02905";
BA_ "GenSigAutoGenSnd" SG_ 2564457721 SepTime 0;
BA_ "GenSigAutoGenDsp" SG_ 2564457721 SepTime 0;
BA_ "CI_RepetitionComplemented" SG_ 2564457721 SepTime 2;
BA_ "CI_FullName" SG_ 2564457721 SepTime "Separation Time";
BA_ "CI_ParId" SG_ 2564457721 SepTime "ESMD_03113";
BA_ "GenSigAutoGenSnd" SG_ 2564457721 SingFrameDataLen 0;
BA_ "GenSigAutoGenDsp" SG_ 2564457721 SingFrameDataLen 0;
BA_ "CI_RepetitionComplemented" SG_ 2564457721 SingFrameDataLen 2;
BA_ "CI_FullName" SG_ 2564457721 SingFrameDataLen "Single Frame Data Length";
BA_ "CI_ParId" SG_ 2564457721 SingFrameDataLen "ESMD_03135";
BA_ "GenSigAutoGenSnd" SG_ 2564457721 SN 0;
BA_ "GenSigAutoGenDsp" SG_ 2564457721 SN 0;
BA_ "CI_RepetitionComplemented" SG_ 2564457721 SN 2;
BA_ "CI_FullName" SG_ 2564457721 SN "Serial Number";
BA_ "CI_ParId" SG_ 2564457721 SN "ESMD_03138";
BA_ "CI_FullName" SG_ 2566843268 UnitNumPwrUnit "Unit Number (Power Unit)";
BA_ "CI_ParId" SG_ 2566843268 UnitNumPwrUnit "ESMD_03702";
BA_ "CI_SLOT_Name" SG_ 2566843268 UnitNumPwrUnit "SAEatad0200";
BA_ "SPN" SG_ 2566843268 UnitNumPwrUnit 233;
BA_ "CI_FullName" SG_ 2566843268 SN_2_Byte_15 "Serial Number 2";
BA_ "CI_ParId" SG_ 2566843268 SN_2_Byte_15 "ESMD_03115";
BA_ "CI_SLOT_Name" SG_ 2566843268 SN_2_Byte_15 "SAEatad0200";
BA_ "SPN" SG_ 2566843268 SN_2_Byte_15 588;
BA_ "SigType" SG_ 2566843268 SN_2_Byte_15 8;
BA_ "CI_FullName" SG_ 2566843268 SN_2_Byte_14 "Serial Number 2";
BA_ "CI_ParId" SG_ 2566843268 SN_2_Byte_14 "ESMD_03115";
BA_ "CI_SLOT_Name" SG_ 2566843268 SN_2_Byte_14 "SAEatad0200";
BA_ "SPN" SG_ 2566843268 SN_2_Byte_14 588;
BA_ "SigType" SG_ 2566843268 SN_2_Byte_14 8;
BA_ "CI_FullName" SG_ 2566843268 SN_2_Byte_13 "Serial Number 2";
BA_ "CI_ParId" SG_ 2566843268 SN_2_Byte_13 "ESMD_03115";
BA_ "CI_SLOT_Name" SG_ 2566843268 SN_2_Byte_13 "SAEatad0200";
BA_ "SPN" SG_ 2566843268 SN_2_Byte_13 588;
BA_ "SigType" SG_ 2566843268 SN_2_Byte_13 8;
BA_ "CI_FullName" SG_ 2566843268 SN_2_Byte_12 "Serial Number 2";
BA_ "CI_ParId" SG_ 2566843268 SN_2_Byte_12 "ESMD_03115";
BA_ "CI_SLOT_Name" SG_ 2566843268 SN_2_Byte_12 "SAEatad0200";
BA_ "SPN" SG_ 2566843268 SN_2_Byte_12 588;
BA_ "SigType" SG_ 2566843268 SN_2_Byte_12 8;
BA_ "CI_FullName" SG_ 2566843268 SN_2_Byte_11 "Serial Number 2";
BA_ "CI_ParId" SG_ 2566843268 SN_2_Byte_11 "ESMD_03115";
BA_ "CI_SLOT_Name" SG_ 2566843268 SN_2_Byte_11 "SAEatad0200";
BA_ "SPN" SG_ 2566843268 SN_2_Byte_11 588;
BA_ "SigType" SG_ 2566843268 SN_2_Byte_11 8;
BA_ "CI_FullName" SG_ 2566843268 SN_2_Byte_10 "Serial Number 2";
BA_ "CI_ParId" SG_ 2566843268 SN_2_Byte_10 "ESMD_03115";
BA_ "CI_SLOT_Name" SG_ 2566843268 SN_2_Byte_10 "SAEatad0200";
BA_ "SPN" SG_ 2566843268 SN_2_Byte_10 588;
BA_ "SigType" SG_ 2566843268 SN_2_Byte_10 8;
BA_ "CI_FullName" SG_ 2566843268 SN_2_Byte_09 "Serial Number 2";
BA_ "CI_ParId" SG_ 2566843268 SN_2_Byte_09 "ESMD_03115";
BA_ "CI_SLOT_Name" SG_ 2566843268 SN_2_Byte_09 "SAEatad0200";
BA_ "SPN" SG_ 2566843268 SN_2_Byte_09 588;
BA_ "SigType" SG_ 2566843268 SN_2_Byte_09 8;
BA_ "CI_FullName" SG_ 2566843268 SN_2_Byte_08 "Serial Number 2";
BA_ "CI_ParId" SG_ 2566843268 SN_2_Byte_08 "ESMD_03115";
BA_ "CI_SLOT_Name" SG_ 2566843268 SN_2_Byte_08 "SAEatad0200";
BA_ "SPN" SG_ 2566843268 SN_2_Byte_08 588;
BA_ "SigType" SG_ 2566843268 SN_2_Byte_08 8;
BA_ "CI_FullName" SG_ 2566843268 SN_2_Byte_07 "Serial Number 2";
BA_ "CI_ParId" SG_ 2566843268 SN_2_Byte_07 "ESMD_03115";
BA_ "CI_SLOT_Name" SG_ 2566843268 SN_2_Byte_07 "SAEatad0200";
BA_ "SPN" SG_ 2566843268 SN_2_Byte_07 588;
BA_ "SigType" SG_ 2566843268 SN_2_Byte_07 8;
BA_ "CI_FullName" SG_ 2566843268 SN_2_Byte_06 "Serial Number 2";
BA_ "CI_ParId" SG_ 2566843268 SN_2_Byte_06 "ESMD_03115";
BA_ "CI_SLOT_Name" SG_ 2566843268 SN_2_Byte_06 "SAEatad0200";
BA_ "SPN" SG_ 2566843268 SN_2_Byte_06 588;
BA_ "SigType" SG_ 2566843268 SN_2_Byte_06 8;
BA_ "CI_FullName" SG_ 2566843268 SN_2_Byte_05 "Serial Number 2";
BA_ "CI_ParId" SG_ 2566843268 SN_2_Byte_05 "ESMD_03115";
BA_ "CI_SLOT_Name" SG_ 2566843268 SN_2_Byte_05 "SAEatad0200";
BA_ "SPN" SG_ 2566843268 SN_2_Byte_05 588;
BA_ "SigType" SG_ 2566843268 SN_2_Byte_05 8;
BA_ "CI_FullName" SG_ 2566843268 SN_2_Byte_04 "Serial Number 2";
BA_ "CI_ParId" SG_ 2566843268 SN_2_Byte_04 "ESMD_03115";
BA_ "CI_SLOT_Name" SG_ 2566843268 SN_2_Byte_04 "SAEatad0200";
BA_ "SPN" SG_ 2566843268 SN_2_Byte_04 588;
BA_ "SigType" SG_ 2566843268 SN_2_Byte_04 8;
BA_ "CI_FullName" SG_ 2566843268 SN_2_Byte_03 "Serial Number 2";
BA_ "CI_ParId" SG_ 2566843268 SN_2_Byte_03 "ESMD_03115";
BA_ "CI_SLOT_Name" SG_ 2566843268 SN_2_Byte_03 "SAEatad0200";
BA_ "SPN" SG_ 2566843268 SN_2_Byte_03 588;
BA_ "SigType" SG_ 2566843268 SN_2_Byte_03 8;
BA_ "CI_FullName" SG_ 2566843268 SN_2_Byte_02 "Serial Number 2";
BA_ "CI_ParId" SG_ 2566843268 SN_2_Byte_02 "ESMD_03115";
BA_ "CI_SLOT_Name" SG_ 2566843268 SN_2_Byte_02 "SAEatad0200";
BA_ "SPN" SG_ 2566843268 SN_2_Byte_02 588;
BA_ "SigType" SG_ 2566843268 SN_2_Byte_02 8;
BA_ "CI_FullName" SG_ 2566843268 SN_2_Byte_01 "Serial Number 2";
BA_ "CI_ParId" SG_ 2566843268 SN_2_Byte_01 "ESMD_03115";
BA_ "CI_SLOT_Name" SG_ 2566843268 SN_2_Byte_01 "SAEatad0200";
BA_ "SPN" SG_ 2566843268 SN_2_Byte_01 588;
BA_ "SigType" SG_ 2566843268 SN_2_Byte_01 8;
BA_ "CI_FullName" SG_ 2566843268 SN_2 "Serial Number 2";
BA_ "CI_ParId" SG_ 2566843268 SN_2 "ESMD_03115";
BA_ "CI_SLOT_Name" SG_ 2566843268 SN_2 "SAEatad0200";
BA_ "SPN" SG_ 2566843268 SN_2 588;
BA_ "CI_FullName" SG_ 2566843268 Mdl_Byte_08 "Model";
BA_ "CI_ParId" SG_ 2566843268 Mdl_Byte_08 "ESMD_02715";
BA_ "CI_SLOT_Name" SG_ 2566843268 Mdl_Byte_08 "SAEatad0200";
BA_ "SPN" SG_ 2566843268 Mdl_Byte_08 587;
BA_ "SigType" SG_ 2566843268 Mdl_Byte_08 8;
BA_ "CI_FullName" SG_ 2566843268 Mdl_Byte_07 "Model";
BA_ "CI_ParId" SG_ 2566843268 Mdl_Byte_07 "ESMD_02715";
BA_ "CI_SLOT_Name" SG_ 2566843268 Mdl_Byte_07 "SAEatad0200";
BA_ "SPN" SG_ 2566843268 Mdl_Byte_07 587;
BA_ "SigType" SG_ 2566843268 Mdl_Byte_07 8;
BA_ "CI_FullName" SG_ 2566843268 Mdl_Byte_06 "Model";
BA_ "CI_ParId" SG_ 2566843268 Mdl_Byte_06 "ESMD_02715";
BA_ "CI_SLOT_Name" SG_ 2566843268 Mdl_Byte_06 "SAEatad0200";
BA_ "SPN" SG_ 2566843268 Mdl_Byte_06 587;
BA_ "SigType" SG_ 2566843268 Mdl_Byte_06 8;
BA_ "CI_FullName" SG_ 2566843268 Mdl_Byte_05 "Model";
BA_ "CI_ParId" SG_ 2566843268 Mdl_Byte_05 "ESMD_02715";
BA_ "CI_SLOT_Name" SG_ 2566843268 Mdl_Byte_05 "SAEatad0200";
BA_ "SPN" SG_ 2566843268 Mdl_Byte_05 587;
BA_ "SigType" SG_ 2566843268 Mdl_Byte_05 8;
BA_ "CI_FullName" SG_ 2566843268 Mdl_Byte_04 "Model";
BA_ "CI_ParId" SG_ 2566843268 Mdl_Byte_04 "ESMD_02715";
BA_ "CI_SLOT_Name" SG_ 2566843268 Mdl_Byte_04 "SAEatad0200";
BA_ "SPN" SG_ 2566843268 Mdl_Byte_04 587;
BA_ "SigType" SG_ 2566843268 Mdl_Byte_04 8;
BA_ "CI_FullName" SG_ 2566843268 Mdl_Byte_03 "Model";
BA_ "CI_ParId" SG_ 2566843268 Mdl_Byte_03 "ESMD_02715";
BA_ "CI_SLOT_Name" SG_ 2566843268 Mdl_Byte_03 "SAEatad0200";
BA_ "SPN" SG_ 2566843268 Mdl_Byte_03 587;
BA_ "SigType" SG_ 2566843268 Mdl_Byte_03 8;
BA_ "CI_FullName" SG_ 2566843268 Mdl_Byte_02 "Model";
BA_ "CI_ParId" SG_ 2566843268 Mdl_Byte_02 "ESMD_02715";
BA_ "CI_SLOT_Name" SG_ 2566843268 Mdl_Byte_02 "SAEatad0200";
BA_ "SPN" SG_ 2566843268 Mdl_Byte_02 587;
BA_ "SigType" SG_ 2566843268 Mdl_Byte_02 8;
BA_ "CI_FullName" SG_ 2566843268 Mdl_Byte_01 "Model";
BA_ "CI_ParId" SG_ 2566843268 Mdl_Byte_01 "ESMD_02715";
BA_ "CI_SLOT_Name" SG_ 2566843268 Mdl_Byte_01 "SAEatad0200";
BA_ "SPN" SG_ 2566843268 Mdl_Byte_01 587;
BA_ "SigType" SG_ 2566843268 Mdl_Byte_01 8;
BA_ "CI_FullName" SG_ 2566843268 Make "Make";
BA_ "CI_ParId" SG_ 2566843268 Make "ESMD_02671";
BA_ "CI_SLOT_Name" SG_ 2566843268 Make "SAEatad0005";
BA_ "SPN" SG_ 2566843268 Make 586;
BA_ "CI_FullName" SG_ 2566843268 Mdl "Model";
BA_ "CI_ParId" SG_ 2566843268 Mdl "ESMD_02715";
BA_ "CI_SLOT_Name" SG_ 2566843268 Mdl "SAEatad0200";
BA_ "SPN" SG_ 2566843268 Mdl 587;
BA_ "GenSigAutoGenSnd" SG_ 2564487556 SepTime 0;
BA_ "GenSigAutoGenDsp" SG_ 2564487556 SepTime 0;
BA_ "CI_RepetitionComplemented" SG_ 2564487556 SepTime 2;
BA_ "CI_FullName" SG_ 2564487556 SepTime "Separation Time";
BA_ "CI_ParId" SG_ 2564487556 SepTime "ESMD_03113";
BA_ "GenSigAutoGenSnd" SG_ 2564487556 SingFrameDataLen 0;
BA_ "GenSigAutoGenDsp" SG_ 2564487556 SingFrameDataLen 0;
BA_ "CI_RepetitionComplemented" SG_ 2564487556 SingFrameDataLen 2;
BA_ "CI_FullName" SG_ 2564487556 SingFrameDataLen "Single Frame Data Length";
BA_ "CI_ParId" SG_ 2564487556 SingFrameDataLen "ESMD_03135";
BA_ "GenSigAutoGenSnd" SG_ 2564487556 N1FrameDataLen 0;
BA_ "GenSigAutoGenDsp" SG_ 2564487556 N1FrameDataLen 0;
BA_ "CI_RepetitionComplemented" SG_ 2564487556 N1FrameDataLen 2;
BA_ "CI_FullName" SG_ 2564487556 N1FrameDataLen "First Frame Data Length";
BA_ "CI_ParId" SG_ 2564487556 N1FrameDataLen "ESMD_01962";
BA_ "GenSigAutoGenSnd" SG_ 2564487556 BlkSize 0;
BA_ "GenSigAutoGenDsp" SG_ 2564487556 BlkSize 0;
BA_ "CI_RepetitionComplemented" SG_ 2564487556 BlkSize 2;
BA_ "CI_FullName" SG_ 2564487556 BlkSize "Block Size";
BA_ "CI_ParId" SG_ 2564487556 BlkSize "ESMD_00809";
BA_ "GenSigAutoGenSnd" SG_ 2564487556 FlowSts 0;
BA_ "GenSigAutoGenDsp" SG_ 2564487556 FlowSts 0;
BA_ "CI_RepetitionComplemented" SG_ 2564487556 FlowSts 2;
BA_ "CI_FullName" SG_ 2564487556 FlowSts "Flow Status";
BA_ "CI_ParId" SG_ 2564487556 FlowSts "ESMD_01968";
BA_ "GenSigAutoGenSnd" SG_ 2564487556 SN 0;
BA_ "GenSigAutoGenDsp" SG_ 2564487556 SN 0;
BA_ "CI_RepetitionComplemented" SG_ 2564487556 SN 2;
BA_ "CI_FullName" SG_ 2564487556 SN "Serial Number";
BA_ "CI_ParId" SG_ 2564487556 SN "ESMD_03138";
BA_ "GenSigAutoGenSnd" SG_ 2564487556 ProtocCntrlInfo 0;
BA_ "GenSigAutoGenDsp" SG_ 2564487556 ProtocCntrlInfo 0;
BA_ "CI_RepetitionComplemented" SG_ 2564487556 ProtocCntrlInfo 2;
BA_ "CI_FullName" SG_ 2564487556 ProtocCntrlInfo "Protocol Control Information";
BA_ "CI_ParId" SG_ 2564487556 ProtocCntrlInfo "ESMD_02905";
BA_ "GenSigAutoGenSnd" SG_ 2564457465 BlkSize 0;
BA_ "GenSigAutoGenDsp" SG_ 2564457465 BlkSize 0;
BA_ "CI_RepetitionComplemented" SG_ 2564457465 BlkSize 2;
BA_ "CI_FullName" SG_ 2564457465 BlkSize "Block Size";
BA_ "CI_ParId" SG_ 2564457465 BlkSize "ESMD_00809";
BA_ "GenSigAutoGenSnd" SG_ 2564457465 FlowSts 0;
BA_ "GenSigAutoGenDsp" SG_ 2564457465 FlowSts 0;
BA_ "CI_RepetitionComplemented" SG_ 2564457465 FlowSts 2;
BA_ "CI_FullName" SG_ 2564457465 FlowSts "Flow Status";
BA_ "CI_ParId" SG_ 2564457465 FlowSts "ESMD_01968";
BA_ "GenSigAutoGenSnd" SG_ 2564457465 N1FrameDataLen 0;
BA_ "GenSigAutoGenDsp" SG_ 2564457465 N1FrameDataLen 0;
BA_ "CI_RepetitionComplemented" SG_ 2564457465 N1FrameDataLen 2;
BA_ "CI_FullName" SG_ 2564457465 N1FrameDataLen "First Frame Data Length";
BA_ "CI_ParId" SG_ 2564457465 N1FrameDataLen "ESMD_01962";
BA_ "GenSigAutoGenSnd" SG_ 2564457465 ProtocCntrlInfo 0;
BA_ "GenSigAutoGenDsp" SG_ 2564457465 ProtocCntrlInfo 0;
BA_ "CI_RepetitionComplemented" SG_ 2564457465 ProtocCntrlInfo 2;
BA_ "CI_FullName" SG_ 2564457465 ProtocCntrlInfo "Protocol Control Information";
BA_ "CI_ParId" SG_ 2564457465 ProtocCntrlInfo "ESMD_02905";
BA_ "GenSigAutoGenSnd" SG_ 2564457465 SepTime 0;
BA_ "GenSigAutoGenDsp" SG_ 2564457465 SepTime 0;
BA_ "CI_RepetitionComplemented" SG_ 2564457465 SepTime 2;
BA_ "CI_FullName" SG_ 2564457465 SepTime "Separation Time";
BA_ "CI_ParId" SG_ 2564457465 SepTime "ESMD_03113";
BA_ "GenSigAutoGenSnd" SG_ 2564457465 SingFrameDataLen 0;
BA_ "GenSigAutoGenDsp" SG_ 2564457465 SingFrameDataLen 0;
BA_ "CI_RepetitionComplemented" SG_ 2564457465 SingFrameDataLen 2;
BA_ "CI_FullName" SG_ 2564457465 SingFrameDataLen "Single Frame Data Length";
BA_ "CI_ParId" SG_ 2564457465 SingFrameDataLen "ESMD_03135";
BA_ "GenSigAutoGenSnd" SG_ 2564457465 SN 0;
BA_ "GenSigAutoGenDsp" SG_ 2564457465 SN 0;
BA_ "CI_RepetitionComplemented" SG_ 2564457465 SN 2;
BA_ "CI_FullName" SG_ 2564457465 SN "Serial Number";
BA_ "CI_ParId" SG_ 2564457465 SN "ESMD_03138";
BA_ "CI_FullName" SG_ 2566843267 UnitNumPwrUnit "Unit Number (Power Unit)";
BA_ "CI_ParId" SG_ 2566843267 UnitNumPwrUnit "ESMD_03702";
BA_ "CI_SLOT_Name" SG_ 2566843267 UnitNumPwrUnit "SAEatad0200";
BA_ "SPN" SG_ 2566843267 UnitNumPwrUnit 233;
BA_ "CI_FullName" SG_ 2566843267 SN_2_Byte_15 "Serial Number 2";
BA_ "CI_ParId" SG_ 2566843267 SN_2_Byte_15 "ESMD_03115";
BA_ "CI_SLOT_Name" SG_ 2566843267 SN_2_Byte_15 "SAEatad0200";
BA_ "SPN" SG_ 2566843267 SN_2_Byte_15 588;
BA_ "SigType" SG_ 2566843267 SN_2_Byte_15 8;
BA_ "CI_FullName" SG_ 2566843267 SN_2_Byte_14 "Serial Number 2";
BA_ "CI_ParId" SG_ 2566843267 SN_2_Byte_14 "ESMD_03115";
BA_ "CI_SLOT_Name" SG_ 2566843267 SN_2_Byte_14 "SAEatad0200";
BA_ "SPN" SG_ 2566843267 SN_2_Byte_14 588;
BA_ "SigType" SG_ 2566843267 SN_2_Byte_14 8;
BA_ "CI_FullName" SG_ 2566843267 SN_2_Byte_13 "Serial Number 2";
BA_ "CI_ParId" SG_ 2566843267 SN_2_Byte_13 "ESMD_03115";
BA_ "CI_SLOT_Name" SG_ 2566843267 SN_2_Byte_13 "SAEatad0200";
BA_ "SPN" SG_ 2566843267 SN_2_Byte_13 588;
BA_ "SigType" SG_ 2566843267 SN_2_Byte_13 8;
BA_ "CI_FullName" SG_ 2566843267 SN_2_Byte_12 "Serial Number 2";
BA_ "CI_ParId" SG_ 2566843267 SN_2_Byte_12 "ESMD_03115";
BA_ "CI_SLOT_Name" SG_ 2566843267 SN_2_Byte_12 "SAEatad0200";
BA_ "SPN" SG_ 2566843267 SN_2_Byte_12 588;
BA_ "SigType" SG_ 2566843267 SN_2_Byte_12 8;
BA_ "CI_FullName" SG_ 2566843267 SN_2_Byte_11 "Serial Number 2";
BA_ "CI_ParId" SG_ 2566843267 SN_2_Byte_11 "ESMD_03115";
BA_ "CI_SLOT_Name" SG_ 2566843267 SN_2_Byte_11 "SAEatad0200";
BA_ "SPN" SG_ 2566843267 SN_2_Byte_11 588;
BA_ "SigType" SG_ 2566843267 SN_2_Byte_11 8;
BA_ "CI_FullName" SG_ 2566843267 SN_2_Byte_10 "Serial Number 2";
BA_ "CI_ParId" SG_ 2566843267 SN_2_Byte_10 "ESMD_03115";
BA_ "CI_SLOT_Name" SG_ 2566843267 SN_2_Byte_10 "SAEatad0200";
BA_ "SPN" SG_ 2566843267 SN_2_Byte_10 588;
BA_ "SigType" SG_ 2566843267 SN_2_Byte_10 8;
BA_ "CI_FullName" SG_ 2566843267 SN_2_Byte_09 "Serial Number 2";
BA_ "CI_ParId" SG_ 2566843267 SN_2_Byte_09 "ESMD_03115";
BA_ "CI_SLOT_Name" SG_ 2566843267 SN_2_Byte_09 "SAEatad0200";
BA_ "SPN" SG_ 2566843267 SN_2_Byte_09 588;
BA_ "SigType" SG_ 2566843267 SN_2_Byte_09 8;
BA_ "CI_FullName" SG_ 2566843267 SN_2_Byte_08 "Serial Number 2";
BA_ "CI_ParId" SG_ 2566843267 SN_2_Byte_08 "ESMD_03115";
BA_ "CI_SLOT_Name" SG_ 2566843267 SN_2_Byte_08 "SAEatad0200";
BA_ "SPN" SG_ 2566843267 SN_2_Byte_08 588;
BA_ "SigType" SG_ 2566843267 SN_2_Byte_08 8;
BA_ "CI_FullName" SG_ 2566843267 SN_2_Byte_07 "Serial Number 2";
BA_ "CI_ParId" SG_ 2566843267 SN_2_Byte_07 "ESMD_03115";
BA_ "CI_SLOT_Name" SG_ 2566843267 SN_2_Byte_07 "SAEatad0200";
BA_ "SPN" SG_ 2566843267 SN_2_Byte_07 588;
BA_ "SigType" SG_ 2566843267 SN_2_Byte_07 8;
BA_ "CI_FullName" SG_ 2566843267 SN_2_Byte_06 "Serial Number 2";
BA_ "CI_ParId" SG_ 2566843267 SN_2_Byte_06 "ESMD_03115";
BA_ "CI_SLOT_Name" SG_ 2566843267 SN_2_Byte_06 "SAEatad0200";
BA_ "SPN" SG_ 2566843267 SN_2_Byte_06 588;
BA_ "SigType" SG_ 2566843267 SN_2_Byte_06 8;
BA_ "CI_FullName" SG_ 2566843267 SN_2_Byte_05 "Serial Number 2";
BA_ "CI_ParId" SG_ 2566843267 SN_2_Byte_05 "ESMD_03115";
BA_ "CI_SLOT_Name" SG_ 2566843267 SN_2_Byte_05 "SAEatad0200";
BA_ "SPN" SG_ 2566843267 SN_2_Byte_05 588;
BA_ "SigType" SG_ 2566843267 SN_2_Byte_05 8;
BA_ "CI_FullName" SG_ 2566843267 SN_2_Byte_04 "Serial Number 2";
BA_ "CI_ParId" SG_ 2566843267 SN_2_Byte_04 "ESMD_03115";
BA_ "CI_SLOT_Name" SG_ 2566843267 SN_2_Byte_04 "SAEatad0200";
BA_ "SPN" SG_ 2566843267 SN_2_Byte_04 588;
BA_ "SigType" SG_ 2566843267 SN_2_Byte_04 8;
BA_ "CI_FullName" SG_ 2566843267 SN_2_Byte_03 "Serial Number 2";
BA_ "CI_ParId" SG_ 2566843267 SN_2_Byte_03 "ESMD_03115";
BA_ "CI_SLOT_Name" SG_ 2566843267 SN_2_Byte_03 "SAEatad0200";
BA_ "SPN" SG_ 2566843267 SN_2_Byte_03 588;
BA_ "SigType" SG_ 2566843267 SN_2_Byte_03 8;
BA_ "CI_FullName" SG_ 2566843267 SN_2_Byte_02 "Serial Number 2";
BA_ "CI_ParId" SG_ 2566843267 SN_2_Byte_02 "ESMD_03115";
BA_ "CI_SLOT_Name" SG_ 2566843267 SN_2_Byte_02 "SAEatad0200";
BA_ "SPN" SG_ 2566843267 SN_2_Byte_02 588;
BA_ "SigType" SG_ 2566843267 SN_2_Byte_02 8;
BA_ "CI_FullName" SG_ 2566843267 SN_2_Byte_01 "Serial Number 2";
BA_ "CI_ParId" SG_ 2566843267 SN_2_Byte_01 "ESMD_03115";
BA_ "CI_SLOT_Name" SG_ 2566843267 SN_2_Byte_01 "SAEatad0200";
BA_ "SPN" SG_ 2566843267 SN_2_Byte_01 588;
BA_ "SigType" SG_ 2566843267 SN_2_Byte_01 8;
BA_ "CI_FullName" SG_ 2566843267 SN_2 "Serial Number 2";
BA_ "CI_ParId" SG_ 2566843267 SN_2 "ESMD_03115";
BA_ "CI_SLOT_Name" SG_ 2566843267 SN_2 "SAEatad0200";
BA_ "SPN" SG_ 2566843267 SN_2 588;
BA_ "CI_FullName" SG_ 2566843267 Mdl_Byte_08 "Model";
BA_ "CI_ParId" SG_ 2566843267 Mdl_Byte_08 "ESMD_02715";
BA_ "CI_SLOT_Name" SG_ 2566843267 Mdl_Byte_08 "SAEatad0200";
BA_ "SPN" SG_ 2566843267 Mdl_Byte_08 587;
BA_ "SigType" SG_ 2566843267 Mdl_Byte_08 8;
BA_ "CI_FullName" SG_ 2566843267 Mdl_Byte_07 "Model";
BA_ "CI_ParId" SG_ 2566843267 Mdl_Byte_07 "ESMD_02715";
BA_ "CI_SLOT_Name" SG_ 2566843267 Mdl_Byte_07 "SAEatad0200";
BA_ "SPN" SG_ 2566843267 Mdl_Byte_07 587;
BA_ "SigType" SG_ 2566843267 Mdl_Byte_07 8;
BA_ "CI_FullName" SG_ 2566843267 Mdl_Byte_06 "Model";
BA_ "CI_ParId" SG_ 2566843267 Mdl_Byte_06 "ESMD_02715";
BA_ "CI_SLOT_Name" SG_ 2566843267 Mdl_Byte_06 "SAEatad0200";
BA_ "SPN" SG_ 2566843267 Mdl_Byte_06 587;
BA_ "SigType" SG_ 2566843267 Mdl_Byte_06 8;
BA_ "CI_FullName" SG_ 2566843267 Mdl_Byte_05 "Model";
BA_ "CI_ParId" SG_ 2566843267 Mdl_Byte_05 "ESMD_02715";
BA_ "CI_SLOT_Name" SG_ 2566843267 Mdl_Byte_05 "SAEatad0200";
BA_ "SPN" SG_ 2566843267 Mdl_Byte_05 587;
BA_ "SigType" SG_ 2566843267 Mdl_Byte_05 8;
BA_ "CI_FullName" SG_ 2566843267 Mdl_Byte_04 "Model";
BA_ "CI_ParId" SG_ 2566843267 Mdl_Byte_04 "ESMD_02715";
BA_ "CI_SLOT_Name" SG_ 2566843267 Mdl_Byte_04 "SAEatad0200";
BA_ "SPN" SG_ 2566843267 Mdl_Byte_04 587;
BA_ "SigType" SG_ 2566843267 Mdl_Byte_04 8;
BA_ "CI_FullName" SG_ 2566843267 Mdl_Byte_03 "Model";
BA_ "CI_ParId" SG_ 2566843267 Mdl_Byte_03 "ESMD_02715";
BA_ "CI_SLOT_Name" SG_ 2566843267 Mdl_Byte_03 "SAEatad0200";
BA_ "SPN" SG_ 2566843267 Mdl_Byte_03 587;
BA_ "SigType" SG_ 2566843267 Mdl_Byte_03 8;
BA_ "CI_FullName" SG_ 2566843267 Mdl_Byte_02 "Model";
BA_ "CI_ParId" SG_ 2566843267 Mdl_Byte_02 "ESMD_02715";
BA_ "CI_SLOT_Name" SG_ 2566843267 Mdl_Byte_02 "SAEatad0200";
BA_ "SPN" SG_ 2566843267 Mdl_Byte_02 587;
BA_ "SigType" SG_ 2566843267 Mdl_Byte_02 8;
BA_ "CI_FullName" SG_ 2566843267 Mdl_Byte_01 "Model";
BA_ "CI_ParId" SG_ 2566843267 Mdl_Byte_01 "ESMD_02715";
BA_ "CI_SLOT_Name" SG_ 2566843267 Mdl_Byte_01 "SAEatad0200";
BA_ "SPN" SG_ 2566843267 Mdl_Byte_01 587;
BA_ "SigType" SG_ 2566843267 Mdl_Byte_01 8;
BA_ "CI_FullName" SG_ 2566843267 Make "Make";
BA_ "CI_ParId" SG_ 2566843267 Make "ESMD_02671";
BA_ "CI_SLOT_Name" SG_ 2566843267 Make "SAEatad0005";
BA_ "SPN" SG_ 2566843267 Make 586;
BA_ "CI_FullName" SG_ 2566843267 Mdl "Model";
BA_ "CI_ParId" SG_ 2566843267 Mdl "ESMD_02715";
BA_ "CI_SLOT_Name" SG_ 2566843267 Mdl "SAEatad0200";
BA_ "SPN" SG_ 2566843267 Mdl 587;
BA_ "GenSigAutoGenSnd" SG_ 2564487555 SepTime 0;
BA_ "GenSigAutoGenDsp" SG_ 2564487555 SepTime 0;
BA_ "CI_RepetitionComplemented" SG_ 2564487555 SepTime 2;
BA_ "CI_FullName" SG_ 2564487555 SepTime "Separation Time";
BA_ "CI_ParId" SG_ 2564487555 SepTime "ESMD_03113";
BA_ "GenSigAutoGenSnd" SG_ 2564487555 SingFrameDataLen 0;
BA_ "GenSigAutoGenDsp" SG_ 2564487555 SingFrameDataLen 0;
BA_ "CI_RepetitionComplemented" SG_ 2564487555 SingFrameDataLen 2;
BA_ "CI_FullName" SG_ 2564487555 SingFrameDataLen "Single Frame Data Length";
BA_ "CI_ParId" SG_ 2564487555 SingFrameDataLen "ESMD_03135";
BA_ "GenSigAutoGenSnd" SG_ 2564487555 N1FrameDataLen 0;
BA_ "GenSigAutoGenDsp" SG_ 2564487555 N1FrameDataLen 0;
BA_ "CI_RepetitionComplemented" SG_ 2564487555 N1FrameDataLen 2;
BA_ "CI_FullName" SG_ 2564487555 N1FrameDataLen "First Frame Data Length";
BA_ "CI_ParId" SG_ 2564487555 N1FrameDataLen "ESMD_01962";
BA_ "GenSigAutoGenSnd" SG_ 2564487555 BlkSize 0;
BA_ "GenSigAutoGenDsp" SG_ 2564487555 BlkSize 0;
BA_ "CI_RepetitionComplemented" SG_ 2564487555 BlkSize 2;
BA_ "CI_FullName" SG_ 2564487555 BlkSize "Block Size";
BA_ "CI_ParId" SG_ 2564487555 BlkSize "ESMD_00809";
BA_ "GenSigAutoGenSnd" SG_ 2564487555 FlowSts 0;
BA_ "GenSigAutoGenDsp" SG_ 2564487555 FlowSts 0;
BA_ "CI_RepetitionComplemented" SG_ 2564487555 FlowSts 2;
BA_ "CI_FullName" SG_ 2564487555 FlowSts "Flow Status";
BA_ "CI_ParId" SG_ 2564487555 FlowSts "ESMD_01968";
BA_ "GenSigAutoGenSnd" SG_ 2564487555 SN 0;
BA_ "GenSigAutoGenDsp" SG_ 2564487555 SN 0;
BA_ "CI_RepetitionComplemented" SG_ 2564487555 SN 2;
BA_ "CI_FullName" SG_ 2564487555 SN "Serial Number";
BA_ "CI_ParId" SG_ 2564487555 SN "ESMD_03138";
BA_ "GenSigAutoGenSnd" SG_ 2564487555 ProtocCntrlInfo 0;
BA_ "GenSigAutoGenDsp" SG_ 2564487555 ProtocCntrlInfo 0;
BA_ "CI_RepetitionComplemented" SG_ 2564487555 ProtocCntrlInfo 2;
BA_ "CI_FullName" SG_ 2564487555 ProtocCntrlInfo "Protocol Control Information";
BA_ "CI_ParId" SG_ 2564487555 ProtocCntrlInfo "ESMD_02905";
BA_ "GenSigAutoGenSnd" SG_ 2564457209 BlkSize 0;
BA_ "GenSigAutoGenDsp" SG_ 2564457209 BlkSize 0;
BA_ "CI_RepetitionComplemented" SG_ 2564457209 BlkSize 2;
BA_ "CI_FullName" SG_ 2564457209 BlkSize "Block Size";
BA_ "CI_ParId" SG_ 2564457209 BlkSize "ESMD_00809";
BA_ "GenSigAutoGenSnd" SG_ 2564457209 FlowSts 0;
BA_ "GenSigAutoGenDsp" SG_ 2564457209 FlowSts 0;
BA_ "CI_RepetitionComplemented" SG_ 2564457209 FlowSts 2;
BA_ "CI_FullName" SG_ 2564457209 FlowSts "Flow Status";
BA_ "CI_ParId" SG_ 2564457209 FlowSts "ESMD_01968";
BA_ "GenSigAutoGenSnd" SG_ 2564457209 N1FrameDataLen 0;
BA_ "GenSigAutoGenDsp" SG_ 2564457209 N1FrameDataLen 0;
BA_ "CI_RepetitionComplemented" SG_ 2564457209 N1FrameDataLen 2;
BA_ "CI_FullName" SG_ 2564457209 N1FrameDataLen "First Frame Data Length";
BA_ "CI_ParId" SG_ 2564457209 N1FrameDataLen "ESMD_01962";
BA_ "GenSigAutoGenSnd" SG_ 2564457209 ProtocCntrlInfo 0;
BA_ "GenSigAutoGenDsp" SG_ 2564457209 ProtocCntrlInfo 0;
BA_ "CI_RepetitionComplemented" SG_ 2564457209 ProtocCntrlInfo 2;
BA_ "CI_FullName" SG_ 2564457209 ProtocCntrlInfo "Protocol Control Information";
BA_ "CI_ParId" SG_ 2564457209 ProtocCntrlInfo "ESMD_02905";
BA_ "GenSigAutoGenSnd" SG_ 2564457209 SepTime 0;
BA_ "GenSigAutoGenDsp" SG_ 2564457209 SepTime 0;
BA_ "CI_RepetitionComplemented" SG_ 2564457209 SepTime 2;
BA_ "CI_FullName" SG_ 2564457209 SepTime "Separation Time";
BA_ "CI_ParId" SG_ 2564457209 SepTime "ESMD_03113";
BA_ "GenSigAutoGenSnd" SG_ 2564457209 SingFrameDataLen 0;
BA_ "GenSigAutoGenDsp" SG_ 2564457209 SingFrameDataLen 0;
BA_ "CI_RepetitionComplemented" SG_ 2564457209 SingFrameDataLen 2;
BA_ "CI_FullName" SG_ 2564457209 SingFrameDataLen "Single Frame Data Length";
BA_ "CI_ParId" SG_ 2564457209 SingFrameDataLen "ESMD_03135";
BA_ "GenSigAutoGenSnd" SG_ 2564457209 SN 0;
BA_ "GenSigAutoGenDsp" SG_ 2564457209 SN 0;
BA_ "CI_RepetitionComplemented" SG_ 2564457209 SN 2;
BA_ "CI_FullName" SG_ 2564457209 SN "Serial Number";
BA_ "CI_ParId" SG_ 2564457209 SN "ESMD_03138";
BA_ "CI_FullName" SG_ 2566843266 UnitNumPwrUnit "Unit Number (Power Unit)";
BA_ "CI_ParId" SG_ 2566843266 UnitNumPwrUnit "ESMD_03702";
BA_ "CI_SLOT_Name" SG_ 2566843266 UnitNumPwrUnit "SAEatad0200";
BA_ "SPN" SG_ 2566843266 UnitNumPwrUnit 233;
BA_ "CI_FullName" SG_ 2566843266 SN_2_Byte_15 "Serial Number 2";
BA_ "CI_ParId" SG_ 2566843266 SN_2_Byte_15 "ESMD_03115";
BA_ "CI_SLOT_Name" SG_ 2566843266 SN_2_Byte_15 "SAEatad0200";
BA_ "SPN" SG_ 2566843266 SN_2_Byte_15 588;
BA_ "SigType" SG_ 2566843266 SN_2_Byte_15 8;
BA_ "CI_FullName" SG_ 2566843266 SN_2_Byte_14 "Serial Number 2";
BA_ "CI_ParId" SG_ 2566843266 SN_2_Byte_14 "ESMD_03115";
BA_ "CI_SLOT_Name" SG_ 2566843266 SN_2_Byte_14 "SAEatad0200";
BA_ "SPN" SG_ 2566843266 SN_2_Byte_14 588;
BA_ "SigType" SG_ 2566843266 SN_2_Byte_14 8;
BA_ "CI_FullName" SG_ 2566843266 SN_2_Byte_13 "Serial Number 2";
BA_ "CI_ParId" SG_ 2566843266 SN_2_Byte_13 "ESMD_03115";
BA_ "CI_SLOT_Name" SG_ 2566843266 SN_2_Byte_13 "SAEatad0200";
BA_ "SPN" SG_ 2566843266 SN_2_Byte_13 588;
BA_ "SigType" SG_ 2566843266 SN_2_Byte_13 8;
BA_ "CI_FullName" SG_ 2566843266 SN_2_Byte_12 "Serial Number 2";
BA_ "CI_ParId" SG_ 2566843266 SN_2_Byte_12 "ESMD_03115";
BA_ "CI_SLOT_Name" SG_ 2566843266 SN_2_Byte_12 "SAEatad0200";
BA_ "SPN" SG_ 2566843266 SN_2_Byte_12 588;
BA_ "SigType" SG_ 2566843266 SN_2_Byte_12 8;
BA_ "CI_FullName" SG_ 2566843266 SN_2_Byte_11 "Serial Number 2";
BA_ "CI_ParId" SG_ 2566843266 SN_2_Byte_11 "ESMD_03115";
BA_ "CI_SLOT_Name" SG_ 2566843266 SN_2_Byte_11 "SAEatad0200";
BA_ "SPN" SG_ 2566843266 SN_2_Byte_11 588;
BA_ "SigType" SG_ 2566843266 SN_2_Byte_11 8;
BA_ "CI_FullName" SG_ 2566843266 SN_2_Byte_10 "Serial Number 2";
BA_ "CI_ParId" SG_ 2566843266 SN_2_Byte_10 "ESMD_03115";
BA_ "CI_SLOT_Name" SG_ 2566843266 SN_2_Byte_10 "SAEatad0200";
BA_ "SPN" SG_ 2566843266 SN_2_Byte_10 588;
BA_ "SigType" SG_ 2566843266 SN_2_Byte_10 8;
BA_ "CI_FullName" SG_ 2566843266 SN_2_Byte_09 "Serial Number 2";
BA_ "CI_ParId" SG_ 2566843266 SN_2_Byte_09 "ESMD_03115";
BA_ "CI_SLOT_Name" SG_ 2566843266 SN_2_Byte_09 "SAEatad0200";
BA_ "SPN" SG_ 2566843266 SN_2_Byte_09 588;
BA_ "SigType" SG_ 2566843266 SN_2_Byte_09 8;
BA_ "CI_FullName" SG_ 2566843266 SN_2_Byte_08 "Serial Number 2";
BA_ "CI_ParId" SG_ 2566843266 SN_2_Byte_08 "ESMD_03115";
BA_ "CI_SLOT_Name" SG_ 2566843266 SN_2_Byte_08 "SAEatad0200";
BA_ "SPN" SG_ 2566843266 SN_2_Byte_08 588;
BA_ "SigType" SG_ 2566843266 SN_2_Byte_08 8;
BA_ "CI_FullName" SG_ 2566843266 SN_2_Byte_07 "Serial Number 2";
BA_ "CI_ParId" SG_ 2566843266 SN_2_Byte_07 "ESMD_03115";
BA_ "CI_SLOT_Name" SG_ 2566843266 SN_2_Byte_07 "SAEatad0200";
BA_ "SPN" SG_ 2566843266 SN_2_Byte_07 588;
BA_ "SigType" SG_ 2566843266 SN_2_Byte_07 8;
BA_ "CI_FullName" SG_ 2566843266 SN_2_Byte_06 "Serial Number 2";
BA_ "CI_ParId" SG_ 2566843266 SN_2_Byte_06 "ESMD_03115";
BA_ "CI_SLOT_Name" SG_ 2566843266 SN_2_Byte_06 "SAEatad0200";
BA_ "SPN" SG_ 2566843266 SN_2_Byte_06 588;
BA_ "SigType" SG_ 2566843266 SN_2_Byte_06 8;
BA_ "CI_FullName" SG_ 2566843266 SN_2_Byte_05 "Serial Number 2";
BA_ "CI_ParId" SG_ 2566843266 SN_2_Byte_05 "ESMD_03115";
BA_ "CI_SLOT_Name" SG_ 2566843266 SN_2_Byte_05 "SAEatad0200";
BA_ "SPN" SG_ 2566843266 SN_2_Byte_05 588;
BA_ "SigType" SG_ 2566843266 SN_2_Byte_05 8;
BA_ "CI_FullName" SG_ 2566843266 SN_2_Byte_04 "Serial Number 2";
BA_ "CI_ParId" SG_ 2566843266 SN_2_Byte_04 "ESMD_03115";
BA_ "CI_SLOT_Name" SG_ 2566843266 SN_2_Byte_04 "SAEatad0200";
BA_ "SPN" SG_ 2566843266 SN_2_Byte_04 588;
BA_ "SigType" SG_ 2566843266 SN_2_Byte_04 8;
BA_ "CI_FullName" SG_ 2566843266 SN_2_Byte_03 "Serial Number 2";
BA_ "CI_ParId" SG_ 2566843266 SN_2_Byte_03 "ESMD_03115";
BA_ "CI_SLOT_Name" SG_ 2566843266 SN_2_Byte_03 "SAEatad0200";
BA_ "SPN" SG_ 2566843266 SN_2_Byte_03 588;
BA_ "SigType" SG_ 2566843266 SN_2_Byte_03 8;
BA_ "CI_FullName" SG_ 2566843266 SN_2_Byte_02 "Serial Number 2";
BA_ "CI_ParId" SG_ 2566843266 SN_2_Byte_02 "ESMD_03115";
BA_ "CI_SLOT_Name" SG_ 2566843266 SN_2_Byte_02 "SAEatad0200";
BA_ "SPN" SG_ 2566843266 SN_2_Byte_02 588;
BA_ "SigType" SG_ 2566843266 SN_2_Byte_02 8;
BA_ "CI_FullName" SG_ 2566843266 SN_2_Byte_01 "Serial Number 2";
BA_ "CI_ParId" SG_ 2566843266 SN_2_Byte_01 "ESMD_03115";
BA_ "CI_SLOT_Name" SG_ 2566843266 SN_2_Byte_01 "SAEatad0200";
BA_ "SPN" SG_ 2566843266 SN_2_Byte_01 588;
BA_ "SigType" SG_ 2566843266 SN_2_Byte_01 8;
BA_ "CI_FullName" SG_ 2566843266 SN_2 "Serial Number 2";
BA_ "CI_ParId" SG_ 2566843266 SN_2 "ESMD_03115";
BA_ "CI_SLOT_Name" SG_ 2566843266 SN_2 "SAEatad0200";
BA_ "SPN" SG_ 2566843266 SN_2 588;
BA_ "CI_FullName" SG_ 2566843266 Mdl_Byte_08 "Model";
BA_ "CI_ParId" SG_ 2566843266 Mdl_Byte_08 "ESMD_02715";
BA_ "CI_SLOT_Name" SG_ 2566843266 Mdl_Byte_08 "SAEatad0200";
BA_ "SPN" SG_ 2566843266 Mdl_Byte_08 587;
BA_ "SigType" SG_ 2566843266 Mdl_Byte_08 8;
BA_ "CI_FullName" SG_ 2566843266 Mdl_Byte_07 "Model";
BA_ "CI_ParId" SG_ 2566843266 Mdl_Byte_07 "ESMD_02715";
BA_ "CI_SLOT_Name" SG_ 2566843266 Mdl_Byte_07 "SAEatad0200";
BA_ "SPN" SG_ 2566843266 Mdl_Byte_07 587;
BA_ "SigType" SG_ 2566843266 Mdl_Byte_07 8;
BA_ "CI_FullName" SG_ 2566843266 Mdl_Byte_06 "Model";
BA_ "CI_ParId" SG_ 2566843266 Mdl_Byte_06 "ESMD_02715";
BA_ "CI_SLOT_Name" SG_ 2566843266 Mdl_Byte_06 "SAEatad0200";
BA_ "SPN" SG_ 2566843266 Mdl_Byte_06 587;
BA_ "SigType" SG_ 2566843266 Mdl_Byte_06 8;
BA_ "CI_FullName" SG_ 2566843266 Mdl_Byte_05 "Model";
BA_ "CI_ParId" SG_ 2566843266 Mdl_Byte_05 "ESMD_02715";
BA_ "CI_SLOT_Name" SG_ 2566843266 Mdl_Byte_05 "SAEatad0200";
BA_ "SPN" SG_ 2566843266 Mdl_Byte_05 587;
BA_ "SigType" SG_ 2566843266 Mdl_Byte_05 8;
BA_ "CI_FullName" SG_ 2566843266 Mdl_Byte_04 "Model";
BA_ "CI_ParId" SG_ 2566843266 Mdl_Byte_04 "ESMD_02715";
BA_ "CI_SLOT_Name" SG_ 2566843266 Mdl_Byte_04 "SAEatad0200";
BA_ "SPN" SG_ 2566843266 Mdl_Byte_04 587;
BA_ "SigType" SG_ 2566843266 Mdl_Byte_04 8;
BA_ "CI_FullName" SG_ 2566843266 Mdl_Byte_03 "Model";
BA_ "CI_ParId" SG_ 2566843266 Mdl_Byte_03 "ESMD_02715";
BA_ "CI_SLOT_Name" SG_ 2566843266 Mdl_Byte_03 "SAEatad0200";
BA_ "SPN" SG_ 2566843266 Mdl_Byte_03 587;
BA_ "SigType" SG_ 2566843266 Mdl_Byte_03 8;
BA_ "CI_FullName" SG_ 2566843266 Mdl_Byte_02 "Model";
BA_ "CI_ParId" SG_ 2566843266 Mdl_Byte_02 "ESMD_02715";
BA_ "CI_SLOT_Name" SG_ 2566843266 Mdl_Byte_02 "SAEatad0200";
BA_ "SPN" SG_ 2566843266 Mdl_Byte_02 587;
BA_ "SigType" SG_ 2566843266 Mdl_Byte_02 8;
BA_ "CI_FullName" SG_ 2566843266 Mdl_Byte_01 "Model";
BA_ "CI_ParId" SG_ 2566843266 Mdl_Byte_01 "ESMD_02715";
BA_ "CI_SLOT_Name" SG_ 2566843266 Mdl_Byte_01 "SAEatad0200";
BA_ "SPN" SG_ 2566843266 Mdl_Byte_01 587;
BA_ "SigType" SG_ 2566843266 Mdl_Byte_01 8;
BA_ "CI_FullName" SG_ 2566843266 Make "Make";
BA_ "CI_ParId" SG_ 2566843266 Make "ESMD_02671";
BA_ "CI_SLOT_Name" SG_ 2566843266 Make "SAEatad0005";
BA_ "SPN" SG_ 2566843266 Make 586;
BA_ "CI_FullName" SG_ 2566843266 Mdl "Model";
BA_ "CI_ParId" SG_ 2566843266 Mdl "ESMD_02715";
BA_ "CI_SLOT_Name" SG_ 2566843266 Mdl "SAEatad0200";
BA_ "SPN" SG_ 2566843266 Mdl 587;
BA_ "GenSigAutoGenSnd" SG_ 2564487554 SepTime 0;
BA_ "GenSigAutoGenDsp" SG_ 2564487554 SepTime 0;
BA_ "CI_RepetitionComplemented" SG_ 2564487554 SepTime 2;
BA_ "CI_FullName" SG_ 2564487554 SepTime "Separation Time";
BA_ "CI_ParId" SG_ 2564487554 SepTime "ESMD_03113";
BA_ "GenSigAutoGenSnd" SG_ 2564487554 SingFrameDataLen 0;
BA_ "GenSigAutoGenDsp" SG_ 2564487554 SingFrameDataLen 0;
BA_ "CI_RepetitionComplemented" SG_ 2564487554 SingFrameDataLen 2;
BA_ "CI_FullName" SG_ 2564487554 SingFrameDataLen "Single Frame Data Length";
BA_ "CI_ParId" SG_ 2564487554 SingFrameDataLen "ESMD_03135";
BA_ "GenSigAutoGenSnd" SG_ 2564487554 N1FrameDataLen 0;
BA_ "GenSigAutoGenDsp" SG_ 2564487554 N1FrameDataLen 0;
BA_ "CI_RepetitionComplemented" SG_ 2564487554 N1FrameDataLen 2;
BA_ "CI_FullName" SG_ 2564487554 N1FrameDataLen "First Frame Data Length";
BA_ "CI_ParId" SG_ 2564487554 N1FrameDataLen "ESMD_01962";
BA_ "GenSigAutoGenSnd" SG_ 2564487554 BlkSize 0;
BA_ "GenSigAutoGenDsp" SG_ 2564487554 BlkSize 0;
BA_ "CI_RepetitionComplemented" SG_ 2564487554 BlkSize 2;
BA_ "CI_FullName" SG_ 2564487554 BlkSize "Block Size";
BA_ "CI_ParId" SG_ 2564487554 BlkSize "ESMD_00809";
BA_ "GenSigAutoGenSnd" SG_ 2564487554 FlowSts 0;
BA_ "GenSigAutoGenDsp" SG_ 2564487554 FlowSts 0;
BA_ "CI_RepetitionComplemented" SG_ 2564487554 FlowSts 2;
BA_ "CI_FullName" SG_ 2564487554 FlowSts "Flow Status";
BA_ "CI_ParId" SG_ 2564487554 FlowSts "ESMD_01968";
BA_ "GenSigAutoGenSnd" SG_ 2564487554 SN 0;
BA_ "GenSigAutoGenDsp" SG_ 2564487554 SN 0;
BA_ "CI_RepetitionComplemented" SG_ 2564487554 SN 2;
BA_ "CI_FullName" SG_ 2564487554 SN "Serial Number";
BA_ "CI_ParId" SG_ 2564487554 SN "ESMD_03138";
BA_ "GenSigAutoGenSnd" SG_ 2564487554 ProtocCntrlInfo 0;
BA_ "GenSigAutoGenDsp" SG_ 2564487554 ProtocCntrlInfo 0;
BA_ "CI_RepetitionComplemented" SG_ 2564487554 ProtocCntrlInfo 2;
BA_ "CI_FullName" SG_ 2564487554 ProtocCntrlInfo "Protocol Control Information";
BA_ "CI_ParId" SG_ 2564487554 ProtocCntrlInfo "ESMD_02905";
BA_ "GenSigAutoGenSnd" SG_ 2564456953 BlkSize 0;
BA_ "GenSigAutoGenDsp" SG_ 2564456953 BlkSize 0;
BA_ "CI_RepetitionComplemented" SG_ 2564456953 BlkSize 2;
BA_ "CI_FullName" SG_ 2564456953 BlkSize "Block Size";
BA_ "CI_ParId" SG_ 2564456953 BlkSize "ESMD_00809";
BA_ "GenSigAutoGenSnd" SG_ 2564456953 FlowSts 0;
BA_ "GenSigAutoGenDsp" SG_ 2564456953 FlowSts 0;
BA_ "CI_RepetitionComplemented" SG_ 2564456953 FlowSts 2;
BA_ "CI_FullName" SG_ 2564456953 FlowSts "Flow Status";
BA_ "CI_ParId" SG_ 2564456953 FlowSts "ESMD_01968";
BA_ "GenSigAutoGenSnd" SG_ 2564456953 N1FrameDataLen 0;
BA_ "GenSigAutoGenDsp" SG_ 2564456953 N1FrameDataLen 0;
BA_ "CI_RepetitionComplemented" SG_ 2564456953 N1FrameDataLen 2;
BA_ "CI_FullName" SG_ 2564456953 N1FrameDataLen "First Frame Data Length";
BA_ "CI_ParId" SG_ 2564456953 N1FrameDataLen "ESMD_01962";
BA_ "GenSigAutoGenSnd" SG_ 2564456953 ProtocCntrlInfo 0;
BA_ "GenSigAutoGenDsp" SG_ 2564456953 ProtocCntrlInfo 0;
BA_ "CI_RepetitionComplemented" SG_ 2564456953 ProtocCntrlInfo 2;
BA_ "CI_FullName" SG_ 2564456953 ProtocCntrlInfo "Protocol Control Information";
BA_ "CI_ParId" SG_ 2564456953 ProtocCntrlInfo "ESMD_02905";
BA_ "GenSigAutoGenSnd" SG_ 2564456953 SepTime 0;
BA_ "GenSigAutoGenDsp" SG_ 2564456953 SepTime 0;
BA_ "CI_RepetitionComplemented" SG_ 2564456953 SepTime 2;
BA_ "CI_FullName" SG_ 2564456953 SepTime "Separation Time";
BA_ "CI_ParId" SG_ 2564456953 SepTime "ESMD_03113";
BA_ "GenSigAutoGenSnd" SG_ 2564456953 SingFrameDataLen 0;
BA_ "GenSigAutoGenDsp" SG_ 2564456953 SingFrameDataLen 0;
BA_ "CI_RepetitionComplemented" SG_ 2564456953 SingFrameDataLen 2;
BA_ "CI_FullName" SG_ 2564456953 SingFrameDataLen "Single Frame Data Length";
BA_ "CI_ParId" SG_ 2564456953 SingFrameDataLen "ESMD_03135";
BA_ "GenSigAutoGenSnd" SG_ 2564456953 SN 0;
BA_ "GenSigAutoGenDsp" SG_ 2564456953 SN 0;
BA_ "CI_RepetitionComplemented" SG_ 2564456953 SN 2;
BA_ "CI_FullName" SG_ 2564456953 SN "Serial Number";
BA_ "CI_ParId" SG_ 2564456953 SN "ESMD_03138";
BA_ "CI_FullName" SG_ 2566845952 AT_1DPF_IntakPrsUseSPN "Aftertreatment 1 Diesel Particulate Filter Intake Pressure (use SPN 3609)";
BA_ "CI_ParId" SG_ 2566845952 AT_1DPF_IntakPrsUseSPN "ESMD_01421";
BA_ "CI_SLOT_Name" SG_ 2566845952 AT_1DPF_IntakPrsUseSPN "SAEpr05";
BA_ "SPN" SG_ 2566845952 AT_1DPF_IntakPrsUseSPN 81;
BA_ "CI_FullName" SG_ 2566845952 EngIntakManifld_1Prs "Engine Intake Manifold #1 Pressure";
BA_ "CI_ParId" SG_ 2566845952 EngIntakManifld_1Prs "ESMD_01641";
BA_ "CI_SLOT_Name" SG_ 2566845952 EngIntakManifld_1Prs "SAEpr07";
BA_ "SPN" SG_ 2566845952 EngIntakManifld_1Prs 102;
BA_ "SigType" SG_ 2566845952 EngIntakManifld_1Prs 1;
BA_ "CI_FullName" SG_ 2566845952 EngIntakManifld_1Temp "Engine Intake Manifold 1 Temperature";
BA_ "CI_ParId" SG_ 2566845952 EngIntakManifld_1Temp "ESMD_01642";
BA_ "CI_SLOT_Name" SG_ 2566845952 EngIntakManifld_1Temp "SAEtp01";
BA_ "SPN" SG_ 2566845952 EngIntakManifld_1Temp 105;
BA_ "SigType" SG_ 2566845952 EngIntakManifld_1Temp 1;
BA_ "CI_FullName" SG_ 2566845952 EngIntakAirPrs "Engine Intake Air Pressure";
BA_ "CI_ParId" SG_ 2566845952 EngIntakAirPrs "ESMD_01217";
BA_ "CI_SLOT_Name" SG_ 2566845952 EngIntakAirPrs "SAEpr07";
BA_ "SPN" SG_ 2566845952 EngIntakAirPrs 106;
BA_ "CI_FullName" SG_ 2566845952 EngAirFilt_1DiffPrs "Engine Air Filter 1 Differential Pressure";
BA_ "CI_ParId" SG_ 2566845952 EngAirFilt_1DiffPrs "ESMD_01211";
BA_ "CI_SLOT_Name" SG_ 2566845952 EngAirFilt_1DiffPrs "SAEpr02";
BA_ "SPN" SG_ 2566845952 EngAirFilt_1DiffPrs 107;
BA_ "CI_FullName" SG_ 2566845952 EngExhTemp "Engine Exhaust Temperature";
BA_ "CI_ParId" SG_ 2566845952 EngExhTemp "ESMD_01456";
BA_ "CI_SLOT_Name" SG_ 2566845952 EngExhTemp "SAEtp02";
BA_ "SPN" SG_ 2566845952 EngExhTemp 173;
BA_ "CI_FullName" SG_ 2566845952 EngCoolntFiltDiffPrs "Engine Coolant Filter Differential Pressure";
BA_ "CI_ParId" SG_ 2566845952 EngCoolntFiltDiffPrs "ESMD_01282";
BA_ "CI_SLOT_Name" SG_ 2566845952 EngCoolntFiltDiffPrs "SAEpr05";
BA_ "SPN" SG_ 2566845952 EngCoolntFiltDiffPrs 112;
BA_ "GenSigAutoGenSnd" SG_ 2364539904 EngTorqMode 0;
BA_ "GenSigAutoGenDsp" SG_ 2364539904 EngTorqMode 0;
BA_ "CI_RepetitionComplemented" SG_ 2364539904 EngTorqMode 2;
BA_ "CI_FullName" SG_ 2364539904 EngTorqMode "Engine Torque Mode";
BA_ "CI_ParId" SG_ 2364539904 EngTorqMode "ESMD_01836";
BA_ "CI_SLOT_Name" SG_ 2364539904 EngTorqMode "SAEbs04";
BA_ "SPN" SG_ 2364539904 EngTorqMode 899;
BA_ "GenSigAutoGenSnd" SG_ 2364539904 ActlEng_pcTorqFrac 0;
BA_ "GenSigAutoGenDsp" SG_ 2364539904 ActlEng_pcTorqFrac 0;
BA_ "CI_RepetitionComplemented" SG_ 2364539904 ActlEng_pcTorqFrac 2;
BA_ "CI_FullName" SG_ 2364539904 ActlEng_pcTorqFrac "Actual Engine - Percent Torque (Fractional)";
BA_ "CI_ParId" SG_ 2364539904 ActlEng_pcTorqFrac "ESMD_00030";
BA_ "CI_SLOT_Name" SG_ 2364539904 ActlEng_pcTorqFrac "SAEpc10";
BA_ "SPN" SG_ 2364539904 ActlEng_pcTorqFrac 4154;
BA_ "GenSigAutoGenSnd" SG_ 2364539904 DrivRqstEng_pcTorq 0;
BA_ "GenSigAutoGenDsp" SG_ 2364539904 DrivRqstEng_pcTorq 0;
BA_ "CI_RepetitionComplemented" SG_ 2364539904 DrivRqstEng_pcTorq 2;
BA_ "CI_FullName" SG_ 2364539904 DrivRqstEng_pcTorq "Drivers Demand Engine - Percent Torque";
BA_ "CI_ParId" SG_ 2364539904 DrivRqstEng_pcTorq "ESMD_01076";
BA_ "CI_SLOT_Name" SG_ 2364539904 DrivRqstEng_pcTorq "SAEpc05";
BA_ "SPN" SG_ 2364539904 DrivRqstEng_pcTorq 512;
BA_ "GenSigAutoGenSnd" SG_ 2364539904 ActlEng_pcTorq 0;
BA_ "GenSigAutoGenDsp" SG_ 2364539904 ActlEng_pcTorq 0;
BA_ "CI_RepetitionComplemented" SG_ 2364539904 ActlEng_pcTorq 2;
BA_ "CI_FullName" SG_ 2364539904 ActlEng_pcTorq "Actual Engine - Percent Torque";
BA_ "CI_ParId" SG_ 2364539904 ActlEng_pcTorq "ESMD_00034";
BA_ "CI_SLOT_Name" SG_ 2364539904 ActlEng_pcTorq "SAEpc05";
BA_ "SPN" SG_ 2364539904 ActlEng_pcTorq 513;
BA_ "SigType" SG_ 2364539904 ActlEng_pcTorq 1;
BA_ "GenSigAutoGenSnd" SG_ 2364539904 EngSpd 0;
BA_ "GenSigAutoGenDsp" SG_ 2364539904 EngSpd 0;
BA_ "CI_RepetitionComplemented" SG_ 2364539904 EngSpd 2;
BA_ "CI_FullName" SG_ 2364539904 EngSpd "Engine Speed";
BA_ "CI_ParId" SG_ 2364539904 EngSpd "ESMD_01792";
BA_ "CI_SLOT_Name" SG_ 2364539904 EngSpd "SAEvr01";
BA_ "SPN" SG_ 2364539904 EngSpd 190;
BA_ "GenSigAutoGenSnd" SG_ 2364539904 SA_CntrlDevEngCntrl 0;
BA_ "GenSigAutoGenDsp" SG_ 2364539904 SA_CntrlDevEngCntrl 0;
BA_ "CI_RepetitionComplemented" SG_ 2364539904 SA_CntrlDevEngCntrl 2;
BA_ "CI_FullName" SG_ 2364539904 SA_CntrlDevEngCntrl "Source Address of Controlling Device for Engine Control";
BA_ "CI_ParId" SG_ 2364539904 SA_CntrlDevEngCntrl "ESMD_03261";
BA_ "CI_SLOT_Name" SG_ 2364539904 SA_CntrlDevEngCntrl "SAEsa01";
BA_ "SPN" SG_ 2364539904 SA_CntrlDevEngCntrl 1483;
BA_ "GenSigAutoGenSnd" SG_ 2364539904 EngStartMode 0;
BA_ "GenSigAutoGenDsp" SG_ 2364539904 EngStartMode 0;
BA_ "CI_RepetitionComplemented" SG_ 2364539904 EngStartMode 2;
BA_ "CI_FullName" SG_ 2364539904 EngStartMode "Engine Starter Mode";
BA_ "CI_ParId" SG_ 2364539904 EngStartMode "ESMD_27910";
BA_ "CI_SLOT_Name" SG_ 2364539904 EngStartMode "SAEbs04";
BA_ "SPN" SG_ 2364539904 EngStartMode 1675;
BA_ "GenSigAutoGenSnd" SG_ 2364539904 EngRqst_pcTorq 0;
BA_ "GenSigAutoGenDsp" SG_ 2364539904 EngRqst_pcTorq 0;
BA_ "CI_RepetitionComplemented" SG_ 2364539904 EngRqst_pcTorq 2;
BA_ "CI_FullName" SG_ 2364539904 EngRqst_pcTorq "Engine Demand – Percent Torque";
BA_ "CI_ParId" SG_ 2364539904 EngRqst_pcTorq "ESMD_01409";
BA_ "CI_SLOT_Name" SG_ 2364539904 EngRqst_pcTorq "SAEpc05";
BA_ "SPN" SG_ 2364539904 EngRqst_pcTorq 2432;
BA_ "CI_FullName" SG_ 2364539648 AccPed_1LoIdleSw "Accelerator Pedal 1 Low Idle Switch";
BA_ "CI_ParId" SG_ 2364539648 AccPed_1LoIdleSw "ESMD_00012";
BA_ "CI_SLOT_Name" SG_ 2364539648 AccPed_1LoIdleSw "SAEbs02";
BA_ "SPN" SG_ 2364539648 AccPed_1LoIdleSw 558;
BA_ "CI_FullName" SG_ 2364539648 AccPedKickdnSw "Accelerator Pedal Kickdown Switch";
BA_ "CI_ParId" SG_ 2364539648 AccPedKickdnSw "ESMD_00016";
BA_ "CI_SLOT_Name" SG_ 2364539648 AccPedKickdnSw "SAEbs02";
BA_ "SPN" SG_ 2364539648 AccPedKickdnSw 559;
BA_ "CI_FullName" SG_ 2364539648 RoadSpdLimSts "Road Speed Limit Status";
BA_ "CI_ParId" SG_ 2364539648 RoadSpdLimSts "ESMD_03047";
BA_ "CI_SLOT_Name" SG_ 2364539648 RoadSpdLimSts "SAEbs02";
BA_ "SPN" SG_ 2364539648 RoadSpdLimSts 1437;
BA_ "CI_FullName" SG_ 2364539648 AccPed_2LoIdleSw "Accelerator Pedal 2 Low Idle Switch";
BA_ "CI_ParId" SG_ 2364539648 AccPed_2LoIdleSw "ESMD_00015";
BA_ "CI_SLOT_Name" SG_ 2364539648 AccPed_2LoIdleSw "SAEbs02";
BA_ "SPN" SG_ 2364539648 AccPed_2LoIdleSw 2970;
BA_ "CI_FullName" SG_ 2364539648 AccPedPositn_1 "Accelerator Pedal Position 1";
BA_ "CI_ParId" SG_ 2364539648 AccPedPositn_1 "ESMD_00018";
BA_ "CI_SLOT_Name" SG_ 2364539648 AccPedPositn_1 "SAEpc03";
BA_ "SPN" SG_ 2364539648 AccPedPositn_1 91;
BA_ "SigType" SG_ 2364539648 AccPedPositn_1 1;
BA_ "CI_FullName" SG_ 2364539648 Eng_pcLoadCurrSpd "Engine Percent Load At Current Speed";
BA_ "CI_ParId" SG_ 2364539648 Eng_pcLoadCurrSpd "ESMD_01725";
BA_ "CI_SLOT_Name" SG_ 2364539648 Eng_pcLoadCurrSpd "SAEpc06";
BA_ "SPN" SG_ 2364539648 Eng_pcLoadCurrSpd 92;
BA_ "SigType" SG_ 2364539648 Eng_pcLoadCurrSpd 1;
BA_ "CI_FullName" SG_ 2364539648 RemotAccPedPositn "Remote Accelerator Pedal Position";
BA_ "CI_ParId" SG_ 2364539648 RemotAccPedPositn "ESMD_03001";
BA_ "CI_SLOT_Name" SG_ 2364539648 RemotAccPedPositn "SAEpc03";
BA_ "SPN" SG_ 2364539648 RemotAccPedPositn 974;
BA_ "CI_FullName" SG_ 2364539648 AccPedPositn_2 "Accelerator Pedal Position 2";
BA_ "CI_ParId" SG_ 2364539648 AccPedPositn_2 "ESMD_00019";
BA_ "CI_SLOT_Name" SG_ 2364539648 AccPedPositn_2 "SAEpc03";
BA_ "SPN" SG_ 2364539648 AccPedPositn_2 29;
BA_ "CI_FullName" SG_ 2364539648 VehAccelRateLimSts "Vehicle Acceleration Rate Limit Status";
BA_ "CI_ParId" SG_ 2364539648 VehAccelRateLimSts "ESMD_03791";
BA_ "CI_SLOT_Name" SG_ 2364539648 VehAccelRateLimSts "SAEbs02";
BA_ "SPN" SG_ 2364539648 VehAccelRateLimSts 2979;
BA_ "CI_FullName" SG_ 2364539648 MomentEngMaxPwrEnaFdbk "Momentary Engine Maximum Power Enable Feedback";
BA_ "CI_ParId" SG_ 2364539648 MomentEngMaxPwrEnaFdbk "ESMD_02710";
BA_ "CI_SLOT_Name" SG_ 2364539648 MomentEngMaxPwrEnaFdbk "SAEbs02";
BA_ "SPN" SG_ 2364539648 MomentEngMaxPwrEnaFdbk 5021;
BA_ "CI_FullName" SG_ 2364539648 DPF_ThermManageActv "DPF Thermal Management Active";
BA_ "CI_ParId" SG_ 2364539648 DPF_ThermManageActv "ESMD_01056";
BA_ "CI_SLOT_Name" SG_ 2364539648 DPF_ThermManageActv "SAEbs02";
BA_ "SPN" SG_ 2364539648 DPF_ThermManageActv 5399;
BA_ "CI_FullName" SG_ 2364539648 SCR_ThermManageActv "SCR Thermal Management Active";
BA_ "CI_ParId" SG_ 2364539648 SCR_ThermManageActv "ESMD_03076";
BA_ "CI_SLOT_Name" SG_ 2364539648 SCR_ThermManageActv "SAEbs02";
BA_ "SPN" SG_ 2364539648 SCR_ThermManageActv 5400;
BA_ "CI_FullName" SG_ 2364539648 ActlMaxAvEng_pcTorq "Actual Maximum Available Engine - Percent Torque";
BA_ "CI_ParId" SG_ 2364539648 ActlMaxAvEng_pcTorq "ESMD_00031";
BA_ "CI_SLOT_Name" SG_ 2364539648 ActlMaxAvEng_pcTorq "SAEpc03";
BA_ "SPN" SG_ 2364539648 ActlMaxAvEng_pcTorq 3357;
BA_ "SigType" SG_ 2364539648 ActlMaxAvEng_pcTorq 1;
BA_ "CI_FullName" SG_ 2364539648 EstPump_pcTorq "Estimated Pumping - Percent Torque";
BA_ "CI_ParId" SG_ 2364539648 EstPump_pcTorq "ESMD_01923";
BA_ "CI_SLOT_Name" SG_ 2364539648 EstPump_pcTorq "SAEpc05";
BA_ "SPN" SG_ 2364539648 EstPump_pcTorq 5398;
BA_ "CI_FullName" SG_ 2566843904 EngCoolntTemp "Engine Coolant Temperature";
BA_ "CI_ParId" SG_ 2566843904 EngCoolntTemp "ESMD_01292";
BA_ "CI_SLOT_Name" SG_ 2566843904 EngCoolntTemp "SAEtp01";
BA_ "SPN" SG_ 2566843904 EngCoolntTemp 110;
BA_ "CI_FullName" SG_ 2566843904 EngFuelTemp_1 "Engine Fuel 1 Temperature 1";
BA_ "CI_ParId" SG_ 2566843904 EngFuelTemp_1 "ESMD_01570";
BA_ "CI_SLOT_Name" SG_ 2566843904 EngFuelTemp_1 "SAEtp01";
BA_ "SPN" SG_ 2566843904 EngFuelTemp_1 174;
BA_ "CI_FullName" SG_ 2566843904 EngOilTemp_1 "Engine Oil Temperature 1";
BA_ "CI_ParId" SG_ 2566843904 EngOilTemp_1 "ESMD_01714";
BA_ "CI_SLOT_Name" SG_ 2566843904 EngOilTemp_1 "SAEtp02";
BA_ "SPN" SG_ 2566843904 EngOilTemp_1 175;
BA_ "CI_FullName" SG_ 2566843904 EngTcOilTemp "Engine Turbocharger Oil Temperature";
BA_ "CI_ParId" SG_ 2566843904 EngTcOilTemp "ESMD_01899";
BA_ "CI_SLOT_Name" SG_ 2566843904 EngTcOilTemp "SAEtp02";
BA_ "SPN" SG_ 2566843904 EngTcOilTemp 176;
BA_ "CI_FullName" SG_ 2566843904 EngIntercoolTemp "Engine Intercooler Temperature";
BA_ "CI_ParId" SG_ 2566843904 EngIntercoolTemp "ESMD_01652";
BA_ "CI_SLOT_Name" SG_ 2566843904 EngIntercoolTemp "SAEtp01";
BA_ "SPN" SG_ 2566843904 EngIntercoolTemp 52;
BA_ "CI_FullName" SG_ 2566843904 EngChrgAirCoolerThermOpen "Engine Charge Air Cooler Thermostat Opening";
BA_ "CI_ParId" SG_ 2566843904 EngChrgAirCoolerThermOpen "ESMD_01653";
BA_ "CI_SLOT_Name" SG_ 2566843904 EngChrgAirCoolerThermOpen "SAEpc03";
BA_ "SPN" SG_ 2566843904 EngChrgAirCoolerThermOpen 1134;
BA_ "GenSigAutoGenSnd" SG_ 2566841600 EngTotHourOp 0;
BA_ "GenSigAutoGenDsp" SG_ 2566841600 EngTotHourOp 0;
BA_ "CI_RepetitionComplemented" SG_ 2566841600 EngTotHourOp 2;
BA_ "CI_FullName" SG_ 2566841600 EngTotHourOp "Engine Total Hours of Operation";
BA_ "CI_ParId" SG_ 2566841600 EngTotHourOp "ESMD_01840";
BA_ "CI_SLOT_Name" SG_ 2566841600 EngTotHourOp "SAEtm09";
BA_ "SPN" SG_ 2566841600 EngTotHourOp 247;
BA_ "GenSigAutoGenSnd" SG_ 2566841600 EngTotRevol 0;
BA_ "GenSigAutoGenDsp" SG_ 2566841600 EngTotRevol 0;
BA_ "CI_RepetitionComplemented" SG_ 2566841600 EngTotRevol 2;
BA_ "CI_FullName" SG_ 2566841600 EngTotRevol "Engine Total Revolutions";
BA_ "CI_ParId" SG_ 2566841600 EngTotRevol "ESMD_01843";
BA_ "CI_SLOT_Name" SG_ 2566841600 EngTotRevol "SAErv01";
BA_ "SPN" SG_ 2566841600 EngTotRevol 249;
BA_ "SigType" SG_ 2566841600 EngTotRevol 1;
BA_ "CI_FullName" SG_ 2566846208 SLI_Batt_1NetCurr "SLI Net Battery 1 Current";
BA_ "CI_ParId" SG_ 2566846208 SLI_Batt_1NetCurr "ESMD_02730";
BA_ "CI_SLOT_Name" SG_ 2566846208 SLI_Batt_1NetCurr "SAEec02";
BA_ "SPN" SG_ 2566846208 SLI_Batt_1NetCurr 114;
BA_ "CI_FullName" SG_ 2566846208 AlternCurr "Alternator Current";
BA_ "CI_ParId" SG_ 2566846208 AlternCurr "ESMD_00551";
BA_ "CI_SLOT_Name" SG_ 2566846208 AlternCurr "SAEec03";
BA_ "SPN" SG_ 2566846208 AlternCurr 115;
BA_ "CI_FullName" SG_ 2566846208 ChargeSysPotentV "Charging System Potential (Voltage)";
BA_ "CI_ParId" SG_ 2566846208 ChargeSysPotentV "ESMD_00907";
BA_ "CI_SLOT_Name" SG_ 2566846208 ChargeSysPotentV "SAEev01";
BA_ "GenSigStartValue" SG_ 2566846208 ChargeSysPotentV 65535;
BA_ "SPN" SG_ 2566846208 ChargeSysPotentV 167;
BA_ "SigType" SG_ 2566846208 ChargeSysPotentV 1;
BA_ "CI_FullName" SG_ 2566846208 BattPotentPwrInput_1 "Battery Potential / Power Input 1";
BA_ "CI_ParId" SG_ 2566846208 BattPotentPwrInput_1 "ESMD_00778";
BA_ "CI_SLOT_Name" SG_ 2566846208 BattPotentPwrInput_1 "SAEev01";
BA_ "GenSigStartValue" SG_ 2566846208 BattPotentPwrInput_1 65535;
BA_ "SPN" SG_ 2566846208 BattPotentPwrInput_1 168;
BA_ "SigType" SG_ 2566846208 BattPotentPwrInput_1 1;
BA_ "CI_FullName" SG_ 2566846208 KeySwBattPotent "Keyswitch Battery Potential";
BA_ "CI_ParId" SG_ 2566846208 KeySwBattPotent "ESMD_02552";
BA_ "CI_SLOT_Name" SG_ 2566846208 KeySwBattPotent "SAEev01";
BA_ "SPN" SG_ 2566846208 KeySwBattPotent 158;
VAL_ 2564816674 SuspendSig 0 "IndefiniteSuspensionOfAllBroadcasts" 1 "IndefiniteSuspensionOfSomeMessages" 2 "TemporarySuspensionOfAllBroadcasts" 3 "TemporarySuspensionOfSomeMessages" 14 "ResumingNormalBroadcastPattern" 15 "NotAvailable" ;
VAL_ 2564816674 J1939_Net_1PriVehNet 0 "Stop broadcast" 1 "Start broadcast" 2 "Reserved" 3 "Don't care" ;
VAL_ 2564816674 J1922 0 "Stop broadcast" 1 "Start broadcast" 2 "Reserved" 3 "Don't care" ;
VAL_ 2564816674 J1587 0 "Stop broadcast" 1 "Start broadcast" 2 "Reserved" 3 "Don't care" ;
VAL_ 2564816674 CurrDataLnk 0 "Stop broadcast" 1 "Start broadcast" 2 "Reserved" 3 "Don't care" ;
VAL_ 2564816674 OthManufctSpecPort 0 "Stop broadcast" 1 "Start broadcast" 2 "Reserved" 3 "Don't care" ;
VAL_ 2564816674 J1850 0 "Stop broadcast" 1 "Start broadcast" 2 "Reserved" 3 "Don't care" ;
VAL_ 2564816674 ISO_9141 0 "Stop broadcast" 1 "Start broadcast" 2 "Reserved" 3 "Don't care" ;
VAL_ 2564816674 J1939_Net_2 0 "Stop broadcast" 1 "Start broadcast" 2 "Reserved" 3 "Don't care" ;
VAL_ 2564816674 J1939_Net_3 3 "Don't care" 0 "Stop broadcast" 1 "Start broadcast" 2 "Reserved" ;
VAL_ 2564816674 HoldSig 0 "All devices" 1 "Devices whose broadcast state ha" 15 "Not available" ;
VAL_ 2564816674 ProprNet_1 0 "Stop broadcast" 1 "Start broadcast" 2 "Reserved" 3 "Don't care" ;
VAL_ 2564816674 ProprNet_2 0 "Stop broadcast" 1 "Start broadcast" 2 "Reserved" 3 "Don't care" ;
VAL_ 2566865698 EHR_Err_21_22 1 "Fault message only" 0 "Valve is switched off" ;
VAL_ 2566865698 EHR_Err_23 1 "Fault message only" 0 "Valve is switched off" ;
VAL_ 2566865698 EHR_ParamByte_1 127 "EHR Parameter Status" 59 "EHR Parameter Control" ;
VAL_ 2566865698 EHR_ParamByte_2 244 "CheckStatus (for PTO uses)" 243 "PTO_Startup (for PTO uses)" 242 "ActivateSolenoids (for PTO uses)" 241 "ReleaseSolenoids (for PTO uses)" 103 "RoundingOfTheTimeRamp" 80 "ReadChecksumOfApplicationSw" 51 "SwOffFaultLedAllEHR-TecnordOnly" 50 "SwitchOffTheFaultLedForOneEHR" 49 "SwitchOnTheFaultLedForOneEHR" 21 "ChangeIndividualValveNumber" 19 "CustomerMode" 18 "ChnageAllValueNumerbs" ;
VAL_ 2566870050 EHR_FailSafe 0 "Neutral" 1 "Float" 2 "Reserved" 3 "Don't care" ;
VAL_ 2566870050 EHR_CntrlSts 0 "Block / Neutral" 1 "Extend" 2 "Retract" 3 "Float / open centre" 14 "Reserved" 15 "Don't care" ;
VAL_ 2566870050 EHR_EvTemp 255 "Error" ;
VAL_ 2566870050 EHR_EvFlow 255 "N/A" ;
VAL_ 2566870050 EHR_Op_2 2 "Reserved" 1 "Reserved" 0 "Goto Fialsafe" 3 "Normal Operation" ;
VAL_ 2566870050 EHR_Op_1 0 "Calibration active" 1 "Reserved" 2 "Error" 3 "Normal Operation" ;
VAL_ 2566870050 EHR_DynRmpTime 255 "N/A" ;
VAL_ 2566870050 EHR_CrvShp 0 "Curve Shape 0h" 1 "Curve Shape 1h" 2 "Curve Shape 2h" 3 "Curve Shape 3h" 4 "Curve Shape 4h" 5 "Curve Shape 5h" 6 "Curve Shape 6h" 7 "Curve Shape 7h" 8 "Curve Shape 8h" 9 "Curve Shape 9h" 10 "Curve Shape Ah" 11 "Curve Shape Bh" 12 "Curve Shape Ch" 13 "Curve Shape Dh" 14 "Curve Shape Eh" 15 "Curve Shape Fh" ;
VAL_ 2566870050 EHR_CrvGrad 255 "Error" ;
VAL_ 2566870050 EHR_Init 3 "Reserved" 2 "Reserved" 1 "Cranking" 0 "Operation" ;
VAL_ 2566871330 EHR_FailSafe 0 "Neutral" 1 "Float" 2 "Reserved" 3 "Don't care" ;
VAL_ 2566871330 EHR_CntrlSts 0 "Block / Neutral" 1 "Extend" 2 "Retract" 3 "Float / open centre" 14 "Reserved" 15 "Don't care" ;
VAL_ 2566871330 EHR_EvTemp 255 "Error" ;
VAL_ 2566871330 EHR_EvFlow 255 "N/A" ;
VAL_ 2566871330 EHR_Op_2 2 "Reserved" 1 "Reserved" 0 "Goto Fialsafe" 3 "Normal Operation" ;
VAL_ 2566871330 EHR_Op_1 0 "Calibration active" 1 "Reserved" 2 "Error" 3 "Normal Operation" ;
VAL_ 2566871330 EHR_DynRmpTime 255 "N/A" ;
VAL_ 2566871330 EHR_CrvShp 0 "Curve Shape 0h" 1 "Curve Shape 1h" 2 "Curve Shape 2h" 3 "Curve Shape 3h" 4 "Curve Shape 4h" 5 "Curve Shape 5h" 6 "Curve Shape 6h" 7 "Curve Shape 7h" 8 "Curve Shape 8h" 9 "Curve Shape 9h" 10 "Curve Shape Ah" 11 "Curve Shape Bh" 12 "Curve Shape Ch" 13 "Curve Shape Dh" 14 "Curve Shape Eh" 15 "Curve Shape Fh" ;
VAL_ 2566871330 EHR_CrvGrad 255 "Error" ;
VAL_ 2566871330 EHR_Init 3 "Reserved" 2 "Reserved" 1 "Cranking" 0 "Operation" ;
VAL_ 2566869794 EHR_FailSafe 0 "Neutral" 1 "Float" 2 "Reserved" 3 "Don't care" ;
VAL_ 2566869794 EHR_CntrlSts 0 "Block / Neutral" 1 "Extend" 2 "Retract" 3 "Float / open centre" 14 "Reserved" 15 "Don't care" ;
VAL_ 2566869794 EHR_EvTemp 255 "Error" ;
VAL_ 2566869794 EHR_EvFlow 255 "N/A" ;
VAL_ 2566869794 EHR_Op_2 2 "Reserved" 1 "Reserved" 0 "Goto Fialsafe" 3 "Normal Operation" ;
VAL_ 2566869794 EHR_Op_1 0 "Calibration active" 1 "Reserved" 2 "Error" 3 "Normal Operation" ;
VAL_ 2566869794 EHR_DynRmpTime 255 "N/A" ;
VAL_ 2566869794 EHR_CrvShp 0 "Curve Shape 0h" 1 "Curve Shape 1h" 2 "Curve Shape 2h" 3 "Curve Shape 3h" 4 "Curve Shape 4h" 5 "Curve Shape 5h" 6 "Curve Shape 6h" 7 "Curve Shape 7h" 8 "Curve Shape 8h" 9 "Curve Shape 9h" 10 "Curve Shape Ah" 11 "Curve Shape Bh" 12 "Curve Shape Ch" 13 "Curve Shape Dh" 14 "Curve Shape Eh" 15 "Curve Shape Fh" ;
VAL_ 2566869794 EHR_CrvGrad 255 "Error" ;
VAL_ 2566869794 EHR_Init 3 "Reserved" 2 "Reserved" 1 "Cranking" 0 "Operation" ;
VAL_ 2566869538 EHR_FailSafe 0 "Neutral" 1 "Float" 2 "Reserved" 3 "Don't care" ;
VAL_ 2566869538 EHR_CntrlSts 0 "Block / Neutral" 1 "Extend" 2 "Retract" 3 "Float / open centre" 14 "Reserved" 15 "Don't care" ;
VAL_ 2566869538 EHR_EvTemp 255 "Error" ;
VAL_ 2566869538 EHR_EvFlow 255 "N/A" ;
VAL_ 2566869538 EHR_Op_2 2 "Reserved" 1 "Reserved" 0 "Goto Fialsafe" 3 "Normal Operation" ;
VAL_ 2566869538 EHR_Op_1 0 "Calibration active" 1 "Reserved" 2 "Error" 3 "Normal Operation" ;
VAL_ 2566869538 EHR_DynRmpTime 255 "N/A" ;
VAL_ 2566869538 EHR_CrvShp 0 "Curve Shape 0h" 1 "Curve Shape 1h" 2 "Curve Shape 2h" 3 "Curve Shape 3h" 4 "Curve Shape 4h" 5 "Curve Shape 5h" 6 "Curve Shape 6h" 7 "Curve Shape 7h" 8 "Curve Shape 8h" 9 "Curve Shape 9h" 10 "Curve Shape Ah" 11 "Curve Shape Bh" 12 "Curve Shape Ch" 13 "Curve Shape Dh" 14 "Curve Shape Eh" 15 "Curve Shape Fh" ;
VAL_ 2566869538 EHR_CrvGrad 255 "Error" ;
VAL_ 2566869538 EHR_Init 3 "Reserved" 2 "Reserved" 1 "Cranking" 0 "Operation" ;
VAL_ 2566869282 EHR_FailSafe 0 "Neutral" 1 "Float" 2 "Reserved" 3 "Don't care" ;
VAL_ 2566869282 EHR_CntrlSts 0 "Block / Neutral" 1 "Extend" 2 "Retract" 3 "Float / open centre" 14 "Reserved" 15 "Don't care" ;
VAL_ 2566869282 EHR_EvTemp 255 "Error" ;
VAL_ 2566869282 EHR_EvFlow 255 "N/A" ;
VAL_ 2566869282 EHR_Op_2 2 "Reserved" 1 "Reserved" 0 "Goto Fialsafe" 3 "Normal Operation" ;
VAL_ 2566869282 EHR_Op_1 0 "Calibration active" 1 "Reserved" 2 "Error" 3 "Normal Operation" ;
VAL_ 2566869282 EHR_DynRmpTime 255 "N/A" ;
VAL_ 2566869282 EHR_CrvShp 0 "Curve Shape 0h" 1 "Curve Shape 1h" 2 "Curve Shape 2h" 3 "Curve Shape 3h" 4 "Curve Shape 4h" 5 "Curve Shape 5h" 6 "Curve Shape 6h" 7 "Curve Shape 7h" 8 "Curve Shape 8h" 9 "Curve Shape 9h" 10 "Curve Shape Ah" 11 "Curve Shape Bh" 12 "Curve Shape Ch" 13 "Curve Shape Dh" 14 "Curve Shape Eh" 15 "Curve Shape Fh" ;
VAL_ 2566869282 EHR_CrvGrad 255 "Error" ;
VAL_ 2566869282 EHR_Init 3 "Reserved" 2 "Reserved" 1 "Cranking" 0 "Operation" ;
VAL_ 2566869026 EHR_FailSafe 0 "Neutral" 1 "Float" 2 "Reserved" 3 "Don't care" ;
VAL_ 2566869026 EHR_CntrlSts 0 "Block / Neutral" 1 "Extend" 2 "Retract" 3 "Float / open centre" 14 "Reserved" 15 "Don't care" ;
VAL_ 2566869026 EHR_EvTemp 255 "Error" ;
VAL_ 2566869026 EHR_EvFlow 255 "N/A" ;
VAL_ 2566869026 EHR_Op_2 2 "Reserved" 1 "Reserved" 0 "Goto Fialsafe" 3 "Normal Operation" ;
VAL_ 2566869026 EHR_Op_1 0 "Calibration active" 1 "Reserved" 2 "Error" 3 "Normal Operation" ;
VAL_ 2566869026 EHR_DynRmpTime 255 "N/A" ;
VAL_ 2566869026 EHR_CrvShp 0 "Curve Shape 0h" 1 "Curve Shape 1h" 2 "Curve Shape 2h" 3 "Curve Shape 3h" 4 "Curve Shape 4h" 5 "Curve Shape 5h" 6 "Curve Shape 6h" 7 "Curve Shape 7h" 8 "Curve Shape 8h" 9 "Curve Shape 9h" 10 "Curve Shape Ah" 11 "Curve Shape Bh" 12 "Curve Shape Ch" 13 "Curve Shape Dh" 14 "Curve Shape Eh" 15 "Curve Shape Fh" ;
VAL_ 2566869026 EHR_CrvGrad 255 "Error" ;
VAL_ 2566869026 EHR_Init 3 "Reserved" 2 "Reserved" 1 "Cranking" 0 "Operation" ;
VAL_ 2565537570 PGN_RQST_22 65235 "DM11Req" 65228 "DM3Req" 65227 "DM2Req" 60928 "ACL" ;
VAL_ 2566841634 EngTotHourOp -2 "Error" -1 "N/A" ;
VAL_ 2564432633 FlowSts 0 "Continue To Send" 1 "Wait " 2 "Overflow" ;
VAL_ 2564432633 ProtocCntrlInfo 0 "Single frame" 1 "First frame" 2 "Consecutive frame" 3 "Flow control " ;
VAL_ 2564487458 ProtocCntrlInfo 0 "Single frame" 1 "First frame" 2 "Consecutive frame" 3 "Flow control " ;
VAL_ 2564487458 FlowSts 0 "Continue To Send" 1 "Wait " 2 "Overflow" ;
VAL_ 2565799929 ArbAddrCap 0 "No" 1 "Yes" ;
VAL_ 2565799929 IndstryGrp 7 "NotAvailable" 5 "Reserved" 4 "Marine" 3 "Construction" 2 "AgriculturalAndForestry" 1 "OnHighway" 0 "Global" ;
VAL_ 2565799929 Funct 57 "Steering Column Unit" 58 "Fan Drive Control" 59 "Starter" 60 "Cab Display" 61 "File Server/Printer" 62 "On-Board Diagnostic Unit" 63 "Engine Valve Controller" 64 "Endurance Braking" 65 "Gas Flow Measurement" 66 "I/O Controller" 67 "Electrical System Controller" 68 "Aftertreatment system gas measurement" 69 "Engine Emission Aftertreatement System" 30 "Management Computer" 31 "Propulsion Battery Charger" 104 "Reserved" 105 "Reserved" 106 "Reserved" 70 "Auxiliary Regeneration Device" 71 "Transfer Case Control" 72 "Coolant Valve Controller" 73 "Rollover Detection Control" 74 "Lubrication System" 75 "Supplemental Fan" 76 "Temperature Sensor" 77 "Fuel Properties Sensor" 78 "Fire Suppression System" 79 "Reserved" 80 "Reserved" 81 "Reserved" 82 "Reserved" 83 "Reserved" 84 "Reserved" 85 "Reserved" 86 "Reserved" 87 "Reserved" 88 "Reserved" 89 "Reserved" 90 "Reserved" 91 "Reserved" 92 "Reserved" 93 "Reserved" 94 "Reserved" 95 "Reserved" 96 "Reserved" 97 "Reserved" 98 "Reserved" 99 "Reserved" 100 "Reserved" 0 "Engine" 1 "Auxiliary Power Unit (APU)" 2 "Electric Propulsion Control" 3 "Transmission" 4 "Battery Pack Monitor" 5 "Shift Control/Console" 6 "Power TakeOff - (Main or Rear)" 7 "Axle - Steering" 8 "Axle - Drive" 9 "Brakes - System Controller" 10 "Brakes - Steer Axle" 11 "Brakes - Drive Axle" 12 "Retarder - Engine" 13 "Retarder - Driveline" 14 "Cruise Control" 15 "Fuel System" 16 "Steering Controller" 17 "Suspension - Steer Axle" 18 "Suspension - Drive Axle" 19 "Instrument Cluster" 20 "Trip Recorder" 21 "Cab Climate Control" 22 "Aerodynamic Control" 23 "Vehicle Navigation" 24 "Vehicle Security" 107 "Reserved" 108 "Reserved" 109 "Reserved" 110 "Reserved" 111 "Reserved" 112 "Reserved" 113 "Reserved" 114 "Reserved" 115 "Reserved" 116 "Reserved" 117 "Reserved" 118 "Reserved" 119 "Reserved" 120 "Reserved" 121 "Reserved" 122 "Reserved" 123 "Reserved" 124 "Reserved" 125 "Reserved" 126 "Reserved" 127 "Reserved" 25 "Network Interconnect ECU" 26 "Body Controller" 27 "Power TakeOff (Secondary or Front)" 28 "Off Vehicle Gateway" 29 "Virtual Terminal (in cab)" 43 "Transmission Display" 44 "Exhaust Emission Control" 45 "Vehicle Dynamic Stability Control" 46 "Oil Sensor Unit" 47 "Information System Controller" 48 "Ramp Control" 49 "Clutch/Converter Control" 50 "Auxiliary Heater" 51 "Forward-Looking Collision Warning System" 52 "Chassis Controller" 53 "Alternator/Charging System" 54 "Communications Unit, Cellular" 55 "Communications Unit, Satellite" 56 "Communications Unit, Radio" 32 "Headway Controller" 33 "System Monitor" 34 "Hydraulic Pump Controller" 35 "Suspension - System Controller" 36 "Pneumatic - System Controller" 37 "Cab Controller" 38 "Tire Pressure Control" 39 "Ignition Control Module" 40 "Seat Control" 41 "Lighting - Operator Controls" 42 "Water Pump Control" 101 "Reserved" 102 "Reserved" 103 "Reserved" ;
VAL_ 2565799929 ManufctCod 195 "General Engine Products" 196 "LEMKEN GmbH & Co. KG" 197 "Mechron Power Systems" 198 "Mystic Valley Communications" 199 "Actia Corp." 200 "MGM Brakes" 201 "Disenos y Tecnologia S.A." 202 "Curtis Instruments, Inc." 203 "MILtronik GmbH" 204 "The Morey Corporation" 205 "SmarTire Systems Inc" 206 "port GmbH" 207 "Otto Engineering" 208 "Drew Technologies, Inc." 209 "Bell Equip. Co. SA (PTY) LTD" 210 "Iteris, Inc." 211 "DNA Group" 212 "Sure Power Industries, Inc." 213 "CNH Belgium N.V." 214 "MC elettronica Srl" 215 "Aetna Engineering/Fireboy-Xintex" 216 "Paneltronics Inc." 217 "RM Michaelides Software & Elektronik GmbH" 218 "Gits Manufacturing Company" 219 "Cat OEM Solutions" 220 "Beede Electrical Instrument Company, Inc." 221 "SiE" 222 "Generac Power Systems, Inc." 1850 "Teleflex" 1851 "Raymarine" 1852 "Navionics" 1853 "Japan Radio Co." 1854 "Northstar Technologies" 1855 "Furuno USA" 1856 "Trimble" 1857 "Simrad" 1858 "Litton" 1859 "Kvasar AB" 1860 "MMP" 1861 "Vector CANtech" 1862 "Sanshin" 1863 "Thomas G. Faria Co." 232 "TSD Integrated Controls" 234 "Mondial electronic GmbH" 235 "SailorMade Marine Telemetry - Tetra Technology Ltd." 236 "Norac Systems International Inc" 237 "Agtron Enterprises Inc" 238 "ZF Friedrichshafen AG" 239 "May & Scofield Ltd" 240 "Vanair Mfg" 241 "Schneider Automation SAS " 242 "Kokusandenki Co. Ltd" 243 "eRide, Inc." 244 "Techno-Matic" 245 "Capstan Ag Systems, Inc." 246 "Class 1, Inc" 247 "ePULSE" 248 "Cooper Standard Automotive Active Systems Group" 264 "Autolync" 265 "MTS Sensor Technologie GmbH" 266 "International Thermal Research Ltd" 114 "EControls, Inc." 115 "NACCO Materials Handling Group, Inc." 116 "BEELINE Technologies" 117 "HUSCO International" 118 "Intron GmbH" 119 "IntegriNautics" 120 "RDS Technology Ltd." 121 "HED (Hydro Electronic Devices, Inc.)" 122 "FG Wilson (Engineering) Limited" 123 "Basler Electric" 124 "Hydac Electronic" 125 "Nevada Automotive Test Center" 126 "Driver Tech" 127 "Holland USA" 128 "Gerhard Duecker GmbH & Co. KG" 129 "OMNEX Control Systems, Inc." 130 "Nido - Universal Machines B.V." 131 "ITT Industries" 132 "Mulag-Fahrzeugwerk" 133 "Bucher Schoerling GmbH" 134 "Iris Technology Ltd." 135 "Airmar Technology Corporation" 136 "Komatsu Ltd." 137 "Maretron" 138 "Georg Fritzmeier GmbH & Co. KG" 139 "Caterpillar Trimble Control Technologies (CTCT), LLC" 140 "Lowrance Electronics, Inc." 141 "Thales Navigation Ltd." 142 "TRW Automotive (Commercial Steering Systems)" 143 "W. Gmeiner GmbH & Co." 144 "Mercury Marine" 145 "MurCal Controls" 146 "Maxima Technologies" 147 "Nautibus Electronic GmbH" 148 "Blue Water Data, Inc." 149 "Holset" 150 "Fleetguard" 151 "Raven Industries Inc. - Flow Controls Division" 152 "elobau GmbH & Co. KG" 153 "Woodward, Industrial Controls Division" 154 "Westerbeke Corporation" 155 "Vetronix Corporation" 156 "ITT Industries - Cannon" 157 "ISSPRO Inc." 158 "Firestone Industrial Products Company" 159 "NTech Industries Inc." 160 "Nido" 161 "Offshore Systems (UK) Limited" 162 "Axiomatic Technologies" 163 "BRP Inc." 164 "DaimlerChrysler Off-Highway" 165 "CPAC Systems AB" 166 "Phoenix International" 167 "JLG Industries Inc." 168 "Xantrex" 169 "Marlin Technologies Inc." 170 "Computronics Corporation Ltd." 171 "Wachendorff Elektronik GmbH & Co. KG" 172 "Yanmar Marine USA" 173 "Ryeso, Inc." 174 "AB Volvo Penta" 175 "Veris Technologies, Inc." 176 "Moritz Aerospace" 177 "Diagnostic System Associates" 178 "Siemens VDO Automotive AG" 179 "TeeJet Technologies Denmark" 180 "Smart Power Systems" 181 "Coretronics, Inc." 182 "Vehicle Systems Engineering B.V." 183 "KDS Controls, Inc." 184 "EIA Electronics" 185 "Beede Electrical Instrument Company" 186 "Altronic, Inc." 187 "Air-Weigh" 188 "EMP Corp." 189 "QUALCOMM" 190 "Hella KGaA Hueck & Co." 191 "XRS Corporation" 192 "Floscan" 193 "Nobletec" 194 "TriMark Corporation" 378 "Glendinning Marine Products" 379 "Yamabiko Corporation" 380 "Suntech International Ltd." 382 "National Agricultural and Food Research Organization" 383 "MCL Industries" 384 "Camano Light" 385 "Johnson Outdoor Marine Electronics" 386 "JLG Automation BVBA" 387 "Orscheln Products, LLC" 388 "Innomatix, LLC" 389 "Benchmark Electronics, Minnesota Division" 390 "Partech Inc." 391 "Electronic Design for Industry, Inc" 392 "Tianyuan Technology Co Ltd." 393 "Harvest Tec, Inc" 394 "Capi 2 Nederland BV" 395 "GENTEC S.R.L." 396 "Beyond Measure" 397 "Sanyo-kiki Co Ltd." 398 "Hilite International" 399 "ISEKI & Co., Ltd." 400 "Livorsi Marine" 401 "Torqeedo GmbH" 402 "Simma Software, Inc." 403 "Trackwell ADS, Inc." 404 "Com Nav Marine Ltd" 405 "Wema System AS" 406 "Vecima Networks Inc." 407 "Comtech Mobile Datacom" 408 "Corvus Energy Ltd." 409 "Transfluid S.r.L." 410 "COBO S.p.A. Divisione 3B6" 411 "Hy-Drive Technologies Ltd." 412 "WebTech Wireless Inc." 413 "Datapross Nijbroek bv" 414 "Cattron Group International" 415 "Valid Manufacturing Ltd." 416 "Kubota Corporation" 417 "KZValve" 418 "Intellistick Inc" 419 "Fusion Electronics Ltd" 420 "Vermeer Corporation, ACS Group" 421 "Vertex Standard Co., Ltd" 422 "True Heading AB" 423 "BSM Wireless, Inc." 424 "Odyne LLC" 425 "Methode Electronics Inc, MDI" 426 "Egersund Marine Electronics AS" 427 "em-trak Marine Electronics Ltd" 428 "Mfg_428" 429 "Rota Engineering Ltd." 455 "ADZ NAGANO GmbH" 456 "General Kinetics" 457 "RUSELPROM-ElectricDrive Ltd" 458 "Control Solutions, Inc." 459 "Alltek Marine Electronics Corp" 1098 "Preh GmbH" 593 "Sensata Technologies" 460 "San Giorgio S.E.I.N." 267 "Red Lion Controls, Inc" 268 "Accurate Technologies" 269 "Saft America Inc.,  Space & Defense Division" 270 "Tennant" 271 "Cole Hersee" 312 "Lectronix, Inc." 313 "Ilmor Engineering, Inc" 314 "CSM GmbH" 315 "Icom Incorporated" 316 "ITT Flow Control" 317 "Navtronics Bvba" 318 "SAT Plan" 319 "Cadec Global" 320 "Miedema Landbouwwerktuigenfabriek B.V." 321 "Ultra Electronics, Electrics" 322 "MICHENKA s.r.o." 323 "Mobileye Vision Technologies Ltd." 324 "Snap-on Diagnostics" 325 "ASM Automation Sensorik Messtechnik GmbH" 326 "Akron Brass Company" 327 "Sonceboz SA" 272 "Gross Mechanical Laboratories, Inc" 273 "Active Research Limited" 274 "LTW Technology Co., LTD" 275 "Navico Egersund AS" 276 "Aqua-Hot Heating Systems" 277 "LHP Telematics" 278 "Takata Electronics" 279 "Geometris LP" 280 "Leica Geosystems Pty Ltd" 299 "Rauch Landmaschinen GmbH" 300 "Systron Donner Automotive" 301 "Parker Hannifin (UK) Ltd FDE group" 302 "Nissin Kogyo Co., LTD" 303 "CTS Corporation" 304 "EmpirBus AB" 305 "NovAtel Inc" 306 "Sleipner Motor AB" 307 "MBW Technologies" 308 "Cyntrx" 309 "Krauss-Maffei Wegmann GmbH & Co. KG" 310 "TECNORD srl" 311 "Patrick Power Products" 281 "Precision Governors LLC" 282 "Medallion Instrumentation Systems" 283 "CWF Hamilton & Co Ltd" 284 "Mobile Tech Chile" 285 "Sea Recovery Corp" 286 "Coelmo srl" 287 "NTech Industries, Inc" 288 "Mitsubishi FUSO Truck & Bus Corp." 289 "Watlow" 290 "Kuebler GmbH" 291 "Groeneveld Transport Efficiency BV" 292 "IKUSI - Angel Iglesias S.A." 293 "Spyder Controls Corp." 294 "Grayhill Inc." 295 "BEP Marine" 296 "micro dynamics GmbH" 297 "Zonar Systems Inc" 298 "Holley Performance" 253 "Mobile Control Systems" 254 "GE Sensing" 255 "MEAS France" 256 "Tyco Electronics AMP" 257 "Honda Motor Co., Ltd" 258 "ARAG" 259 "Jetter AG" 260 "Reichhardt GmbH" 261 "Red Dot Corporation" 262 "HydraForce, Inc" 263 "IMMI" 223 "Vaueo Retarder Co., Ltd." 224 "EMMI Network, S.L." 225 "SKF" 226 "Monaco Coach Corporation" 227 "Lykketronic A/S" 228 "ZF Marine Electronics" 229 "Garmin International Inc." 230 "Saucon Technologies" 231 "Topcon Positioning Systems, Inc." 0 "Reserved" 1 "Allied Signal Inc." 2 "Allison Transmission, GMC" 3 "Ametek, US Gauge Division" 4 "Ametek-Dixson" 5 "AMP Inc." 6 "Berifors Electronics AB" 7 "Case Corp." 8 "Caterpillar Inc." 9 "Chrysler Corp." 10 "Cummins Engine Co." 11 "Dearborn Group Inc." 12 "Deere & Company, Precision Farming" 13 "Delco Electronics" 14 "Detroit Diesel Corporation" 15 "Dickey-John Corp." 16 "Eaton Corp." 17 "Eaton Corp. Res & Dev" 18 "Eaton Corp, Transmission Division" 19 "Eaton Corp. Trucking Info Services" 20 "Eaton Ltd" 21 "Echilin Inc., Midland Brake Inc." 22 "Ford Motor Co., Electronic Concepts $ Systems" 23 "Ford Motor Co., Heavy Truck" 24 "Ford Motor Co., Vehicle Controls" 25 "Daimler Trucks North America LLC" 26 "General Motors Corp., Service Technology Group" 27 "GMC" 28 "Grote Ind. Inc." 29 "Hino Motors Ltd." 30 "Isuzu Motors Ltd." 31 "J Pollak Corp." 32 "Jacobs Vehicle Systems" 33 "John Deere" 34 "Kelsey Hayes Co." 35 "Kenworth Truck Co." 36 "Lucas Ltd." 37 "Mack Trucks Inc." 38 "Micro Processor Systems Inc." 39 "Microfirm Inc." 40 "Motorola AIEG Inc." 41 "Motorola Inc." 42 "International Truck and Engine Corp. Engine Electronics" 43 "International Truck and Engine Corp. Vehicle Electronics" 233 "Yacht Monitoring Solutions Inc." 249 "Schaltbau GmbH" 250 "Kuhn Group" 251 "German Agricultural Society" 252 "Sensor-Technik Wiedemann GmbH" 328 "Qwerty Electronik AB" 329 "Deif A/S" 330 "Kidde Aerospace and Defense" 331 "Horton, Inc." 332 "HWH Corporation" 333 "Hadley Products Corporation" 334 "Takata-Petri AG" 335 "Evo Electric Ltd" 336 "APE s.r.o." 337 "Carraro S.p.A." 338 "GRAF-SYTECO" 339 "Competence Center ISOBUS e.V." 340 "Continental AG" 341 "Boning GmbH & Co" 342 "THOMAS MAGNETE GmbH" 343 "Baumer Group" 344 "Parvus Corporation" 345 "Korean Maritime University" 346 "Control Solutions" 347 "Honeywell" 348 "Amazonen Werke H. Dreyer" 349 "Suonentiet" 350 "Noris Marine Systems GmbH & Co KG" 351 "Thrane & Thrane" 352 "SAME DEUTZ-FAHR" 353 "Hegemon Electronics, Inc." 354 "Junkkari OY" 355 "Mastervolt International B.V." 356 "Fischer Panda Generators, Inc" 357 "Hardi International A/S" 358 "Victron Energy BV" 359 "Ludwig Bergmann GmbH" 360 "HJS Emission Technology GmbH & Co KG" 361 "InMach" 362 "Alois Poettinger Maschinenfabrik GmbH" 363 "BEI Duncan" 364 "OEM Controls Inc." 365 "Digi-Star, LLC" 366 "Viewnyx Corp." 367 "Fliegl Agrartechnik" 368 "HANSENHOF_electronic" 369 "Power Torque Engineering Ltd" 370 "Rolls-Royce Marine AS" 371 "Heinzmann GmbH & Co. KG" 373 "Electronic Design Inc." 374 "Northern Lights, Inc." 381 "B&G" 372 "Delphi" 375 "Williams Controls Inc." 376 "Quake Global" 454 "NGK Spark Plug Co. Ltd" 480 "EnerDel, Inc." 481 "Chetco Digital Instruments" 482 "Tricon Electronics" 483 "Valeo" 484 "Headsight Inc." 485 "MATT automotive" 377 "ifm electronic gmbh" 44 "Nippondenso Co. Ltd." 45 "PACCAR" 46 "Noregon Systems, Inc" 47 "Phillips Semiconductor" 48 "Pollak Alphabet" 49 "RE America Inc." 50 "Robert Bosch Corp" 51 "Robert Bosch GmbH" 52 "Meritor Automotive, Inc." 53 "Continental Automotive Systems US, Inc." 54 "Meritor Wabco" 55 "Ryder System Inc." 56 "SAIC" 57 "Sauer-Danfoss Co." 58 "SPX Corporation, OTC Division" 59 "VES Inc." 60 "Volvo Trucks North America Inc." 61 "Volvo Truck Corp." 62 "Wabco" 63 "ZF Industries Inc." 64 "unused" 65 "MAN Nutzfahrzeuge AG" 66 "John Deere Construction Equipment Division" 67 "Funk Manufacturing Company" 68 "Scania" 69 "Trimble Navigation" 70 "Flex-Coil Limited" 71 "Vansco Electronics Ltd." 72 "Sisu Corporation" 73 "LeTourneau, Inc." 74 "Eaton Axle-Brake Division" 75 "Deere & Co. Agricultural Division" 76 "unused" 77 "Deere Power Systems Group" 78 "Frank W. Murphy Manufacturing, Inc." 79 "Daimler Benz AG - Engine Division (PBM)" 80 "Twin Disc, Inc." 81 "Fire Research Corp" 82 "Bobcat/Ingersoll-Rand" 83 "Bendix VORAD Technologies" 84 "New Holland UK Limited" 85 "Kohler Co." 86 "C.E. Niehoff & Company" 87 "J.C. Bamford Excavators Ltd (JCB)" 88 "Satloc Precision GPS" 89 "Kverneland Group, Electronics Division" 90 "Knorr-Bremse SfN GmbH" 91 "BSG Bodensee Steuergeraete GmbH" 92 "Ag-Chem Equipment Co., Inc." 93 "Perkins Engines Company Ltd." 94 "CNH Global N.V." 95 "Pacific Insight Electronics Corp." 96 "Mech@tronic IT GmbH" 97 "Ag Leader Technology, Inc." 98 "Mueller-Elektronik GmbH & Co." 99 "International Transmissions Ltd (ITL)" 100 "VDO Technik AG" 101 "Sensoria" 102 "AGCO GmbH & Co." 103 "CLAAS Agrosystems GmbH & Co. KG" 104 "Claas Selbstfahrende Erntemaschinen GmbH" 105 "Kiepe Elektrik GmbH & Co. KG" 106 "BAE Systems Controls, Inc." 107 "Grimme Landmaschinen GmbH & Co. KG" 108 "WTK-Elecktronik GmbH" 109 "TeeJet Technologies Denmark" 110 "EPIQ Sensor-Nite" 111 "Maschinenfabrik Bernard Krone GmbH" 112 "MECALAC" 113 "Stress-Tek, Inc." 461 "HAWE Hydraulik SE" 462 "IHI Shibaura Machinery Corporation" 463 "PROBOTIQ" 464 "Leach International Corporation" 465 "Ashcroft Inc" 466 "Veethree Electronics and Marine LLC" 467 "Lely Industries N.V." 468 "Tyco Fire Protection Products" 469 "RA Consulting GmbH" 470 "SI-TEX Marine Electronics" 471 "Sea Cross Marine AB" 472 "Tenneco Inc." 473 "Boss Industries, Inc." 474 "Persen Technologies Inc." 475 "GME" 476 "Hummingbird Marine Electronics" 477 "OilQuick AB" 478 "OceanSat BV" 479 "Vapor Bus International" 430 "Auteq Telematica S.A." 431 "Tohatsu Corporation" 432 "S&A Systems, Inc." 433 "Rowe Electronics" 434 "Stored Energy Systems" 435 "Zunhammer GmbH" 436 "Kinze Manufacturing" 437 "Digital Yacht Limited" 438 "Comar Systems Ltd" 439 "Hyundai Heavy Industries" 440 "Cummins Power Generation" 441 "PTG Reifendruckregelsysteme GmbH" 442 "Horsch Maschinen GmbH" 443 "SignalQuest, Inc." 444 "ITT Power Solutions" 445 "KAT MECHATRONIC, Electronic Product Division" 446 "CertTech, L.L.C." 447 "Great Plains Mfg." 448 "Stanadyne Corporation, Electronics Systems" 449 "Polaris Industries Inc" 450 "Dycor Technologies Ltd." 451 "Parker Hannifin Corp" 452 "WIKA Alexander Wiegand SE & Co. KG" 453 "Cooper Bussmann" 486 "Westport Innovations Inc." 487 "DSE Test Solutions A/S" 488 "The Charles Machine Works, Inc." 489 "Appareo Systems" 490 "QuikQ" 491 "Penny and Giles Ltd" 492 "Inergy Automotive Systems" 493 "Watcheye" 494 "Synerject" 495 "HOLMER Maschinenbau GmbH" 496 "W. Gessmann GmbH" 497 "SENTRON Sistemas Embarcados" 498 "Innovative Design Solutions, Inc." 499 "LCJ Capteurs" 500 "Oxbo International Corporation" 501 "Agrotronix S.A." 502 "Attwood Corporation" 503 "Naviop S.R.L." 504 "Vesper Marine" 505 "Yetter Farm Equipment" 506 "IHI STAR Machinery Corporation" 507 "Test Center ISOBUS" 508 "Transtech Innovations" 509 "MOTORTECH GmbH" 510 "Marinesoft Co. Ltd" 511 "Sulky" 512 "Inpower LLC" 513 "FarmscanAg" 514 "DISTek Integration, Inc." 515 "GINAF Trucks Nederland B.V." 516 "AVAT Automation GmbH" 517 "Noland Engineering" 518 "Transas USA Inc." 519 "Peeters Landbouwmachines b.v." 520 "Trapeze" ;
VAL_ 2565537785 PGN_RQST_F9 65235 "DM11" 64965 "ECUID" 65259 "CI" 65242 "SOFT" 65227 "DM2" 65228 "DM3" 60928 "ACL" ;
VAL_ 2566841896 Month 1 "January" 2 "February" 3 "March" 4 "April" 5 "May" 6 "June" 7 "July" 8 "August" 9 "September" 10 "October" 11 "November" 12 "December" 254 "Error" 255 "Not Available" ;
VAL_ 2564459001 FlowSts 0 "Continue To Send" 1 "Wait " 2 "Overflow" ;
VAL_ 2564459001 ProtocCntrlInfo 0 "Single frame" 1 "First frame" 2 "Consecutive frame" 3 "Flow control " ;
VAL_ 2564487561 FlowSts 0 "Continue To Send" 1 "Wait " 2 "Overflow" ;
VAL_ 2564487561 ProtocCntrlInfo 0 "Single frame" 1 "First frame" 2 "Consecutive frame" 3 "Flow control " ;
VAL_ 2564457721 FlowSts 0 "Continue To Send" 1 "Wait " 2 "Overflow" ;
VAL_ 2564457721 ProtocCntrlInfo 0 "Single frame" 1 "First frame" 2 "Consecutive frame" 3 "Flow control " ;
VAL_ 2564487556 FlowSts 0 "Continue To Send" 1 "Wait " 2 "Overflow" ;
VAL_ 2564487556 ProtocCntrlInfo 0 "Single frame" 1 "First frame" 2 "Consecutive frame" 3 "Flow control " ;
VAL_ 2564457465 FlowSts 0 "Continue To Send" 1 "Wait " 2 "Overflow" ;
VAL_ 2564457465 ProtocCntrlInfo 0 "Single frame" 1 "First frame" 2 "Consecutive frame" 3 "Flow control " ;
VAL_ 2564487555 FlowSts 0 "Continue To Send" 1 "Wait " 2 "Overflow" ;
VAL_ 2564487555 ProtocCntrlInfo 0 "Single frame" 1 "First frame" 2 "Consecutive frame" 3 "Flow control " ;
VAL_ 2564457209 FlowSts 0 "Continue To Send" 1 "Wait " 2 "Overflow" ;
VAL_ 2564457209 ProtocCntrlInfo 0 "Single frame" 1 "First frame" 2 "Consecutive frame" 3 "Flow control " ;
VAL_ 2564487554 FlowSts 0 "Continue To Send" 1 "Wait " 2 "Overflow" ;
VAL_ 2564487554 ProtocCntrlInfo 0 "Single frame" 1 "First frame" 2 "Consecutive frame" 3 "Flow control " ;
VAL_ 2564456953 FlowSts 0 "Continue To Send" 1 "Wait " 2 "Overflow" ;
VAL_ 2564456953 ProtocCntrlInfo 0 "Single frame" 1 "First frame" 2 "Consecutive frame" 3 "Flow control " ;
VAL_ 2566845952 EngIntakManifld_1Prs 254 "Error" 255 "N/A" ;
VAL_ 2566845952 EngIntakManifld_1Temp 255 "N/A" 254 "Error" ;
VAL_ 2566845952 EngExhTemp 65535 "Not available" 65024 "Error" ;
VAL_ 2364539904 EngTorqMode 15 "Not available" 14 "VCM_speed_demand" 13 "VCM_torque_demand" 12 "Fuel_limiting" 11 "Not defined" 10 "Retarder_control (not used)" 7 "ABS_control (not used)" 0 "Idling (default)" 1 "Acc_Pedal_Gov(onlyOneBoxApplic)" 2 "Cruise_control (not used)" 3 "PTO_gov (not used)" 4 "Road_speed_limiter (not used)" 5 "ASR_control (not used)" 6 "Trans_control  (not used)" 8 "Torque_limiter" 9 "High_speed_gov" ;
VAL_ 2364539904 ActlEng_pcTorqFrac 15 "No action" 14 "No action" 13 "No action" 12 "No action" 11 "No action" 10 "No action" 9 "No action" 8 "No action" 7 "additional torque +0.875%" 6 "additional torque +0.750%" 5 "additional torque +0.625%" 4 "additional torque +0.500%" 3 "additional torque +0.375%" 2 "additional torque +0.250%" 1 "additional torque +0.125%" 0 "additional torque +0.000%" ;
VAL_ 2364539904 DrivRqstEng_pcTorq 254 "Error" 255 "N/A" ;
VAL_ 2364539904 ActlEng_pcTorq 254 "Error" 255 "N/A" ;
VAL_ 2364539904 EngSpd 65024 "Error" 65535 "N/A" ;
VAL_ 2364539904 SA_CntrlDevEngCntrl 254 "Error" 255 "N/A" ;
VAL_ 2364539904 EngStartMode 6 "strtrInhbtdDTDrvlnEnggd(notUsed)" 5 "strtrInhDTEngNtReady4Sta(notUse)" 4 "strtrInhbtdDToEngAlreadyRunning" 3 "StarterFinished" 2 "StarterActiveGearEngaged" 1 "StarterActiveGearNotEngaged" 0 "StartNotRqed" 15 "notAvailable" 14 "error" 12 "starterInhibitedReasonUnknown" 7 "strtrInhbtdDToActiveImmobilizer" ;
VAL_ 2364539904 EngRqst_pcTorq 254 "Error" 255 "N/A" ;
VAL_ 2364539648 AccPed_1LoIdleSw 0 "Accelerator pedal 1 not in low idle condition" 1 "Accelerator pedal 1 in low idle condition" 2 "Error" 3 "Not available" ;
VAL_ 2364539648 AccPedKickdnSw 0 "Kickdown passive" 1 "Kickdown active" 2 "Error" 3 "Not available" ;
VAL_ 2364539648 RoadSpdLimSts 0 "Active" 1 "Not Active" 2 "Error" 3 "Not available" ;
VAL_ 2364539648 AccPed_2LoIdleSw 0 "Accelerator pedal 2 not in low idle condition" 1 "Accelerator pedal 2 in low idle condition" 2 "Error" 3 "Not available" ;
VAL_ 2364539648 Eng_pcLoadCurrSpd 254 "Error" 255 "N/A" ;
VAL_ 2364539648 VehAccelRateLimSts 0 "Limit not active" 1 "Limit active" 2 "Reserved" 3 "Not available" ;
VAL_ 2364539648 MomentEngMaxPwrEnaFdbk 0 "disabled" 1 "supported" 2 "reserved" 3 "dont care" ;
VAL_ 2364539648 DPF_ThermManageActv 0 "DPF Thermal Management is not active" 1 "DPF Thermal Management is active" 2 "Reserved" 3 "Dont care" ;
VAL_ 2364539648 SCR_ThermManageActv 0 "SCR Thermal Management is not active" 1 "SCR Thermal Management is active" 2 "Reserved" 3 "Dont care" ;
VAL_ 2566843904 EngCoolntTemp 254 "Error" 255 "N/A" ;
VAL_ 2566843904 EngFuelTemp_1 254 "Error" 255 "N/A" ;
VAL_ 2566843904 EngOilTemp_1 65024 "Error" 65535 "N/A" ;
VAL_ 2566841600 EngTotHourOp -2 "Error" -1 "N/A" ;
